VERSION ""

NS_ :

BS_:

BU_: Consumer Producer
VAL_TABLE_ InvertedByte 129 "orig: 126 / 0x7E" 255 "orig: 0 / 0x0" 254 "orig: 1 / 0x1" 253 "orig: 2 / 0x2" 252 "orig: 3 / 0x3" 251 "orig: 4 / 0x4" 250 "orig: 5 / 0x5" 249 "orig: 6 / 0x6" 248 "orig: 7 / 0x7" 247 "orig: 8 / 0x8" 246 "orig: 9 / 0x9" 245 "orig: 10 / 0xA" 244 "orig: 11 / 0xB" 243 "orig: 12 / 0xC" 242 "orig: 13 / 0xD" 241 "orig: 14 / 0xE" 240 "orig: 15 / 0xF" 239 "orig: 16 / 0x10" 238 "orig: 17 / 0x11" 237 "orig: 17 / 0x12" 236 "orig: 19 / 0x13" 235 "orig: 20 / 0x14" 234 "orig: 21 / 0x15" 233 "orig: 22 / 0x16" 232 "orig: 23 / 0x17" 231 "orig: 24 / 0x18" 230 "orig: 25 / 0x19" 229 "orig: 26 / 0x1A" 228 "orig: 27 / 0x1B" 227 "orig: 28 / 0x1C" 226 "orig: 29 / 0x1D" 225 "orig: 30 / 0x1E" 224 "orig: 31 / 0x1F" 223 "orig: 32 / 0x20" 222 "orig: 33 / 0x21" 221 "orig: 34 / 0x22" 220 "orig: 35 / 0x23" 219 "orig: 36 / 0x24" 218 "orig: 37 / 0x25" 217 "orig: 38 / 0x26" 216 "orig: 39 / 0x27" 215 "orig: 40 / 0x28" 214 "orig: 41 / 0x29" 213 "orig: 42 / 0x2A" 212 "orig: 43 / 0x2B" 211 "orig: 44 / 0x2C" 210 "orig: 45 / 0x2D" 209 "orig: 46 / 0x2E" 208 "orig: 47 / 0x2F" 207 "orig: 48 / 0x30" 206 "orig: 49 / 0x31" 205 "orig: 50 / 0x32" 204 "orig: 51 / 0x33" 203 "orig: 52 / 0x34" 202 "orig: 53 / 0x35" 201 "orig: 54 / 0x36" 200 "orig: 55 / 0x37" 199 "orig: 56 / 0x38" 198 "orig: 57 / 0x39" 197 "orig: 58 / 0x3A" 196 "orig: 59 / 0x3B" 195 "orig: 60 / 0x3C" 194 "orig: 61 / 0x3D" 193 "orig: 62 / 0x3E" 192 "orig: 63 / 0x3F" 191 "orig: 64 / 0x40" 190 "orig: 65 / 0x41" 189 "orig: 66 / 0x42" 188 "orig: 67 / 0x43" 187 "orig: 68 / 0x44" 186 "orig: 69 / 0x45" 185 "orig: 70 / 0x46" 184 "orig: 71 / 0x47" 183 "orig: 72 / 0x48" 182 "orig: 73 / 0x49" 181 "orig: 74 / 0x4A" 180 "orig: 75 / 0x4B" 179 "orig: 76 / 0x4C" 178 "orig: 77 / 0x4D" 177 "orig: 78 / 0x4E" 176 "orig: 79 / 0x4F" 175 "orig: 80 / 0x50" 174 "orig: 81 / 0x51" 173 "orig: 82 / 0x52" 172 "orig: 83 / 0x53" 171 "orig: 84 / 0x54" 170 "orig: 85 / 0x55" 169 "orig: 86 / 0x56" 168 "orig: 87 / 0x57" 167 "orig: 88 / 0x58" 166 "orig: 89 / 0x59" 165 "orig: 90 / 0x5A" 164 "orig: 91 / 0x5B" 163 "orig: 92 / 0x5C" 162 "orig: 93 / 0x5D" 161 "orig: 94 / 0x5E" 160 "orig: 95 / 0x5F" 159 "orig: 96 / 0x60" 158 "orig: 97 / 0x61" 157 "orig: 98 / 0x62" 156 "orig: 99 / 0x63" 155 "orig: 100 / 0x64" 154 "orig: 101 / 0x65" 153 "orig: 102 / 0x66" 152 "orig: 103 / 0x67" 151 "orig: 104 / 0x68" 150 "orig: 105 / 0x69" 149 "orig: 106 / 0x6A" 148 "orig: 107 / 0x6B" 147 "orig: 108 / 0x6C" 146 "orig: 109 / 0x6D" 145 "orig: 110 / 0x6E" 144 "orig: 111 / 0x6F" 143 "orig: 112 / 0x70" 142 "orig: 113 / 0x71" 141 "orig: 114 / 0x72" 140 "orig: 115 / 0x73" 139 "orig: 116 / 0x74" 138 "orig: 117 / 0x75" 137 "orig: 118 / 0x76" 136 "orig: 119 / 0x77" 135 "orig: 120 / 0x78" 134 "orig: 121 / 0x79" 133 "orig: 122 / 0x7A" 132 "orig: 123 / 0x7B" 131 "orig: 124 / 0x7C" 130 "orig: 125 / 0x7D" 128 "orig: 127 / 0x7F" 127 "orig: 128 / 0x80" 126 "orig: 129 / 0x81" 125 "orig: 130 / 0x82" 124 "orig: 131 / 0x83" 123 "orig: 132 / 0x84" 122 "orig: 133 / 0x85" 121 "orig: 134 / 0x86" 120 "orig: 135 / 0x87" 119 "orig: 136 / 0x88" 118 "orig: 137 / 0x89" 117 "orig: 138 / 0x8A" 116 "orig: 139 / 0x8B" 115 "orig: 140 / 0x8C" 114 "orig: 141 / 0x8D" 113 "orig: 142 / 0x8E" 112 "orig: 143 / 0x8F" 111 "orig: 144 / 0x90" 110 "orig: 145 / 0x91" 109 "orig: 146 / 0x92" 108 "orig: 147 / 0x93" 107 "orig: 148 / 0x94" 106 "orig: 149 / 0x95" 105 "orig: 150 / 0x96" 104 "orig: 151 / 0x97" 103 "orig: 152 / 0x98" 102 "orig: 153 / 0x99" 101 "orig: 154 / 0x9A" 100 "orig: 155 / 0x9B" 99 "orig: 156 / 0x9C" 98 "orig: 157 / 0x9D" 97 "orig: 158 / 0x9E" 96 "orig: 159 / 0x9F" 95 "orig: 160 / 0xA0" 94 "orig: 161 / 0xA1" 93 "orig: 162 / 0xA2" 92 "orig: 163 / 0xA3" 91 "orig: 164 / 0xA4" 90 "orig: 165 / 0xA5" 89 "orig: 166 / 0xA6" 88 "orig: 167 / 0xA7" 87 "orig: 168 / 0xA8" 86 "orig: 169 / 0xA9" 85 "orig: 170 / 0xAA" 84 "orig: 171 / 0xAB" 83 "orig: 172 / 0xAC" 82 "orig: 173 / 0xAD" 81 "orig: 174 / 0xAE" 80 "orig: 175 / 0xAF" 79 "orig: 176 / 0xB0" 78 "orig: 177 / 0xB1" 77 "orig: 178 / 0xB2" 76 "orig: 179 / 0xB3" 75 "orig: 180 / 0xB4" 74 "orig: 181 / 0xB5" 73 "orig: 182 / 0xB6" 72 "orig: 183 / 0xB7" 71 "orig: 184 / 0xB8" 70 "orig: 185 / 0xB9" 69 "orig: 186 / 0xBA" 68 "orig: 187 / 0xBB" 67 "orig: 188 / 0xBC" 66 "orig: 189 / 0xBD" 65 "orig: 190 / 0xBE" 64 "orig: 191 / 0xBF" 63 "orig: 192 / 0xC0" 62 "orig: 193 / 0xC1" 61 "orig: 194 / 0xC2" 60 "orig: 195 / 0xC3" 59 "orig: 196 / 0xC4" 58 "orig: 197 / 0xC5" 57 "orig: 198 / 0xC6" 56 "orig: 199 / 0xC7" 55 "orig: 200 / 0xC8" 54 "orig: 201 / 0xC9" 53 "orig: 202 / 0xCA" 52 "orig: 203 / 0xCB" 51 "orig: 204 / 0xCC" 50 "orig: 205 / 0xCD" 49 "orig: 206 / 0xCE" 48 "orig: 207 / 0xCF" 47 "orig: 208 / 0xD0" 46 "orig: 209 / 0xD1" 45 "orig: 210 / 0xD2" 44 "orig: 211 / 0xD3" 43 "orig: 212 / 0xD4" 42 "orig: 213 / 0xD5" 41 "orig: 214 / 0xD6" 40 "orig: 215 / 0xD7" 39 "orig: 216 / 0xD8" 38 "orig: 217 / 0xD9" 37 "orig: 218 / 0xDA" 36 "orig: 219 / 0xDB" 35 "orig: 220 / 0xDC" 34 "orig: 221 / 0xDD" 33 "orig: 222 / 0xDE" 32 "orig: 223 / 0xDF" 31 "orig: 224 / 0xE0" 30 "orig: 225 / 0xE1" 29 "orig: 226 / 0xE2" 28 "orig: 227 / 0xE3" 27 "orig: 228 / 0xE4" 26 "orig: 229 / 0xE5" 25 "orig: 230 / 0xE6" 24 "orig: 231 / 0xE7" 23 "orig: 232 / 0xE8" 22 "orig: 233 / 0xE9" 21 "orig: 234 / 0xEA" 20 "orig: 235 / 0xEB" 19 "orig: 236 / 0xEC" 18 "orig: 237 / 0xED" 17 "orig: 238 / 0xEE" 16 "orig: 239 / 0xEF" 15 "orig: 240 / 0xF0" 14 "orig: 241 / 0xF1" 13 "orig: 242 / 0xF2" 12 "orig: 243 / 0xF3" 11 "orig: 244 / 0xF4" 10 "orig: 245 / 0xF5" 9 "orig: 246 / 0xF6" 8 "orig: 247 / 0xF7" 7 "orig: 248 / 0xF8" 6 "orig: 249 / 0xF9" 5 "orig: 250 / 0xFA" 4 "orig: 251 / 0xFB" 3 "orig: 252 / 0xFC" 2 "orig: 253 / 0xFD" 1 "orig: 254 / 0xFE" 0 "orig: 255 / 0xFF" ;
VAL_TABLE_ InvertedBit 1 "orig: 0x0" 0 "orig: 0x1" ;
VAL_TABLE_ FMI 0 "Above normal (most severe)" 1 "Below normal (most severe)" 2 "Data erratic" 3 "Voltage above normal" 4 "Voltage below normal" 5 "Current below normal" 6 "Current above normal" 7 "Mechanical system not responding" 8 "Abnormal frequency" 9 "Abnormal update rate" 10 "Abnormal rate of change" 11 "Root cause not known" 12 "Bad intelligent device" 13 "Out of calibration" 14 "Special intstructions" 15 "Above normal (least severe)" 16 "Above normal (moderately severe)" 17 "Below normal (least severe)" 18 "Below normal (moderately severe)" 19 "Received network data in error" 20 "Data drifted high" 21 "Data drifted low" 31 "Condition exists" ;
VAL_TABLE_ Ports 21 "Global (All ports)" 0 "Local" ;

BO_ 2364538881 Message2: 8 Producer
 SG_ SafetyMessage2_Signal2 : 32|32@1+ (1,0) [0|0] "" Vector__XXX
 SG_ SafetyMessage2_Signal1 : 0|32@1+ (1,0) [0|0] "" Vector__XXX

BO_ 2349859329 Message1: 8 Producer
 SG_ SafetyMessage1_Signal2 : 32|32@1+ (1,0) [0|0] ""  Consumer
 SG_ SafetyMessage1_Signal1 : 0|32@1+ (1,0) [0|0] ""  Consumer

BO_ 2565799425 AC_Producer: 8 Producer
 SG_ ReservedBit : 48|1@1+ (1,0) [0|0] "" Vector__XXX
 SG_ ArbitraryAddressCapable : 63|1@1+ (1,0) [0|1] "" Vector__XXX
 SG_ IndustryGroup M : 60|3@1+ (1,0) [0|7] "" Vector__XXX
 SG_ VehicleSystemInstance : 56|4@1+ (1,0) [0|15] "" Vector__XXX
 SG_ Function : 40|8@1+ (1,0) [0|255] "" Vector__XXX
 SG_ FunctionInstance : 35|5@1+ (1,0) [0|31] "" Vector__XXX
 SG_ ECUInstance : 32|3@1+ (1,0) [0|7] "" Vector__XXX
 SG_ ManufacturerCode : 21|11@1+ (1,0) [0|2047] "" Vector__XXX
 SG_ IdentityNumber : 0|21@1+ (1,0) [0|2097152] "" Vector__XXX
 SG_ VehicleSystem m0 : 49|7@1+ (1,0) [0|127] "" Vector__XXX
 SG_ VehicleSystem5 m5 : 49|7@1+ (1,0) [0|127] "" Vector__XXX
 SG_ VehicleSystem4 m4 : 49|7@1+ (1,0) [0|127] "" Vector__XXX
 SG_ VehicleSystem3 m3 : 49|7@1+ (1,0) [0|127] "" Vector__XXX
 SG_ VehicleSystem2 m2 : 49|7@1+ (1,0) [0|127] "" Vector__XXX
 SG_ VehicleSystem1 m1 : 49|7@1+ (1,0) [0|127] "" Vector__XXX

BO_ 2565799426 AC_Consumer: 8 Consumer
 SG_ ReservedBit : 48|1@1+ (1,0) [0|0] "" Vector__XXX
 SG_ ArbitraryAddressCapable : 63|1@1+ (1,0) [0|1] "" Vector__XXX
 SG_ IndustryGroup M : 60|3@1+ (1,0) [0|7] "" Vector__XXX
 SG_ VehicleSystemInstance : 56|4@1+ (1,0) [0|15] "" Vector__XXX
 SG_ Function : 40|8@1+ (1,0) [0|255] "" Vector__XXX
 SG_ FunctionInstance : 35|5@1+ (1,0) [0|31] "" Vector__XXX
 SG_ ECUInstance : 32|3@1+ (1,0) [0|7] "" Vector__XXX
 SG_ ManufacturerCode : 21|11@1+ (1,0) [0|2047] "" Vector__XXX
 SG_ IdentityNumber : 0|21@1+ (1,0) [0|2097152] "" Vector__XXX
 SG_ VehicleSystem m0 : 49|7@1+ (1,0) [0|127] "" Vector__XXX
 SG_ VehicleSystem5 m5 : 49|7@1+ (1,0) [0|127] "" Vector__XXX
 SG_ VehicleSystem4 m4 : 49|7@1+ (1,0) [0|127] "" Vector__XXX
 SG_ VehicleSystem3 m3 : 49|7@1+ (1,0) [0|127] "" Vector__XXX
 SG_ VehicleSystem2 m2 : 49|7@1+ (1,0) [0|127] "" Vector__XXX
 SG_ VehicleSystem1 m1 : 49|7@1+ (1,0) [0|127] "" Vector__XXX

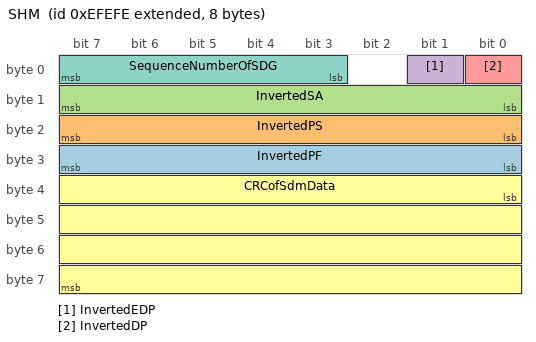
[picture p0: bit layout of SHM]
BO_ 2148466430 SHM: 8 Vector__XXX
 SG_ InvertedPF : 24|8@1+ (-1,255) [0|0] "" Vector__XXX
 SG_ InvertedPS : 16|8@1+ (-1,255) [0|0] "" Vector__XXX
 SG_ InvertedSA : 8|8@1+ (-1,255) [0|0] "" Vector__XXX
 SG_ InvertedEDP : 1|1@1+ (-1,1) [0|0] "" Vector__XXX
 SG_ InvertedDP : 0|1@1+ (-1,1) [0|0] "" Vector__XXX
 SG_ CRCofSdmData : 32|32@1+ (1,0) [0|0] "" Vector__XXX
 SG_ SequenceNumberOfSDG : 3|5@1+ (1,0) [0|0] "" Vector__XXX

BO_ 2565799678 AC: 8 Vector__XXX
 SG_ ReservedBit : 48|1@1+ (1,0) [0|0] "" Vector__XXX
 SG_ ArbitraryAddressCapable : 63|1@1+ (1,0) [0|1] "" Vector__XXX
 SG_ IndustryGroup M : 60|3@1+ (1,0) [0|7] "" Vector__XXX
 SG_ VehicleSystemInstance : 56|4@1+ (1,0) [0|15] "" Vector__XXX
 SG_ Function : 40|8@1+ (1,0) [0|255] "" Vector__XXX
 SG_ FunctionInstance : 35|5@1+ (1,0) [0|31] "" Vector__XXX
 SG_ ECUInstance : 32|3@1+ (1,0) [0|7] "" Vector__XXX
 SG_ ManufacturerCode : 21|11@1+ (1,0) [0|2047] "" Vector__XXX
 SG_ IdentityNumber : 0|21@1+ (1,0) [0|2097152] "" Vector__XXX
 SG_ VehicleSystem m0 : 49|7@1+ (1,0) [0|127] "" Vector__XXX
 SG_ VehicleSystem5 m5 : 49|7@1+ (1,0) [0|127] "" Vector__XXX
 SG_ VehicleSystem4 m4 : 49|7@1+ (1,0) [0|127] "" Vector__XXX
 SG_ VehicleSystem3 m3 : 49|7@1+ (1,0) [0|127] "" Vector__XXX
 SG_ VehicleSystem2 m2 : 49|7@1+ (1,0) [0|127] "" Vector__XXX
 SG_ VehicleSystem1 m1 : 49|7@1+ (1,0) [0|127] "" Vector__XXX

CM_ BO_ 2565799425 "Address Claimed
Message used to claim an address for a Controller Application.";
CM_ SG_ 2565799425 IndustryGroup "0 = Global; 
   1  = On-Highway; 
   2  = Agricultural and Forestry; 
   3  = Construction; 
   4  = Marine;
   5  = Industrial - Process
          Control - Stationary (Gen-Sets)
   6  = Reserve for SAE
   7  = Reserve for SAE";
CM_ SG_ 2565799425 ManufacturerCode "Assigned by NMEA 2000 Committee";
CM_ BO_ 2565799426 "Address Claimed
Message used to claim an address for a Controller Application.";
CM_ SG_ 2565799426 IndustryGroup "0 = Global; 
   1  = On-Highway; 
   2  = Agricultural and Forestry; 
   3  = Construction; 
   4  = Marine;
   5  = Industrial - Process
          Control - Stationary (Gen-Sets)
   6  = Reserve for SAE
   7  = Reserve for SAE";
CM_ SG_ 2565799426 ManufacturerCode "Assigned by NMEA 2000 Committee";
CM_ SG_ 2148466430 InvertedPF "Inverted PDU Format of SDM";
CM_ SG_ 2148466430 InvertedPS "Inverted PDU Specific of SDM";
CM_ SG_ 2148466430 InvertedSA "Inverted Source Address of SDM";
CM_ SG_ 2148466430 InvertedEDP "Inverted Extended Data Page of SDM";
CM_ SG_ 2148466430 InvertedDP "Inverted Data Page of SDM";
CM_ SG_ 2148466430 CRCofSdmData "32-bit CRC of the data field of SDM";
CM_ SG_ 2148466430 SequenceNumberOfSDG "Sequence Number of Safety Data Group";
CM_ BO_ 2565799678 "Address Claimed
Message used to claim an address for a Controller Application.";
CM_ SG_ 2565799678 IndustryGroup "0 = Global; 
   1  = On-Highway; 
   2  = Agricultural and Forestry; 
   3  = Construction; 
   4  = Marine;
   5  = Industrial - Process
          Control - Stationary (Gen-Sets)
   6  = Reserve for SAE
   7  = Reserve for SAE";
CM_ SG_ 2565799678 ManufacturerCode "Assigned by NMEA 2000 Committee";
BA_DEF_ BO_  "FsJ1939Delay" INT 0 1000;
BA_DEF_ BO_  "FsJ1939NeedsSHM" ENUM  "No","Yes";
BA_DEF_ SG_  "SigType" ENUM  "Default","Range","RangeSigned","ASCII","Discrete","Control","ReferencePGN","DTC","StringDelimiter","StringLength","StringLengthControl","MessageCounter","MessageChecksum";
BA_DEF_ SG_  "GenSigStartValue" INT 0 2147483647;
BA_DEF_ SG_  "GenSigSendType" ENUM  "Cyclic","OnWrite","OnWriteWithRepetition","OnChange","OnChangeWithRepetition","IfActive","IfActiveWithRepetition","NoSigSendType";
BA_DEF_ SG_  "GenSigILSupport" ENUM  "No","Yes";
BA_DEF_ SG_  "GenSigEVName" STRING ;
BA_DEF_ SG_  "SPN" INT 0 524287;
BA_DEF_ BO_  "GenMsgILSupport" ENUM  "No","Yes";
BA_DEF_ BO_  "GenMsgDelayTime" INT 0 1000;
BA_DEF_ BO_  "GenMsgRequestable" INT 0 1;
BA_DEF_ BO_  "GenMsgSendType" ENUM  "cyclic","NotUsed","NotUsed","NotUsed","NotUsed","NotUsed","NotUsed","IfActive","noMsgSendType";
BA_DEF_ BO_  "VFrameFormat" ENUM  "StandardCAN","ExtendedCAN","reserved","J1939PG";
BA_DEF_ BO_  "GenMsgCycleTime" INT 0 3600000;
BA_DEF_ BU_  "NodeLayerModules" STRING ;
BA_DEF_ BU_  "NmStationAddress" INT 0 255;
BA_DEF_ BU_  "NmJ1939Function" INT 0 255;
BA_DEF_ BU_  "NmJ1939ManufacturerCode" INT 0 2047;
BA_DEF_ BU_  "NmJ1939IdentityNumber" INT 0 2097151;
BA_DEF_  "SAE_J1939_DA_SpecVersion" STRING ;
BA_DEF_  "SAE_J1939_81_SpecVersion" STRING ;
BA_DEF_  "DatabaseVersion" STRING ;
BA_DEF_  "BusType" STRING ;
BA_DEF_  "ProtocolType" STRING ;
BA_DEF_  "SAE_J1939_75_SpecVersion" STRING ;
BA_DEF_  "SAE_J1939_21_SpecVersion" STRING ;
BA_DEF_  "SAE_J1939_73_SpecVersion" STRING ;
BA_DEF_  "SAE_J1939_71_SpecVersion" STRING ;
BA_DEF_DEF_  "FsJ1939Delay" 0;
BA_DEF_DEF_  "FsJ1939NeedsSHM" "No";
BA_DEF_DEF_  "SigType" "Default";
BA_DEF_DEF_  "GenSigStartValue" 0;
BA_DEF_DEF_  "GenSigSendType" "NoSigSendType";
BA_DEF_DEF_  "GenSigILSupport" "Yes";
BA_DEF_DEF_  "GenSigEVName" "Env@Nodename_@Signame";
BA_DEF_DEF_  "SPN" 0;
BA_DEF_DEF_  "GenMsgILSupport" "Yes";
BA_DEF_DEF_  "GenMsgDelayTime" 0;
BA_DEF_DEF_  "GenMsgRequestable" 1;
BA_DEF_DEF_  "GenMsgSendType" "noMsgSendType";
BA_DEF_DEF_  "VFrameFormat" "J1939PG";
BA_DEF_DEF_  "GenMsgCycleTime" 0;
BA_DEF_DEF_  "NodeLayerModules" "";
BA_DEF_DEF_  "NmStationAddress" 254;
BA_DEF_DEF_  "NmJ1939Function" 0;
BA_DEF_DEF_  "NmJ1939ManufacturerCode" 0;
BA_DEF_DEF_  "NmJ1939IdentityNumber" 0;
BA_DEF_DEF_  "SAE_J1939_DA_SpecVersion" "";
BA_DEF_DEF_  "SAE_J1939_81_SpecVersion" "";
BA_DEF_DEF_  "DatabaseVersion" "";
BA_DEF_DEF_  "BusType" "";
BA_DEF_DEF_  "ProtocolType" "";
BA_DEF_DEF_  "SAE_J1939_75_SpecVersion" "";
BA_DEF_DEF_  "SAE_J1939_21_SpecVersion" "";
BA_DEF_DEF_  "SAE_J1939_73_SpecVersion" "";
BA_DEF_DEF_  "SAE_J1939_71_SpecVersion" "";
BA_ "SAE_J1939_71_SpecVersion" "2020-02";
BA_ "SAE_J1939_73_SpecVersion" "2019-01";
BA_ "SAE_J1939_21_SpecVersion" "2018-10";
BA_ "SAE_J1939_75_SpecVersion" "2015-11";
BA_ "ProtocolType" "J1939";
BA_ "BusType" "CAN";
BA_ "DatabaseVersion" "13.0";
BA_ "SAE_J1939_81_SpecVersion" "2017-03";
BA_ "SAE_J1939_DA_SpecVersion" "2020-01";
BA_ "NmJ1939Function" BU_ Consumer 128;
BA_ "NmJ1939ManufacturerCode" BU_ Consumer 1861;
BA_ "NmJ1939IdentityNumber" BU_ Consumer 2;
BA_ "NmStationAddress" BU_ Consumer 2;
BA_ "NodeLayerModules" BU_ Consumer "J1939_IL.vmodule";
BA_ "NmJ1939Function" BU_ Producer 128;
BA_ "NmJ1939ManufacturerCode" BU_ Producer 1861;
BA_ "NmJ1939IdentityNumber" BU_ Producer 1;
BA_ "NmStationAddress" BU_ Producer 1;
BA_ "NodeLayerModules" BU_ Producer "J1939_IL.vmodule";
BA_ "FsJ1939Delay" BO_ 2364538881 30;
BA_ "FsJ1939NeedsSHM" BO_ 2364538881 1;
BA_ "GenMsgDelayTime" BO_ 2364538881 40;
BA_ "GenMsgSendType" BO_ 2364538881 0;
BA_ "GenMsgCycleTime" BO_ 2364538881 1000;
BA_ "GenMsgCycleTime" BO_ 2349859329 1000;
BA_ "GenMsgSendType" BO_ 2349859329 0;
BA_ "GenMsgDelayTime" BO_ 2349859329 100;
BA_ "FsJ1939NeedsSHM" BO_ 2349859329 1;
BA_ "FsJ1939Delay" BO_ 2349859329 10;
BA_ "SPN" SG_ 2565799425 ArbitraryAddressCapable 2844;
BA_ "SPN" SG_ 2565799425 IndustryGroup 2846;
BA_ "SPN" SG_ 2565799425 VehicleSystemInstance 2843;
BA_ "SPN" SG_ 2565799425 Function 2841;
BA_ "SPN" SG_ 2565799425 FunctionInstance 2839;
BA_ "SPN" SG_ 2565799425 ECUInstance 2840;
BA_ "SPN" SG_ 2565799425 ManufacturerCode 2838;
BA_ "SigType" SG_ 2565799425 ManufacturerCode 1;
BA_ "SPN" SG_ 2565799425 IdentityNumber 2837;
BA_ "SPN" SG_ 2565799426 ArbitraryAddressCapable 2844;
BA_ "SPN" SG_ 2565799426 IndustryGroup 2846;
BA_ "SPN" SG_ 2565799426 VehicleSystemInstance 2843;
BA_ "SPN" SG_ 2565799426 Function 2841;
BA_ "SPN" SG_ 2565799426 FunctionInstance 2839;
BA_ "SPN" SG_ 2565799426 ECUInstance 2840;
BA_ "SPN" SG_ 2565799426 ManufacturerCode 2838;
BA_ "SigType" SG_ 2565799426 ManufacturerCode 1;
BA_ "SPN" SG_ 2565799426 IdentityNumber 2837;
BA_ "GenSigStartValue" SG_ 2148466430 InvertedPF 255;
BA_ "GenSigStartValue" SG_ 2148466430 InvertedPS 255;
BA_ "GenSigStartValue" SG_ 2148466430 InvertedSA 255;
BA_ "GenSigStartValue" SG_ 2148466430 InvertedEDP 1;
BA_ "GenSigStartValue" SG_ 2148466430 InvertedDP 1;
BA_ "SPN" SG_ 2565799678 ArbitraryAddressCapable 2844;
BA_ "SPN" SG_ 2565799678 IndustryGroup 2846;
BA_ "SPN" SG_ 2565799678 VehicleSystemInstance 2843;
BA_ "SPN" SG_ 2565799678 Function 2841;
BA_ "SPN" SG_ 2565799678 FunctionInstance 2839;
BA_ "SPN" SG_ 2565799678 ECUInstance 2840;
BA_ "SPN" SG_ 2565799678 ManufacturerCode 2838;
BA_ "SigType" SG_ 2565799678 ManufacturerCode 1;
BA_ "SPN" SG_ 2565799678 IdentityNumber 2837;
VAL_ 2565799425 IndustryGroup 6 "Reserved for SAE" 7 "Reserved for SAE" 5 "IndustrialProcessCtrlStationary" 4 "Marine" 3 "Construction" 2 "Agricultural and Forestry" 1 "On-Highway" 0 "Global" ;
VAL_ 2565799425 Function 127 "Reserved" 126 "Reserved" 125 "Reserved" 124 "Reserved" 123 "Reserved" 122 "Reserved" 121 "Reserved" 120 "Reserved" 119 "Reserved" 118 "Reserved" 117 "Reserved" 116 "Reserved" 115 "Reserved" 114 "Reserved" 113 "Reserved" 112 "Reserved" 111 "Reserved" 110 "Reserved" 109 "Reserved" 108 "Reserved" 107 "Reserved" 106 "Reserved" 105 "Reserved" 104 "Reserved" 103 "Reserved" 102 "Reserved" 101 "Reserved" 42 "Water Pump Control" 41 "Lighting - Operator Controls" 40 "Seat Control" 39 "Ignition Control Module" 38 "Tire Pressure Control" 37 "Cab Controller" 36 "Pneumatic - System Controller" 35 "Suspension - System Controller" 34 "Hydraulic Pump Controller" 33 "System Monitor" 32 "Headway Controller" 31 "Propulsion Battery Charger" 30 "Management Computer" 29 "Virtual Terminal (in cab)" 28 "Off Vehicle Gateway" 27 "Power TakeOff (Secondary or Front)" 26 "Body Controller" 25 "Network Interconnect ECU" 24 "Vehicle Security" 23 "Vehicle Navigation" 22 "Aerodynamic Control" 21 "Cab Climate Control" 20 "Trip Recorder" 19 "Instrument Cluster" 18 "Suspension - Drive Axle" 17 "Suspension - Steer Axle" 16 "Steering Controller" 15 "Fuel System" 14 "Cruise Control" 13 "Retarder - Driveline" 12 "Retarder - Engine" 11 "Brakes - Drive Axle" 10 "Brakes - Steer Axle" 9 "Brakes - System Controller" 8 "Axle - Drive" 7 "Axle - Steering" 6 "Power TakeOff - (Main or Rear)" 5 "Shift Control/Console" 4 "Battery Pack Monitor" 3 "Transmission" 2 "Electric Propulsion Control" 1 "Auxiliary Power Unit (APU)" 0 "Engine" 100 "Reserved" 99 "Reserved" 98 "Reserved" 97 "Reserved" 96 "Reserved" 95 "Reserved" 94 "Reserved" 93 "Reserved" 92 "Reserved" 91 "Reserved" 90 "Reserved" 89 "Reserved" 88 "Reserved" 87 "Reserved" 86 "Reserved" 85 "Reserved" 84 "Reserved" 83 "Reserved" 82 "Reserved" 81 "Reserved" 80 "Reserved" 79 "Reserved" 78 "Fire Suppression System" 77 "Fuel Properties Sensor" 76 "Temperature Sensor" 75 "Supplemental Fan" 74 "Lubrication System" 73 "Rollover Detection Control" 72 "Coolant Valve Controller" 71 "Transfer Case Control" 70 "Auxiliary Regeneration Device" 69 "Engine Emission Aftertreatement System" 68 "Aftertreatment system gas measurement" 67 "Electrical System Controller" 66 "I/O Controller" 65 "Gas Flow Measurement" 64 "Endurance Braking" 63 "Engine Valve Controller" 62 "On-Board Diagnostic Unit" 61 "File Server/Printer" 60 "Cab Display" 59 "Starter" 58 "Fan Drive Control" 57 "Steering Column Unit" 56 "Communications Unit, Radio" 55 "Communications Unit, Satellite" 54 "Communications Unit, Cellular" 53 "Alternator/Charging System" 52 "Chassis Controller" 51 "Forward-Looking Collision Warning System" 50 "Auxiliary Heater" 49 "Clutch/Converter Control" 48 "Ramp Control" 47 "Information System Controller" 46 "Oil Sensor Unit" 45 "Vehicle Dynamic Stability Control" 44 "Exhaust Emission Control" 43 "Transmission Display" ;
VAL_ 2565799425 ManufacturerCode 900 "OSB AG" 899 "Lippert Components, Inc" 898 "Josef Kotte Landtechnik GmbH & Co. KG" 897 "Dot Technology Corp." 896 "NextFour Solutions Ltd" 895 "Peloton Technology" 894 "Rhodan Marine Systems of Florida LLC" 893 "KlinkTechnics Ltd." 892 "Mectronx Corp" 891 "CarrierWeb" 890 "L3 Technologies, Inc." 889 "SANY America Inc" 888 "Carma Systems Inc" 887 "Hyperdrive Innovation Limited" 886 "Hitachi Zosen Corporation" 885 "SICK Stegmann GmbH" 884 "Sure Grip Controls Inc." 883 "Swift Navigation, Inc." 882 "BHTronik GmbH & Co. KG" 881 "Sovema" 880 "Revision Military" 879 "PG Trionic, Inc." 878 "FOTON" 877 "SICK ATech GmbH" 876 "SUCO Robert Scheuffele GmbH & Co. KG" 875 "Salvarani S.r.l." 874 "MTA S.p.A." 873 "Garnet Instruments Ltd." 872 "Kählig Antriebstechnik GmbH" 871 "Superior Tech Inc" 870 "Textron Fleet Management" 869 "Intercomp" 868 "Data Panel Corp" 867 "Skeleton Technologies" 866 "Netradyne, Inc." 865 "MyEasyFarm" 864 "Streamline Transportation Technologies Inc." 863 "SMAG" 862 "Prospec Electronics" 861 "Adel System S.r.l." 860 "Michelin" 859 "Valor" 858 "Littelfuse" 857 "Zoomlion Heavy Industry NA, Inc" 856 "FarmFacts GmbH" 855 "Toshiba Infrastructure Systems & Solutions Corporation" 854 "GEMAC Chemnitz GmbH" 853 "Teledyne RESON B.V." 852 "Velvac Inc" 851 "Novotechnik Messwertaufnehmer OHG" 850 "Geoprospectors GmbH" 849 "MTS Maschinentechnik Schrode AG" 848 "ningupex" 1863 "Thomas G. Faria Co." 1862 "Sanshin" 1861 "Vector North America (formerly Vector Cantech)" 1860 "MMP" 1859 "Kvasar AB" 1858 "Litton" 1857 "Simrad" 1856 "Trimble" 1855 "Furuno USA" 1854 "Northstar Technologies" 1853 "Japan Radio Co" 1852 "Navionics" 1851 "RayMarine" 1850 "Seastar Solutions (formerly Teleflex)" 1569 "621 Technologies Inc." 1077 "Ymer Technology" 1076 "DOGA S.A." 1075 "Uniden America Corporation" 1074 "Kindhelm / Navigs Oy" 1073 "Manitou Equipment America LLC" 1072 "La Marche Manufacturing Company" 1071 "MACH SYSTEMS s.r.o." 1070 "Quick-teck Electronics Ltd" 1069 "Lithionics Battery LLC" 1068 "Zapi S.p.A." 1067 "Tecomec S.r.l." 1066 "Spot Zero Water" 1065 "CALYPSO Instruments" 1064 "Omnitech Robotics Inc." 1063 "SolSteer" 1062 "Marol Co Ltd" 1061 "Volvo Construction Equipment" 1060 "Scale-Tec" 1059 "Boatrax" 1058 "Bondioli & Pavesi SpA" 1057 "EquipmentShare" 1056 "Lithium Pros" 1055 "EXA Computing GmbH" 1054 "Schmotzer Hacktechnik GmbH & Co. KG" 1053 "Vetus Maxwell, Inc." 1052 "Pfreundt" 1051 "ProNav AS" 1050 "Spacenus GmbH" 1049 "S&S Cycle" 1048 "Agrivation UG" 1047 "Sonic Corporation" 1046 "Praxidyn" 1045 "CMR Group" 1044 "Xee" 1043 "Hyva" 1042 "engcon group" 1041 "EZ Lynk" 1040 "BPE Electronics Srl" 1039 "Liugong Dressta Machinery" 1038 "EMIT Technologies, Inc." 1037 "Dragonfly Energy Corp." 1036 "Bender GmbH & Co. KG" 1035 "Agres" 1034 "Siren Marine" 1033 "ECCO Safety Group" 1032 "SIMOL S.p.A." 1031 "Flintec UK Ltd." 1030 "Tume-Agri Oy" 1029 "The Marine Guardian LLC" 1028 "Autel Intelligent Technology Corp., Ltd" 1027 "Goldacres PTY LTD" 1026 "ZTR Control Systems, LLC" 1025 "eze System, Inc." 1024 "Inventus Power" 1023 "PEAK-System Technik GmbH" 1022 "ITC Inc" 1021 "Entratech Systems LLC" 1020 "Onyx Marine Automation s.r.l." 1019 "Codek Foundries" 1018 "Flex TTS" 1017 "Caldaro AB" 1016 "Röhren- und Pumpenwerk BAUER GmbH" 1015 "SECURITAG SAS" 1014 "Briri Maschinenbau GmbH" 1013 "Allochis E-Tec" 1012 "Rhodan Marine Systems of Florida LLC" 1011 "Soundmax Electronics Ltd" 1010 "Agricultural Industry Electronics Foundation e.V." 1009 "TouchTronics, Inc." 1008 "Lintest Systems LLC" 1007 "Maschinenfabrik Meyer-Lohne GmbH" 1006 "Proterra" 1005 "TSE Brakes, Inc." 1004 "Ultraflex SpA" 1003 "technotrans SE" 1002 "Kussmaul Electronics Co." 1001 "Cleral Inc." 1000 "Landmaschinen Wienhoff GmbH" 999 "TerraTroniq B.V." 998 "Transcell Technology Inc" 997 "Xenta Systems Srl" 996 "Eniquest Pty Ltd" 995 "Circuitlink Pty Ltd." 994 "Morris Industries Ltd." 993 "Alelion Energy Systems AB" 992 "MarineIOT LLC" 991 "Deutronic Elektronik GmbH" 990 "SAMSUNG SDI Co., Ltd." 989 "Flux-Geräte GmbH" 988 "Voith Turbo" 987 "Baltic Car Equipment" 986 "AAMP Global" 985 "NLR, LLC" 984 "E-T-A Elektrotechnische Apparate GmbH" 983 "Dezwaef NV" 982 "Briggs & Stratton Corporation" 981 "Kobelt Manufacturing Co. Ltd" 980 "Gussi Italia S.R.L." 979 "McHale" 978 "Canfield Connector" 977 "Emerson Electric Co." 976 "Derive Systems, Inc." 975 "Siemens AG" 974 "Pico Technology Limited" 973 "Zasso GmbH" 972 "Axion AG" 971 "B+B Smartworx" 970 "Jaboni Power Products, LLC" 969 "Blue Sea Systems" 968 "Cox Powertrain Limited" 967 "Moteck Electric Corp." 966 "VisibleFarm" 965 "Ro-Sys Software" 964 "AgroVIR Kft" 963 "Thomason Jones Company, LLC" 962 "Timbolier Industries, Inc." 961 "POK SAS" 960 "Vemcon GmbH" 959 "Cascade Corporation" 958 "NHK MEC Corporation" 957 "Sierra Wireless Inc" 956 "Piher Sensors & Controls S.A." 955 "Hottinger Baldwin (Suzhou) Electronic Measurement Technology Co., Ltd." 954 "Setec Pty Ltd" 953 "Curtiss-Wright" 952 "Tan Delta Systems Ltd" 951 "Exor International S.p.A." 950 "RE:Lab s.r.l." 949 "Škoda Electric a.s." 948 "Donix" 947 "Gerd Bär GmbH" 946 "Hydac Tecnologia Ltda" 945 "Equalizer AG" 944 "ZONTISA Marine SL" 943 "FISCHER AG Präzisionspindeln" 942 "Vogelsang GmbH & Co. KG" 941 "Navya" 940 "Dometal Oy" 939 "Warn Industries, Inc." 938 "LEVEL Systems" 937 "Precision Circuits Inc" 936 "Hi-tech Millennium" 935 "Meels GmbH & Co. KG" 934 "Farmobile, Inc." 933 "Delta Mobile Systems, Inc." 932 "Discover Battery" 931 "Enertec Marine Ltd" 930 "Ecotronix Corp." 929 "Jl Marine Systems, Inc." 928 "EAO Automotive GmbH & Co. KG" 927 "Saicon" 926 "Buhler Industries Inc." 925 "GW Lisk Company" 924 "PAS Peschak Autonome Systeme GmbH" 923 "ELTEK S.p.A." 922 "Terberg Benschop B.V." 921 "ROPA Fahrzeug- und Maschinenbau GmbH" 920 "MTD Consumer Group Inc." 919 "Furrion LLC" 918 "AMW Machine Control, Inc" 917 "Sentinel d.o.o." 916 "Turck Inc." 915 "Dosificacion y sistemas electronicos S.L. (DSE)" 914 "ZETOR TRACTORS a.s." 913 "Toyota Motor Corporation" 912 "Steyr Motors GmbH" 911 "Nautic-On" 910 "Hermann Paus Maschinenfabrik GmbH" 909 "Marines Co., Ltd." 908 "Chonbuk National University Department of Electronics" 907 "strautmann" 906 "MOBA AG" 905 "ASA Electronics" 904 "Equipment Safety Systems Pty. Ltd. (EQSS)" 903 "InMotion" 902 "Bucher Hydraulics" 901 "Zivan Srl" 847 "Oceanvolt" 846 "L3 Magnet-Motor" 845 "GMB Güstrower Maschinenbau GmbH" 844 "FELL AS" 843 "Hendrickson Truck Commercial Vehicle Systems" 842 "DigiDevice Srl" 841 "Agra-GPS" 840 "E.S.T.E. Srl" 839 "Indexator Rotator Systems AB" 838 "Teamsurv Ltd" 837 "Famic Technologies Inc." 836 "Signature4" 835 "PetTrack Ltd." 834 "Pioneer Microsystems, Inc." 833 "Electrum Automation AB" 832 "Heizomat Gerätebau-Energiesysteme GmbH" 831 "DOK-ING Ltd." 830 "Ultra Motion LLC" 829 "Drov Technologies, Inc." 828 "AgriBrink Inc." 827 "INmatix Technology Group Ltd" 826 "Lewmar Marine Inc" 825 "BPW Hungária" 824 "Undheim Systems AS" 823 "ACEINNA, Inc (formerly MEMSIC, Inc)" 822 "Bren-Tronics, Inc." 821 "Thorsen Teknik A/S" 820 "DIaLOGIKa Gesellschaft fuer angewandte Informatik mbH" 819 "Preco Electronics" 818 "HGNSS" 817 "TE Connectivity Sensor Solutions" 816 "UniStrong" 815 "FLIR Systems, Inc." 814 "Kronotech Srl (formerly Soltec Soluzioni Tecnologiche Srl)" 813 "Thales Suisse SA" 812 "Torch Technologies" 811 "Blue Water Desalination" 810 "Dutch Power Company" 809 "HMS Industrial Networks AB" 808 "RIMEX Supply Ltd." 807 "Schneider-Electric" 806 "Charge Automotive Ltd" 805 "Gundersen & Løken AS" 804 "ASA Electronics" 803 "Gill Sensors & Controls Limited" 802 "SPBI (Bj Technologie)" 801 "LOR Manufacturing Company Inc." 800 "Delta-Q Technologies" 799 "Stillwater Designs and Audio, Inc. - KICKER" 798 "Lumishore Ltd" 797 "Tides Marine" 796 "Canadian Automotive Industries Ltd" 795 "Broyda Enterprises Pty Ltd" 794 "Shihlin Electric & Engineering Corporation" 793 "James Fisher Prolec" 792 "Kostal Mexicana" 791 "AUTEC" 790 "VACALL" 789 "GRADALL" 788 "MoTeC Pty Ltd" 787 "Abertax Technologies Limited" 786 "Johnson Matthey Battery Systems" 785 "Fischer Panda GmbH" 784 "CM Automotive Systems, Inc." 783 "Loup Electronics Inc." 782 "AVR bv (formerly AVR bvba)" 781 "Poly-Planar LLC" 780 "AVID Technology Ltd" 779 "RLC Electronic Systems" 778 "Seakeeper Inc." 777 "Ocean Signal Ltd" 776 "HMI Systems LLC" 775 "ZIEHL-ABEGG Automotive GmbH" 774 "Taisho Corporation" 773 "Clarion Corporation of America" 772 "Blink Marine" 771 "Shaw Development, LLC" 770 "MONOSEM" 769 "Trombetta" 768 "Flores Automation, LLC" 767 "Alliance Wireless Technologies Inc." 766 "Epec Oy" 765 "GIGAVAC" 764 "Bednar FMT s.r.o." 763 "AT-Systems BVBA" 762 "ROJ s.r.l." 761 "MITA OLEODINAMICA S.p.A." 760 "Bernecker + Rainer Industrie Elektronik GmbH" 759 "Hydro-Gear" 758 "Banner Engineering Corp." 757 "IMPCO Technologies" 756 "Maschio Gaspardo S.P.A." 755 "Firefly Integrations" 754 "Parker Hannifin Corp., Automation Group" 753 "AIROD Technologies" 752 "Deep Sea Electronics Plc" 751 "Pacific Track" 750 "Joskin SA" 749 "Chart Inc." 748 "ISOTTA" 747 "Agratronix" 746 "SureFire Ag Systems, Inc." 745 "Cidra Corporate Services Inc." 644 "KUS USA" 643 "Bogballe A/S" 642 "Moog / Aspen Motion Technologies" 641 "Diverse Yacht Services" 640 "Power Solutions International" 639 "Startec s.r.l." 638 "KVH Industries, Inc." 637 "Bavaria Yachtbau GmbH" 636 "Divelbiss Corporation" 635 "Argo Tractors S.p.A." 634 "Rocky Research" 633 "TORC Robotics" 632 "Pepperl+Fuchs GmbH" 631 "Reltima" 630 "SmartDrive Systems Inc." 629 "Agri Info Design, Ltd." 628 "Falck Schmidt Defence Systems" 627 "Radio Ocean" 626 "AVL DiTEST GmbH" 625 "Global MRV Inc." 624 "Blackbox Machine Control Pty Ltd" 623 "Xirgo Technologies" 622 "Floyd Bell Inc" 621 "Hagie Manufacturing Company" 620 "Sevcon Ltd." 619 "Right Weigh Load Scales" 618 "Evrard SA" 617 "Zero Emission Vehicles" 616 "SMART-TEC s.r.o." 615 "Networkfleet, Verizon Telematics" 614 "ARLT Technologies GmbH" 613 "HKS Co., Ltd." 612 "Samwon IT" 611 "Esterline" 610 "Trail Tech" 609 "Walvoil S.p.A." 608 "Gale Banks Engineering" 607 "Knappco/Civacon" 606 "Intellian Technologies" 605 "Aventics GmbH" 604 "Indexator Rototilt Systems AB" 603 "Kereval" 602 "Nomad Digital Ltd." 601 "Navitas Systems" 600 "Aquatic AV" 599 "Spudnik Equipment Co, LLC" 598 "ABB Turbo Systems Ltd" 597 "Hydac Filter Systems GmbH" 596 "Brunelco Electronic Innovators B.V." 595 "CustomWare" 594 "Kongsberg Automotive" 593 "Sensata Technologies" 592 "tecsis GmbH" 591 "United States Coast Guard" 382 "National Agriculture and Food Research Organization" 381 "B & G" 380 "Suntech International Ltd." 379 "Yamabiko Corporation" 378 "Glendinning Marine Products" 377 "ifm electronic gmbh" 376 "Quake Global" 375 "Williams Controls Inc." 374 "Northern Lights, Inc." 373 "Electronic Design Inc." 372 "Delphi" 371 "Heinzmann GmbH & Co. KG" 370 "Rolls-Royce Marine AS" 369 "Power Torque Engineering Ltd" 368 "HANSENHOF_electronic" 367 "Fliegl Agrartechnik" 366 "Viewnyx Corp." 365 "Digi-Star, LLC" 364 "OEM Controls Inc." 363 "BEI Duncan" 362 "Poettinger Landtechnik GmbH (formerly Alois Poettinger Maschinenfabrik GmbH)" 361 "InMach" 360 "HJS Emission Technology GmbH & Co KG   (formerly HJS Fahrzeugtechnik GmbH & Co KG)" 359 "Ludwig Bergmann GmbH" 358 "Victron Energy B.V." 357 "Hardi International A/S" 356 "Fischer Panda Generators, Inc" 355 "Mastervolt International B.V." 354 "Junkkari OY" 353 "Hegemon Electronics, Inc." 352 "SAME DEUTZ-FAHR GROUP S.p.A." 351 "Thrane & Thrane" 350 "Noris Marine Systems GmbH & Co KG" 349 "Suonentieto" 348 "Amazonen Werke H. Dreyer" 347 "Honeywell" 346 "Control Solutions" 345 "Korean Maritime University" 344 "Parvus Corporation" 343 "Baumer Group" 342 "THOMAS MAGNETE GmbH" 341 "Boning GmbH & Co" 340 "Continental AG" 339 "Competence Center ISOBUS e.V." 338 "GRAF-SYTECO" 337 "Carraro S.p.A." 336 "APE s.r.o." 335 "Evo Electric Ltd" 334 "Takata-Petri AG" 333 "Hadley Products Corporation" 744 "Woosung Engineering Co., Ltd." 743 "Daemyung Elevator Co., Ltd." 742 "EROAD" 741 "Carling Technologies" 740 "e-Traction" 739 "LXNAV d.o.o." 738 "Blue Ink Technologies" 737 "Balluff GmbH" 736 "Terex Aerial Work Platforms - Genie" 735 "AEM Performance Electronics" 734 "REAPsystems" 733 "Intendia S.L." 732 "Gefran S.p.A." 731 "Modine Manufacturing Company" 730 "BERTHOUD AGRICOLE" 729 "Liebherr" 728 "Streumaster (formerly Streumaster / Panien)" 727 "Dhoot Transmission Pvt Ltd." 726 "MIDORI PRECISIONS" 725 "Hitachi Construction Machinery Co., Ltd." 724 "Electronic Applications, Inc." 723 "Jabil Inc." 722 "Contelec AG" 721 "Hypro" 720 "WITZ Corporation" 719 "Cojali S. L." 718 "Micronet Inc" 717 "Yacht Devices Ltd" 716 "Eaton Control & Power Conversion Division (CPCD)" 715 "Autonnic Research Ltd" 714 "Kobashi Kogyo Co., Ltd." 713 "US Hybrid Corporation" 712 "LOR Manufacturing Company Inc." 711 "DAS Co., LTD" 710 "Greentronics Ltd." 709 "Marquardt GmbH" 708 "Lars Thrane A/S" 707 "Rochester Gauges Inc" 706 "Shanghai Diesel Engine Corporation Limited" 705 "SVAB Hydraulik AB" 704 "JL Audio, Inc." 703 "Hydro Tab Marine Engineering" 702 "Weichai Power Co., Ltd." 701 "BigRoad Inc." 700 "K-Tec Earthmovers Inc." 699 "Harman International Industries" 698 "Scorpion Technologies Ltd." 697 "Ålö AB" 696 "DRS Network & Imaging Systems, LLC (DRS Technologies)" 695 "Weldon Technologies" 694 "GasTOPS Ltd." 693 "Agility Fuel Solutions (formerly Agility Fuel Systems)" 692 "Tanhay Corporation" 691 "Digitroll Agricultural Electronics" 690 "LINAK A/S" 689 "Aarcomm Systems Inc" 688 "Rockford Corp" 687 "Flight Systems, Inc." 686 "Taigene Electric Machinery Corp." 685 "ANEDO (formerly ANEDO Ltd.)" 684 "KEB" 683 "Fosen Elektro" 682 "Eckelmann AG" 681 "BEDIA Motorentechnik GmbH & Co. KG" 680 "AMVAC Chemical Corporation" 679 "Cimco Marine AB" 678 "KeepTruckin, Inc." 677 "DSA Daten- und Systemtechnik GmbH" 676 "Danfoss IXA A/S" 675 "Kawasaki Motors Corp., USA" 674 "Yara International ASA" 673 "Caruelle Nicolas" 672 "OPTIMA Concept" 671 "Innovative Controls Inc." 670 "STEMCO LP" 669 "Quantum Fuel Systems Technologies Worldwide, Inc" 668 "MacDon Industries Ltd." 667 "Bartec" 666 "Schaeffler Technologies AG & Co., KG" 665 "Gebr. Bode GmbH & Co. KG" 664 "Level Developments Ltd" 663 "Delta Systems, Inc" 662 "Kissling Elektrotechnik GmbH" 661 "SPAL Automotive S.r.l." 660 "Auto-Gaz Centrum" 659 "Data Panel Corp." 658 "Shenzhen Jiuzhou Himunication Technology Co., Ltd" 657 "Terzo Power Systems" 656 "PRO SOLUS do Brasil" 655 "Genge & Thoma AG" 654 "Kohler Power Systems, Detroit Engine Development Center (DEDC)" 653 "AEV, spol. s r. o." 652 "MicroControl GmbH & Co. KG" 651 "Takakita Co, Ltd." 650 "Seiko Epson Corp." 649 "Control-Q B.V." 648 "OJSC Ekran" 647 "Siloking" 646 "Veenhuis Machines B.V." 645 "esd electronic system design gmbh" 590 "ARGO-HYTOS GMBH" 589 "MICO, Inc." 588 "Vignal Systems" 587 "JCA Electronics" 586 "Suzuki Motor Corp" 585 "Industrial Electronic Controls" 584 "CarMedialab GmbH" 583 "Yachtcontrol" 582 "Innovative Software Engineering" 581 "Väderstad - Verken AB" 580 "San Jose Technology, Inc." 579 "KVH Industries, Inc." 578 "advanSea" 577 "Denchi Power Ltd  (formerly ABSL Power Solutions Limited)" 576 "Vectia" 575 "Lytx" 574 "Vishay Precision Group" 573 "Orolia Ltd" 572 "Fasse Valves" 571 "Marinecraft Co., Ltd." 570 "frenzel + berg electronic GmbH & Co. KG" 569 "LORD MicroStrain Sensing Systems" 568 "Makersan Ltd. Co." 567 "Lithiumstart LLC" 566 "Geode Technology, Inc." 565 "Micro-Trak Systems, Inc." 564 "Auto Power Electronic" 563 "LOHR Sistemas Eletronicos LTDA" 562 "Bombardier Transportation GmbH" 561 "b-plus GmbH" 560 "Iowa State University, Agricultural and Biosystems Engineering" 559 "Four Peaks Navigation" 558 "Davis Instruments Corp." 557 "Rockson Automation GmbH" 556 "Doosan Infracore Norway" 555 "Sasaki Corporation" 554 "iris-GmbH infrared & intelligent sensors" 553 "KIB Electronics" 552 "Matsuyama Plow Mfg Co, Ltd" 551 "Wexler CSD Ltd." 550 "SUN-A Corporation" 549 "ROAD Deutschland GmbH" 548 "TM4 Inc." 547 "Thomson Linear LLC" 546 "Maruyama Mfg Co, Inc." 545 "GS Hydraulics" 544 "Au Group Electronics" 543 "BAUER Maschinen GmbH" 542 "Dinamica Generale s.p.a." 541 "Total Fire Systems, Inc." 540 "Dinex A/S" 539 "Mobileview" 538 "Crop Ventures, Inc." 537 "Schrader Electronics Ltd." 536 "SSI Technologies" 535 "MOTORPAL, a.s." 534 "Webasto Thermo & Comfort SE" 533 "Doran Manufacturing, LLC" 532 "Onwa Marine Electronics Co Ltd." 531 "Genge & Thoma AG" 530 "NMEA" 529 "National Instruments Korea" 528 "Hoganas AB, Electric Drive Systems" 527 "GKN Walterscheid GmbH" 526 "LOFA Industries, Inc" 525 "Rust Sales INC" 524 "Vomax Instrumentation Pty. Ltd." 523 "Reggio Emilia Innovazione" 522 "Nebraska Tractor Test Laboratory" 521 "Clever Devices Ltd." 520 "Trapeze" 519 "Peeters Landbouwmachines b.v." 518 "Transas USA Inc." 517 "Noland Engineering" 516 "AVAT Automation GmbH" 515 "GINAF Trucks Nederland B.V." 514 "DISTek Integration, Inc." 513 "Precision Technology (Formerly FarmscanAg)" 512 "Inpower LLC" 511 "Sulky" 510 "Marinesoft Co. Ltd" 509 "MOTORTECH GmbH" 508 "Transtech Innovations" 507 "ISOBUS Test Center" 506 "IHI STAR Machinery Corporation" 505 "Yetter Farm Equipment" 504 "Vesper Marine" 503 "Naviop S.R.L." 502 "Attwood Corporation" 501 "Agrotronix S.A." 500 "Oxbo International Corporation" 499 "LCJ Capteurs" 498 "Innovative Design Solutions, Inc." 497 "SENTRON Sistemas Embarcados" 496 "W. Gessmann GmbH" 495 "HOLMER Maschinenbau GmbH" 494 "Synerject" 493 "Watcheye" 492 "Inergy Automotive Systems" 491 "Penny and Giles Ltd" 490 "QuikQ" 489 "Appareo Systems, LLC" 488 "The Charles Machine Works, Inc." 487 "DSE Test Solutions A/S" 486 "Westport Innovations Inc." 485 "MATT automotive" 484 "Headsight Inc." 483 "Valeo" 482 "Tricon Electronics" 481 "Chetco Digital Instruments" 480 "EnerDel, Inc." 479 "Vapor Bus International" 478 "OceanSat B.V." 477 "OilQuick AB" 476 "Hummingbird Marine Electronics" 475 "GME" 474 "Persen Technologies Inc." 473 "Boss Industries, Inc." 472 "Tenneco Inc." 471 "Sea Cross Marine AB" 470 "SI-TEX Marine Electronics" 469 "RA Consulting GmbH" 468 "Tyco Fire Protection Products" 467 "Lely Industries N.V." 466 "Veethree Electronics and Marine LLC" 465 "Ashcroft Inc" 464 "Leach International Corporation" 463 "PROBOTIQ" 462 "IHI Shibaura Machinery Corporation" 461 "HAWE Hydraulik SE" 460 "San Giorgio S.E.I.N." 459 "Alltek Marine Electronics Corp" 458 "Control Solutions, Inc." 457 "RUSELPROM-ElectricDrive Ltd" 456 "General Kinetics" 455 "ADZ NAGANO GmbH" 454 "NGK Spark Plug Co. Ltd" 453 "Cooper Bussmann" 452 "WIKA Alexander Wiegand SE & Co. KG" 451 "Parker Hannifin Corp" 450 "Dycor Technologies Ltd." 449 "Polaris Industries Inc" 448 "Stanadyne Corporation, Electronics Systems" 447 "Great Plains Mfg." 446 "CertTech, L.L.C." 445 "KAT MECHATRONIC, Electronic Product Division" 444 "ITT Power Solutions" 443 "SignalQuest, Inc." 442 "Horsch Maschinen GmbH" 441 "PTG Reifendruckregelsysteme GmbH" 440 "Cummins Power Generation" 439 "Hyundai Heavy Industries" 438 "Comar Systems Ltd" 437 "Digital Yacht Limited" 436 "Kinze Manufacturing" 435 "Zunhammer GmbH" 434 "Stored Energy Systems" 433 "Rowe Electronics" 432 "S&A Systems, Inc." 431 "Tohatsu Corporation" 430 "Auteq Telematica S.A." 429 "Rota Engineering Ltd." 425 "Methode Electronics Inc, MDI" 424 "Odyne LLC" 423 "BSM Wireless, Inc." 422 "True Heading AB" 421 "Vertex Standard Co, Ltd" 420 "Vermeer Corporation, ACS Group" 419 "Fusion Electronics Ltd" 418 "Intellistick Inc" 417 "KZValve" 416 "Kubota Corporation" 415 "Valid Manufacturing Ltd." 414 "Cattron Group International" 413 "Datapross Nijbroek bv" 412 "WebTech Wireless Inc." 411 "Hy-Drive Technologies Ltd." 410 "COBO S.p.A. Divisione 3B6" 409 "Transfluid S.r.L." 408 "Corvus Energy Ltd." 407 "Comtech Mobile Datacom" 406 "Vecima Networks Inc." 405 "Wema System AS" 404 "Com Nav Marine Ltd" 403 "Trackwell ADS, Inc." 402 "Simma Software, Inc." 401 "Torqeedo GmbH" 400 "Livorsi Marine" 399 "ISEKI & Co., Ltd." 398 "Hilite International" 397 "Sanyo-kiki Co Ltd." 396 "Beyond Measure" 395 "GENTEC S.R.L." 394 "Capi 2 Nederland B.V." 393 "Harvest Tec, Inc" 392 "Tianyuan Technology Co Ltd." 391 "Electronic Design for Industry, Inc" 390 "Partech Inc." 389 "Benchmark Electronics, Minnesota Division" 388 "Innomatix, LLC" 387 "Orscheln Products, LLC" 386 "JLG Automation BVBA" 385 "Johnson Outdoor Marine Electronics" 384 "Camano Light" 383 "MCL Industries" 332 "HWH Corporation" 331 "Horton, Inc." 330 "Kidde Aerospace and Defense" 329 "Deif A/S" 328 "Qwerty Electronik AB" 327 "Sonceboz SA" 326 "Akron Brass Company" 325 "ASM Automation Sensorik Messtechnik GmbH" 324 "Snap-on Diagnostics" 323 "Mobileye Vision Technologies Ltd." 322 "MICHENKA s.r.o." 321 "Ultra Electronics, Electrics" 320 "Miedema Landbouwwerktuigenfabriek B.V." 319 "Cadec Global" 318 "SAT Plan" 317 "Navtronics Bvba" 316 "ITT Flow Control" 315 "Icom Incorporated" 314 "CSM GmbH" 313 "Ilmor Engineering, Inc." 312 "Lectronix, Inc." 311 "Patrick Power Products" 310 "TECNORD srl" 309 "Krauss-Maffei Wegmann GmbH & Co. KG" 308 "Cyntrx" 307 "MAS Technologies" 306 "Sleipner Motor AB" 305 "NovAtel Inc" 304 "EmpirBus AB" 303 "CTS Corporation" 302 "Nissin Kogyo Co., LTD" 301 "Parker Hannifin (UK) Ltd FDE group" 300 "Systron Donner Automotive" 299 "Rauch" 298 "Holley Performance" 297 "Zonar Systems Inc" 296 "micro dynamics GmbH" 295 "BEP Marine" 294 "Grayhill Inc." 293 "Spyder Controls Corp." 292 "IKUSI - Angel Iglesias S.A." 291 "Groeneveld Transport Efficiency BV" 290 "Kuebler GmbH" 289 "Watlow" 288 "Mitsubishi FUSO Truck & Bus Corp." 287 "NTech Industries, Inc" 286 "Coelmo srl" 285 "Sea Recovery Corp" 284 "Mobile Tech Chile" 283 "CWF Hamilton & Co Ltd" 282 "Medallion Instrumentation Systems" 281 "Precision Governors LLC" 280 "Leica Geosystems Pty Ltd" 279 "Geometris LP" 278 "Takata Electronics" 277 "LHP Telematics" 276 "Aqua-Hot Heating Systems" 275 "Navico Egersund AS" 274 "LTW Technology Co., LTD" 273 "Active Research Limited" 272 "Gross Mechanical Laboratories, Inc" 271 "Cole Hersee" 270 "Tennant" 269 "Saft America Inc.,  Space & Defense Division" 268 "Accurate Technologies" 267 "Red Lion Controls, Inc" 266 "International Thermal Research Ltd" 265 "MTS Sensor Technologie GmbH" 264 "Autolync" 263 "IMMI" 262 "HydraForce, Inc" 261 "Red Dot Corporation" 260 "Reichhardt GmbH Steuerungstechnik" 259 "Jetter AG" 258 "ARAG" 257 "Honda Motor Co., Ltd" 256 "Tyco Electronics AMP" 255 "MEAS France" 254 "GE Sensing" 253 "Mobile Control Systems" 252 "Sensor-Technik Wiedemann GmbH" 251 "German Agricultural Society, Test Center (DLG)" 250 "Kuhn Group" 249 "Schaltbau GmbH" 248 "Cooper Standard Automotive Active Systems Group" 247 "ePULSE" 246 "Class 1, Inc" 245 "Capstan Ag Systems, Inc." 244 "Techno-Matic" 243 "eRide, Inc." 242 "Kokusandenki Co. Ltd" 241 "Schneider Automation SAS" 240 "Vanair Mfg" 239 "May & Scofield Ltd" 238 "ZF Friedrichshafen AG" 237 "Agtron Enterprises Inc" 236 "NORAC Systems International Inc" 235 "SailorMade Marine Telemetry - Tetra Technology Ltd." 234 "Mondial electronic GmbH" 233 "Yacht Monitoring Solutions Inc." 232 "TSD Integrated Controls" 231 "Topcon Positioning Systems, Inc." 230 "Saucon Technologies" 229 "Garmin International Inc." 228 "Unused (formerly ZF Marine Electronics)" 227 "Lykketronic A/S" 226 "Monaco Coach Corporation" 225 "SKF" 224 "EMMI Network, S.L." 223 "Vaueo Retarder Co., Ltd." 222 "Generac Power Systems, Inc." 221 "SiE" 220 "Beede Electrical Instrument Company, Inc" 219 "Cat OEM Solutions" 218 "Gits Manufacturing Company" 217 "RM Michaelides Software & Elektronik GmbH" 216 "Paneltronics Inc." 215 "Aetna Engineering/Fireboy-Xintex" 214 "MC elettronica Srl" 213 "CNH Belgium N.V." 212 "Sure Power Industries, Inc" 211 "DNA Group" 210 "Iteris, Inc." 209 "Bell Equip. Co. SA (PTY) LTD" 208 "Drew Technologies, Inc" 207 "Otto Engineering" 206 "port GmbH" 205 "SmarTire Systems Inc" 204 "The Morey Corporation" 203 "MILtronik GmbH" 202 "Curtis Instruments, Inc" 201 "Disenos y Tecnologia S.A." 200 "MGM Brakes" 199 "ACTIA Group (formerly Actia Corp)" 198 "Mystic Valley Communications" 197 "Mechron Power Systems" 196 "LEMKEN GmbH & Co KG" 195 "General Engine Products" 194 "TriMark Corporation" 193 "Jeppesen Marine" 192 "Floscan" 191 "XRS Corporation (formerly XATA Corporation)" 190 "Hella KGaA Hueck & Co" 189 "QUALCOMM" 188 "EMP Corp" 187 "Air-Weigh" 186 "Altronic, Inc" 185 "Beede Electrical Instrument Company" 184 "EIA Electronics" 183 "KDS Controls, Inc" 182 "Vehicle Systems Engineering B.V." 181 "Coretronics, Inc." 180 "Smart Power Systems" 179 "TeeJet Technologies Springfield (formerly Midwest Technologies Illinois, LLC)" 178 "Continental Automotive GmbH (formerly Siemens VDO Automotive AG)" 177 "Diagnostic Systems Associates" 176 "Moritz Aerospace" 175 "Veris Technologies, Inc." 174 "AB Volvo Penta" 173 "Ryeso, Inc." 172 "Yanmar Co., Ltd. (formerly Yanmar Marine USA)" 171 "Topcon Electronics GmbH & Co. KG (formerly Wachendorff Elektronik GmbH & Co. KG)" 170 "Computronics Corporation Ltd." 169 "Marlin Technologies Inc." 168 "Xantrex" 167 "JLG Industries Inc" 166 "John Deere Electronic Solutions (formerly Phoenix International)" 165 "CPAC Systems AB" 164 "MTU Friedrichshafen GmbH (formerly DaimlerChrysler Off-Highway)" 163 "BRP Inc." 162 "Axiomatic Technologies" 161 "Offshore Systems (UK) Ltd" 160 "Nido" 159 "NTech Industries Inc" 158 "Firestone Industrial Products Company" 157 "ISSPRO Inc." 156 "ITT Industries - Cannon" 155 "Vetronix Corporation" 154 "Westerbeke Corporation" 153 "Woodward, Industrial Controls Division" 152 "elobau GmbH & Co. KG" 151 "Raven Industries, Inc." 150 "Fleetguard" 149 "Holset" 148 "Blue Water Data, Inc." 147 "Nautibus electronic GmbH" 146 "Maxima Technologies" 145 "MurCal Controls" 144 "Mercury Marine" 143 "W. Gmeiner GmbH & Co." 142 "TRW Automotive (Commercial Steering Systems)" 141 "Thales Navigation Ltd." 140 "Lowrance Electronics, Inc." 139 "Caterpillar Trimble Control Technologies (CTCT), LLC" 138 "Georg Fritzmeier GmbH & Co. KG" 137 "Maretron" 136 "Komatsu Ltd" 135 "Airmar Technology Corporation" 134 "Iris Technology Ltd" 133 "Bucher Schoerling GmbH" 132 "Mulag-Fahrzeugwerk" 131 "ITT Industries" 130 "Nido - Universal Machines B.V." 129 "OMNEX Control Systems Inc." 128 "Gerhard Duecker GmbH & Co. KG" 127 "Holland USA" 126 "Driver Tech" 125 "Nevada Automotive Test Center" 124 "Hydac Electronic" 123 "Basler Electric" 122 "FG Wilson (Engineering) Limited" 121 "HED (Hydro Electronic Devices, Inc.)" 120 "RDS Technology Ltd" 119 "IntegriNautics  " 118 "Intron GmbH" 117 "HUSCO International" 116 "BEELINE Technologies" 115 "NACCO Materials Handling Group, Inc." 114 "EControls, Inc." 113 "Stress-Tek, Inc." 112 "MECALAC" 111 "Bernard Krone Holding SE & Co. KG (formerly Maschinenfabrik Bernard Krone GmbH)" 110 "EPIQ Sensor-Nite" 109 "TeeJet Technologies Denmark (formerly LH Technologies ApS)" 108 "WTK-Elecktronik GmbH" 107 "Grimme Landmaschinen GmbH & Co. KG" 106 "BAE Systems Controls, Inc." 105 "Kiepe Elektrik GmbH & Co. KG" 104 "CLAAS KGaA mbH (formerly CLAAS Selbstfahrende Erntemaschinen GmbH)" 103 "CLAAS E-Systems GmbH (formerly CLAAS E-Systems KGaA mbH & Co. KG)" 102 "AGCO (formerly AGCO GmbH & Co.)" 101 "Sensoria" 100 "VDO Technik AG" 99 "International Transmissions Ltd (ITL)" 98 "Mueller-Elektronik GmbH & Co" 97 "Ag Leader Technology, Inc." 96 "Mech@tronic IT GmbH" 95 "Pacific Insight Electronics Corp." 94 "CNH Industrial N.V. (formerly CNH Global N.V.)" 93 "Perkins Engines Company Ltd." 92 "Ag-Chem Equipment Co., Inc." 91 "BSG Bodensee Steuergeraete GmbH" 90 "Knorr-Bremse SfN GmbH" 89 "Kverneland Group, Electronics Division" 88 "Hemisphere GPS Inc (formerly Satloc Precision GPS)" 87 "J.C. Bamford Excavators Ltd (JCB)" 86 "C. E. Niehoff & Company" 85 "Kohler Co" 84 "New Holland UK Limited" 83 "Bendix VORAD Technologies (formerly Eaton VORAD Technologies)" 82 "Bobcat/Ingersoll-Rand (formerly Melroe/Ingersoll-Rand)" 81 "Fire Research Corp." 80 "Twin Disc, Inc." 79 "Daimler Benz AG - Engine Division (PBM)" 78 "Frank W. Murphy Manufacturing, Inc" 77 "Deere Power Systems Group" 76 "unused (formerly Deere & Co, Construction Division)" 75 "Deere & Co, Agricultural Division" 74 "Eaton Axle-Brake Division" 73 "LeTourneau, Inc." 72 "Sisu Corporation" 71 "Vansco Electronics Ltd." 70 "Flex-coil Limited" 69 "Trimble Navigation" 68 "Scania" 67 "John Deere Coffeyville Works (formerly Funk Manufacturing Company)" 66 "John Deere Construction Equipment Division" 65 "MAN Nutzfahrzeuge AG" 64 "Unused (formerly SpectraPrecision Laserplane, then SpectraPhysics)" 63 "ZF Industries Inc." 62 "Wabco" 61 "Volvo Truck Corp." 60 "Volvo Trucks North America Inc." 59 "VES Inc." 58 "SPX Corporation, OTC Div" 57 "Danfoss  (formerly Sauer Sundstrand Co, then Sauer-Danfoss Co)" 56 "SAIC" 55 "Ryder System Inc." 54 "Meritor Wabco" 53 "Continental Automotive Systems US, Inc. (formerly Rockwell Land Transportation)" 52 "Meritor Automotive, Inc. (formerly Rockwell Automotive)" 51 "Robert Bosch GmbH" 50 "Robert Bosch Corp" 49 "RE America Inc." 48 "Pollak Alphabet" 47 "Phillips Semiconductor" 46 "Noregon Systems, Inc  (formerly Parasoft Computing Solutions)" 45 "PACCAR" 44 "Nippondenso Co. Ltd." 43 "International Truck and Engine Corporation - Vehicle Electronics (formerly Navistar Intl Trans Corp.)" 42 "International Truck and Engine Corporation - Engine Electronics  (formerly Navistar Intl Trans Co., Engine Electronics)" 41 "Motorola Inc." 40 "Motorola AIEG Inc." 39 "Microfirm Inc." 38 "Micro Processor Systems Inc." 37 "Mack Trucks Inc." 36 "Lucas Ind." 35 "Kenworth Truck Co." 34 "Kelsey Hayes Co." 33 "John Deere" 32 "Jacobs Vehicle Systems" 31 "J Pollak Corp" 30 "Isuzu Motors Ltd" 29 "Hino Motors Ltd." 28 "Grote Ind. Inc." 27 "GMC" 26 "General Motors Corp, Service Technology Grp" 25 "Daimler Trucks North America LLC (formerly Freightliner LLC)" 24 "Ford Motor Co., Vehicle Controls" 23 "Ford Motor Co., Heavy Truck" 22 "Ford Motor Co., Electronic Concepts & Systems" 21 "Echlin Inc., Midland Brake Inc." 20 "Eaton Ltd" 19 "Eaton Corp. Trucking Info Services" 18 "Eaton Corp, Transmission Div." 17 "Eaton Corp, Corp Res & Dev" 16 "Eaton Corp" 15 "DICKEY-john Corporation" 14 "Detroit Diesel Corporation" 13 "Delco Electronics" 12 "Deere & Company, Precision Farming" 11 "Dearborn Group Inc." 10 "Cummins Inc (formerly Cummins Engine Co)" 9 "Chrysler Corp." 8 "Caterpillar Inc." 7 "Case Corp." 6 "Berifors Electronics AB" 5 "AMP Inc." 4 "Ametek-Dixson" 3 "Ametek, US Gauge Division" 2 "Allison Transmission, Inc." 1 "Bendix Commercial Vehicle Systems LLC (formerly Allied Signal Inc.)" 0 "Reserved" ;
VAL_ 2565799425 VehicleSystem 0 "Non-specific System" 127 "Not Available" ;
VAL_ 2565799425 VehicleSystem5 127 "Not Available" 0 "Ind. Process Control Stationary" ;
VAL_ 2565799425 VehicleSystem4 125 "Entertainment" 120 "Display" 85 "External Environment" 75 "Sensor Communication Interface" 35 "Electrical Generation" 100 "Deck, Cargo and Fishing Equipment" 90 "Internal Environment" 80 "Instrumentation/General Systems (deprecate)" 70 "Communications" 60 "Navigation" 50 "Propulsion" 40 "Steering and Control Surfaces" 30 "Electrical Distribution" 25 "Inter/Intranetwork Device" 20 "Safety Systems" 10 "System Tools" 127 "Not Available" 0 "Non-specific System" ;
VAL_ 2565799425 VehicleSystem3 8 "Grader" 7 "Four Wheel Drive Loader" 6 "Forklift" 5 "Excavator" 4 "Crawler" 3 "Backhoe" 2 "Articulated Dump Truck" 1 "Skid Steer Loader" 127 "Not Available" 0 "Non-specific System" ;
VAL_ 2565799425 VehicleSystem2 25 "Slurry Applicators" 24 "Utility Vehicles" 23 "Mulchers" 22 "Timber Processing Machines" 21 "Timber loaders" 20 "Forwarders" 19 "Timber Harvesters" 17 "Sensor Systems" 16 "Skidder" 15 "Earth Work" 14 "Special Crops" 13 "Powered Auxiliary Device" 12 "Farm Yard Operations" 11 "Transport/Trailer" 10 "Irrigation" 9 "Forage" 8 "Root Harvesters" 7 "Harvesters" 6 "Sprayers" 5 "Fertilizers" 4 "Planters/Seeders" 3 "Secondary Tillage" 2 "Tillage" 1 "Tractor" 127 "Not Available" 0 "Non-specific System" ;
VAL_ 2565799425 VehicleSystem1 2 "Trailer" 1 "Tractor" 127 "Not Available" 0 "Non-specific System" ;
VAL_ 2565799426 IndustryGroup 6 "Reserved for SAE" 7 "Reserved for SAE" 5 "IndustrialProcessCtrlStationary" 4 "Marine" 3 "Construction" 2 "Agricultural and Forestry" 1 "On-Highway" 0 "Global" ;
VAL_ 2565799426 Function 127 "Reserved" 126 "Reserved" 125 "Reserved" 124 "Reserved" 123 "Reserved" 122 "Reserved" 121 "Reserved" 120 "Reserved" 119 "Reserved" 118 "Reserved" 117 "Reserved" 116 "Reserved" 115 "Reserved" 114 "Reserved" 113 "Reserved" 112 "Reserved" 111 "Reserved" 110 "Reserved" 109 "Reserved" 108 "Reserved" 107 "Reserved" 106 "Reserved" 105 "Reserved" 104 "Reserved" 103 "Reserved" 102 "Reserved" 101 "Reserved" 42 "Water Pump Control" 41 "Lighting - Operator Controls" 40 "Seat Control" 39 "Ignition Control Module" 38 "Tire Pressure Control" 37 "Cab Controller" 36 "Pneumatic - System Controller" 35 "Suspension - System Controller" 34 "Hydraulic Pump Controller" 33 "System Monitor" 32 "Headway Controller" 31 "Propulsion Battery Charger" 30 "Management Computer" 29 "Virtual Terminal (in cab)" 28 "Off Vehicle Gateway" 27 "Power TakeOff (Secondary or Front)" 26 "Body Controller" 25 "Network Interconnect ECU" 24 "Vehicle Security" 23 "Vehicle Navigation" 22 "Aerodynamic Control" 21 "Cab Climate Control" 20 "Trip Recorder" 19 "Instrument Cluster" 18 "Suspension - Drive Axle" 17 "Suspension - Steer Axle" 16 "Steering Controller" 15 "Fuel System" 14 "Cruise Control" 13 "Retarder - Driveline" 12 "Retarder - Engine" 11 "Brakes - Drive Axle" 10 "Brakes - Steer Axle" 9 "Brakes - System Controller" 8 "Axle - Drive" 7 "Axle - Steering" 6 "Power TakeOff - (Main or Rear)" 5 "Shift Control/Console" 4 "Battery Pack Monitor" 3 "Transmission" 2 "Electric Propulsion Control" 1 "Auxiliary Power Unit (APU)" 0 "Engine" 100 "Reserved" 99 "Reserved" 98 "Reserved" 97 "Reserved" 96 "Reserved" 95 "Reserved" 94 "Reserved" 93 "Reserved" 92 "Reserved" 91 "Reserved" 90 "Reserved" 89 "Reserved" 88 "Reserved" 87 "Reserved" 86 "Reserved" 85 "Reserved" 84 "Reserved" 83 "Reserved" 82 "Reserved" 81 "Reserved" 80 "Reserved" 79 "Reserved" 78 "Fire Suppression System" 77 "Fuel Properties Sensor" 76 "Temperature Sensor" 75 "Supplemental Fan" 74 "Lubrication System" 73 "Rollover Detection Control" 72 "Coolant Valve Controller" 71 "Transfer Case Control" 70 "Auxiliary Regeneration Device" 69 "Engine Emission Aftertreatement System" 68 "Aftertreatment system gas measurement" 67 "Electrical System Controller" 66 "I/O Controller" 65 "Gas Flow Measurement" 64 "Endurance Braking" 63 "Engine Valve Controller" 62 "On-Board Diagnostic Unit" 61 "File Server/Printer" 60 "Cab Display" 59 "Starter" 58 "Fan Drive Control" 57 "Steering Column Unit" 56 "Communications Unit, Radio" 55 "Communications Unit, Satellite" 54 "Communications Unit, Cellular" 53 "Alternator/Charging System" 52 "Chassis Controller" 51 "Forward-Looking Collision Warning System" 50 "Auxiliary Heater" 49 "Clutch/Converter Control" 48 "Ramp Control" 47 "Information System Controller" 46 "Oil Sensor Unit" 45 "Vehicle Dynamic Stability Control" 44 "Exhaust Emission Control" 43 "Transmission Display" ;
VAL_ 2565799426 ManufacturerCode 900 "OSB AG" 899 "Lippert Components, Inc" 898 "Josef Kotte Landtechnik GmbH & Co. KG" 897 "Dot Technology Corp." 896 "NextFour Solutions Ltd" 895 "Peloton Technology" 894 "Rhodan Marine Systems of Florida LLC" 893 "KlinkTechnics Ltd." 892 "Mectronx Corp" 891 "CarrierWeb" 890 "L3 Technologies, Inc." 889 "SANY America Inc" 888 "Carma Systems Inc" 887 "Hyperdrive Innovation Limited" 886 "Hitachi Zosen Corporation" 885 "SICK Stegmann GmbH" 884 "Sure Grip Controls Inc." 883 "Swift Navigation, Inc." 882 "BHTronik GmbH & Co. KG" 881 "Sovema" 880 "Revision Military" 879 "PG Trionic, Inc." 878 "FOTON" 877 "SICK ATech GmbH" 876 "SUCO Robert Scheuffele GmbH & Co. KG" 875 "Salvarani S.r.l." 874 "MTA S.p.A." 873 "Garnet Instruments Ltd." 872 "Kählig Antriebstechnik GmbH" 871 "Superior Tech Inc" 870 "Textron Fleet Management" 869 "Intercomp" 868 "Data Panel Corp" 867 "Skeleton Technologies" 866 "Netradyne, Inc." 865 "MyEasyFarm" 864 "Streamline Transportation Technologies Inc." 863 "SMAG" 862 "Prospec Electronics" 861 "Adel System S.r.l." 860 "Michelin" 859 "Valor" 858 "Littelfuse" 857 "Zoomlion Heavy Industry NA, Inc" 856 "FarmFacts GmbH" 855 "Toshiba Infrastructure Systems & Solutions Corporation" 854 "GEMAC Chemnitz GmbH" 853 "Teledyne RESON B.V." 852 "Velvac Inc" 851 "Novotechnik Messwertaufnehmer OHG" 850 "Geoprospectors GmbH" 849 "MTS Maschinentechnik Schrode AG" 848 "ningupex" 1863 "Thomas G. Faria Co." 1862 "Sanshin" 1861 "Vector North America (formerly Vector Cantech)" 1860 "MMP" 1859 "Kvasar AB" 1858 "Litton" 1857 "Simrad" 1856 "Trimble" 1855 "Furuno USA" 1854 "Northstar Technologies" 1853 "Japan Radio Co" 1852 "Navionics" 1851 "RayMarine" 1850 "Seastar Solutions (formerly Teleflex)" 1569 "621 Technologies Inc." 1077 "Ymer Technology" 1076 "DOGA S.A." 1075 "Uniden America Corporation" 1074 "Kindhelm / Navigs Oy" 1073 "Manitou Equipment America LLC" 1072 "La Marche Manufacturing Company" 1071 "MACH SYSTEMS s.r.o." 1070 "Quick-teck Electronics Ltd" 1069 "Lithionics Battery LLC" 1068 "Zapi S.p.A." 1067 "Tecomec S.r.l." 1066 "Spot Zero Water" 1065 "CALYPSO Instruments" 1064 "Omnitech Robotics Inc." 1063 "SolSteer" 1062 "Marol Co Ltd" 1061 "Volvo Construction Equipment" 1060 "Scale-Tec" 1059 "Boatrax" 1058 "Bondioli & Pavesi SpA" 1057 "EquipmentShare" 1056 "Lithium Pros" 1055 "EXA Computing GmbH" 1054 "Schmotzer Hacktechnik GmbH & Co. KG" 1053 "Vetus Maxwell, Inc." 1052 "Pfreundt" 1051 "ProNav AS" 1050 "Spacenus GmbH" 1049 "S&S Cycle" 1048 "Agrivation UG" 1047 "Sonic Corporation" 1046 "Praxidyn" 1045 "CMR Group" 1044 "Xee" 1043 "Hyva" 1042 "engcon group" 1041 "EZ Lynk" 1040 "BPE Electronics Srl" 1039 "Liugong Dressta Machinery" 1038 "EMIT Technologies, Inc." 1037 "Dragonfly Energy Corp." 1036 "Bender GmbH & Co. KG" 1035 "Agres" 1034 "Siren Marine" 1033 "ECCO Safety Group" 1032 "SIMOL S.p.A." 1031 "Flintec UK Ltd." 1030 "Tume-Agri Oy" 1029 "The Marine Guardian LLC" 1028 "Autel Intelligent Technology Corp., Ltd" 1027 "Goldacres PTY LTD" 1026 "ZTR Control Systems, LLC" 1025 "eze System, Inc." 1024 "Inventus Power" 1023 "PEAK-System Technik GmbH" 1022 "ITC Inc" 1021 "Entratech Systems LLC" 1020 "Onyx Marine Automation s.r.l." 1019 "Codek Foundries" 1018 "Flex TTS" 1017 "Caldaro AB" 1016 "Röhren- und Pumpenwerk BAUER GmbH" 1015 "SECURITAG SAS" 1014 "Briri Maschinenbau GmbH" 1013 "Allochis E-Tec" 1012 "Rhodan Marine Systems of Florida LLC" 1011 "Soundmax Electronics Ltd" 1010 "Agricultural Industry Electronics Foundation e.V." 1009 "TouchTronics, Inc." 1008 "Lintest Systems LLC" 1007 "Maschinenfabrik Meyer-Lohne GmbH" 1006 "Proterra" 1005 "TSE Brakes, Inc." 1004 "Ultraflex SpA" 1003 "technotrans SE" 1002 "Kussmaul Electronics Co." 1001 "Cleral Inc." 1000 "Landmaschinen Wienhoff GmbH" 999 "TerraTroniq B.V." 998 "Transcell Technology Inc" 997 "Xenta Systems Srl" 996 "Eniquest Pty Ltd" 995 "Circuitlink Pty Ltd." 994 "Morris Industries Ltd." 993 "Alelion Energy Systems AB" 992 "MarineIOT LLC" 991 "Deutronic Elektronik GmbH" 990 "SAMSUNG SDI Co., Ltd." 989 "Flux-Geräte GmbH" 988 "Voith Turbo" 987 "Baltic Car Equipment" 986 "AAMP Global" 985 "NLR, LLC" 984 "E-T-A Elektrotechnische Apparate GmbH" 983 "Dezwaef NV" 982 "Briggs & Stratton Corporation" 981 "Kobelt Manufacturing Co. Ltd" 980 "Gussi Italia S.R.L." 979 "McHale" 978 "Canfield Connector" 977 "Emerson Electric Co." 976 "Derive Systems, Inc." 975 "Siemens AG" 974 "Pico Technology Limited" 973 "Zasso GmbH" 972 "Axion AG" 971 "B+B Smartworx" 970 "Jaboni Power Products, LLC" 969 "Blue Sea Systems" 968 "Cox Powertrain Limited" 967 "Moteck Electric Corp." 966 "VisibleFarm" 965 "Ro-Sys Software" 964 "AgroVIR Kft" 963 "Thomason Jones Company, LLC" 962 "Timbolier Industries, Inc." 961 "POK SAS" 960 "Vemcon GmbH" 959 "Cascade Corporation" 958 "NHK MEC Corporation" 957 "Sierra Wireless Inc" 956 "Piher Sensors & Controls S.A." 955 "Hottinger Baldwin (Suzhou) Electronic Measurement Technology Co., Ltd." 954 "Setec Pty Ltd" 953 "Curtiss-Wright" 952 "Tan Delta Systems Ltd" 951 "Exor International S.p.A." 950 "RE:Lab s.r.l." 949 "Škoda Electric a.s." 948 "Donix" 947 "Gerd Bär GmbH" 946 "Hydac Tecnologia Ltda" 945 "Equalizer AG" 944 "ZONTISA Marine SL" 943 "FISCHER AG Präzisionspindeln" 942 "Vogelsang GmbH & Co. KG" 941 "Navya" 940 "Dometal Oy" 939 "Warn Industries, Inc." 938 "LEVEL Systems" 937 "Precision Circuits Inc" 936 "Hi-tech Millennium" 935 "Meels GmbH & Co. KG" 934 "Farmobile, Inc." 933 "Delta Mobile Systems, Inc." 932 "Discover Battery" 931 "Enertec Marine Ltd" 930 "Ecotronix Corp." 929 "Jl Marine Systems, Inc." 928 "EAO Automotive GmbH & Co. KG" 927 "Saicon" 926 "Buhler Industries Inc." 925 "GW Lisk Company" 924 "PAS Peschak Autonome Systeme GmbH" 923 "ELTEK S.p.A." 922 "Terberg Benschop B.V." 921 "ROPA Fahrzeug- und Maschinenbau GmbH" 920 "MTD Consumer Group Inc." 919 "Furrion LLC" 918 "AMW Machine Control, Inc" 917 "Sentinel d.o.o." 916 "Turck Inc." 915 "Dosificacion y sistemas electronicos S.L. (DSE)" 914 "ZETOR TRACTORS a.s." 913 "Toyota Motor Corporation" 912 "Steyr Motors GmbH" 911 "Nautic-On" 910 "Hermann Paus Maschinenfabrik GmbH" 909 "Marines Co., Ltd." 908 "Chonbuk National University Department of Electronics" 907 "strautmann" 906 "MOBA AG" 905 "ASA Electronics" 904 "Equipment Safety Systems Pty. Ltd. (EQSS)" 903 "InMotion" 902 "Bucher Hydraulics" 901 "Zivan Srl" 847 "Oceanvolt" 846 "L3 Magnet-Motor" 845 "GMB Güstrower Maschinenbau GmbH" 844 "FELL AS" 843 "Hendrickson Truck Commercial Vehicle Systems" 842 "DigiDevice Srl" 841 "Agra-GPS" 840 "E.S.T.E. Srl" 839 "Indexator Rotator Systems AB" 838 "Teamsurv Ltd" 837 "Famic Technologies Inc." 836 "Signature4" 835 "PetTrack Ltd." 834 "Pioneer Microsystems, Inc." 833 "Electrum Automation AB" 832 "Heizomat Gerätebau-Energiesysteme GmbH" 831 "DOK-ING Ltd." 830 "Ultra Motion LLC" 829 "Drov Technologies, Inc." 828 "AgriBrink Inc." 827 "INmatix Technology Group Ltd" 826 "Lewmar Marine Inc" 825 "BPW Hungária" 824 "Undheim Systems AS" 823 "ACEINNA, Inc (formerly MEMSIC, Inc)" 822 "Bren-Tronics, Inc." 821 "Thorsen Teknik A/S" 820 "DIaLOGIKa Gesellschaft fuer angewandte Informatik mbH" 819 "Preco Electronics" 818 "HGNSS" 817 "TE Connectivity Sensor Solutions" 816 "UniStrong" 815 "FLIR Systems, Inc." 814 "Kronotech Srl (formerly Soltec Soluzioni Tecnologiche Srl)" 813 "Thales Suisse SA" 812 "Torch Technologies" 811 "Blue Water Desalination" 810 "Dutch Power Company" 809 "HMS Industrial Networks AB" 808 "RIMEX Supply Ltd." 807 "Schneider-Electric" 806 "Charge Automotive Ltd" 805 "Gundersen & Løken AS" 804 "ASA Electronics" 803 "Gill Sensors & Controls Limited" 802 "SPBI (Bj Technologie)" 801 "LOR Manufacturing Company Inc." 800 "Delta-Q Technologies" 799 "Stillwater Designs and Audio, Inc. - KICKER" 798 "Lumishore Ltd" 797 "Tides Marine" 796 "Canadian Automotive Industries Ltd" 795 "Broyda Enterprises Pty Ltd" 794 "Shihlin Electric & Engineering Corporation" 793 "James Fisher Prolec" 792 "Kostal Mexicana" 791 "AUTEC" 790 "VACALL" 789 "GRADALL" 788 "MoTeC Pty Ltd" 787 "Abertax Technologies Limited" 786 "Johnson Matthey Battery Systems" 785 "Fischer Panda GmbH" 784 "CM Automotive Systems, Inc." 783 "Loup Electronics Inc." 782 "AVR bv (formerly AVR bvba)" 781 "Poly-Planar LLC" 780 "AVID Technology Ltd" 779 "RLC Electronic Systems" 778 "Seakeeper Inc." 777 "Ocean Signal Ltd" 776 "HMI Systems LLC" 775 "ZIEHL-ABEGG Automotive GmbH" 774 "Taisho Corporation" 773 "Clarion Corporation of America" 772 "Blink Marine" 771 "Shaw Development, LLC" 770 "MONOSEM" 769 "Trombetta" 768 "Flores Automation, LLC" 767 "Alliance Wireless Technologies Inc." 766 "Epec Oy" 765 "GIGAVAC" 764 "Bednar FMT s.r.o." 763 "AT-Systems BVBA" 762 "ROJ s.r.l." 761 "MITA OLEODINAMICA S.p.A." 760 "Bernecker + Rainer Industrie Elektronik GmbH" 759 "Hydro-Gear" 758 "Banner Engineering Corp." 757 "IMPCO Technologies" 756 "Maschio Gaspardo S.P.A." 755 "Firefly Integrations" 754 "Parker Hannifin Corp., Automation Group" 753 "AIROD Technologies" 752 "Deep Sea Electronics Plc" 751 "Pacific Track" 750 "Joskin SA" 749 "Chart Inc." 748 "ISOTTA" 747 "Agratronix" 746 "SureFire Ag Systems, Inc." 745 "Cidra Corporate Services Inc." 644 "KUS USA" 643 "Bogballe A/S" 642 "Moog / Aspen Motion Technologies" 641 "Diverse Yacht Services" 640 "Power Solutions International" 639 "Startec s.r.l." 638 "KVH Industries, Inc." 637 "Bavaria Yachtbau GmbH" 636 "Divelbiss Corporation" 635 "Argo Tractors S.p.A." 634 "Rocky Research" 633 "TORC Robotics" 632 "Pepperl+Fuchs GmbH" 631 "Reltima" 630 "SmartDrive Systems Inc." 629 "Agri Info Design, Ltd." 628 "Falck Schmidt Defence Systems" 627 "Radio Ocean" 626 "AVL DiTEST GmbH" 625 "Global MRV Inc." 624 "Blackbox Machine Control Pty Ltd" 623 "Xirgo Technologies" 622 "Floyd Bell Inc" 621 "Hagie Manufacturing Company" 620 "Sevcon Ltd." 619 "Right Weigh Load Scales" 618 "Evrard SA" 617 "Zero Emission Vehicles" 616 "SMART-TEC s.r.o." 615 "Networkfleet, Verizon Telematics" 614 "ARLT Technologies GmbH" 613 "HKS Co., Ltd." 612 "Samwon IT" 611 "Esterline" 610 "Trail Tech" 609 "Walvoil S.p.A." 608 "Gale Banks Engineering" 607 "Knappco/Civacon" 606 "Intellian Technologies" 605 "Aventics GmbH" 604 "Indexator Rototilt Systems AB" 603 "Kereval" 602 "Nomad Digital Ltd." 601 "Navitas Systems" 600 "Aquatic AV" 599 "Spudnik Equipment Co, LLC" 598 "ABB Turbo Systems Ltd" 597 "Hydac Filter Systems GmbH" 596 "Brunelco Electronic Innovators B.V." 595 "CustomWare" 594 "Kongsberg Automotive" 593 "Sensata Technologies" 592 "tecsis GmbH" 591 "United States Coast Guard" 382 "National Agriculture and Food Research Organization" 381 "B & G" 380 "Suntech International Ltd." 379 "Yamabiko Corporation" 378 "Glendinning Marine Products" 377 "ifm electronic gmbh" 376 "Quake Global" 375 "Williams Controls Inc." 374 "Northern Lights, Inc." 373 "Electronic Design Inc." 372 "Delphi" 371 "Heinzmann GmbH & Co. KG" 370 "Rolls-Royce Marine AS" 369 "Power Torque Engineering Ltd" 368 "HANSENHOF_electronic" 367 "Fliegl Agrartechnik" 366 "Viewnyx Corp." 365 "Digi-Star, LLC" 364 "OEM Controls Inc." 363 "BEI Duncan" 362 "Poettinger Landtechnik GmbH (formerly Alois Poettinger Maschinenfabrik GmbH)" 361 "InMach" 360 "HJS Emission Technology GmbH & Co KG   (formerly HJS Fahrzeugtechnik GmbH & Co KG)" 359 "Ludwig Bergmann GmbH" 358 "Victron Energy B.V." 357 "Hardi International A/S" 356 "Fischer Panda Generators, Inc" 355 "Mastervolt International B.V." 354 "Junkkari OY" 353 "Hegemon Electronics, Inc." 352 "SAME DEUTZ-FAHR GROUP S.p.A." 351 "Thrane & Thrane" 350 "Noris Marine Systems GmbH & Co KG" 349 "Suonentieto" 348 "Amazonen Werke H. Dreyer" 347 "Honeywell" 346 "Control Solutions" 345 "Korean Maritime University" 344 "Parvus Corporation" 343 "Baumer Group" 342 "THOMAS MAGNETE GmbH" 341 "Boning GmbH & Co" 340 "Continental AG" 339 "Competence Center ISOBUS e.V." 338 "GRAF-SYTECO" 337 "Carraro S.p.A." 336 "APE s.r.o." 335 "Evo Electric Ltd" 334 "Takata-Petri AG" 333 "Hadley Products Corporation" 744 "Woosung Engineering Co., Ltd." 743 "Daemyung Elevator Co., Ltd." 742 "EROAD" 741 "Carling Technologies" 740 "e-Traction" 739 "LXNAV d.o.o." 738 "Blue Ink Technologies" 737 "Balluff GmbH" 736 "Terex Aerial Work Platforms - Genie" 735 "AEM Performance Electronics" 734 "REAPsystems" 733 "Intendia S.L." 732 "Gefran S.p.A." 731 "Modine Manufacturing Company" 730 "BERTHOUD AGRICOLE" 729 "Liebherr" 728 "Streumaster (formerly Streumaster / Panien)" 727 "Dhoot Transmission Pvt Ltd." 726 "MIDORI PRECISIONS" 725 "Hitachi Construction Machinery Co., Ltd." 724 "Electronic Applications, Inc." 723 "Jabil Inc." 722 "Contelec AG" 721 "Hypro" 720 "WITZ Corporation" 719 "Cojali S. L." 718 "Micronet Inc" 717 "Yacht Devices Ltd" 716 "Eaton Control & Power Conversion Division (CPCD)" 715 "Autonnic Research Ltd" 714 "Kobashi Kogyo Co., Ltd." 713 "US Hybrid Corporation" 712 "LOR Manufacturing Company Inc." 711 "DAS Co., LTD" 710 "Greentronics Ltd." 709 "Marquardt GmbH" 708 "Lars Thrane A/S" 707 "Rochester Gauges Inc" 706 "Shanghai Diesel Engine Corporation Limited" 705 "SVAB Hydraulik AB" 704 "JL Audio, Inc." 703 "Hydro Tab Marine Engineering" 702 "Weichai Power Co., Ltd." 701 "BigRoad Inc." 700 "K-Tec Earthmovers Inc." 699 "Harman International Industries" 698 "Scorpion Technologies Ltd." 697 "Ålö AB" 696 "DRS Network & Imaging Systems, LLC (DRS Technologies)" 695 "Weldon Technologies" 694 "GasTOPS Ltd." 693 "Agility Fuel Solutions (formerly Agility Fuel Systems)" 692 "Tanhay Corporation" 691 "Digitroll Agricultural Electronics" 690 "LINAK A/S" 689 "Aarcomm Systems Inc" 688 "Rockford Corp" 687 "Flight Systems, Inc." 686 "Taigene Electric Machinery Corp." 685 "ANEDO (formerly ANEDO Ltd.)" 684 "KEB" 683 "Fosen Elektro" 682 "Eckelmann AG" 681 "BEDIA Motorentechnik GmbH & Co. KG" 680 "AMVAC Chemical Corporation" 679 "Cimco Marine AB" 678 "KeepTruckin, Inc." 677 "DSA Daten- und Systemtechnik GmbH" 676 "Danfoss IXA A/S" 675 "Kawasaki Motors Corp., USA" 674 "Yara International ASA" 673 "Caruelle Nicolas" 672 "OPTIMA Concept" 671 "Innovative Controls Inc." 670 "STEMCO LP" 669 "Quantum Fuel Systems Technologies Worldwide, Inc" 668 "MacDon Industries Ltd." 667 "Bartec" 666 "Schaeffler Technologies AG & Co., KG" 665 "Gebr. Bode GmbH & Co. KG" 664 "Level Developments Ltd" 663 "Delta Systems, Inc" 662 "Kissling Elektrotechnik GmbH" 661 "SPAL Automotive S.r.l." 660 "Auto-Gaz Centrum" 659 "Data Panel Corp." 658 "Shenzhen Jiuzhou Himunication Technology Co., Ltd" 657 "Terzo Power Systems" 656 "PRO SOLUS do Brasil" 655 "Genge & Thoma AG" 654 "Kohler Power Systems, Detroit Engine Development Center (DEDC)" 653 "AEV, spol. s r. o." 652 "MicroControl GmbH & Co. KG" 651 "Takakita Co, Ltd." 650 "Seiko Epson Corp." 649 "Control-Q B.V." 648 "OJSC Ekran" 647 "Siloking" 646 "Veenhuis Machines B.V." 645 "esd electronic system design gmbh" 590 "ARGO-HYTOS GMBH" 589 "MICO, Inc." 588 "Vignal Systems" 587 "JCA Electronics" 586 "Suzuki Motor Corp" 585 "Industrial Electronic Controls" 584 "CarMedialab GmbH" 583 "Yachtcontrol" 582 "Innovative Software Engineering" 581 "Väderstad - Verken AB" 580 "San Jose Technology, Inc." 579 "KVH Industries, Inc." 578 "advanSea" 577 "Denchi Power Ltd  (formerly ABSL Power Solutions Limited)" 576 "Vectia" 575 "Lytx" 574 "Vishay Precision Group" 573 "Orolia Ltd" 572 "Fasse Valves" 571 "Marinecraft Co., Ltd." 570 "frenzel + berg electronic GmbH & Co. KG" 569 "LORD MicroStrain Sensing Systems" 568 "Makersan Ltd. Co." 567 "Lithiumstart LLC" 566 "Geode Technology, Inc." 565 "Micro-Trak Systems, Inc." 564 "Auto Power Electronic" 563 "LOHR Sistemas Eletronicos LTDA" 562 "Bombardier Transportation GmbH" 561 "b-plus GmbH" 560 "Iowa State University, Agricultural and Biosystems Engineering" 559 "Four Peaks Navigation" 558 "Davis Instruments Corp." 557 "Rockson Automation GmbH" 556 "Doosan Infracore Norway" 555 "Sasaki Corporation" 554 "iris-GmbH infrared & intelligent sensors" 553 "KIB Electronics" 552 "Matsuyama Plow Mfg Co, Ltd" 551 "Wexler CSD Ltd." 550 "SUN-A Corporation" 549 "ROAD Deutschland GmbH" 548 "TM4 Inc." 547 "Thomson Linear LLC" 546 "Maruyama Mfg Co, Inc." 545 "GS Hydraulics" 544 "Au Group Electronics" 543 "BAUER Maschinen GmbH" 542 "Dinamica Generale s.p.a." 541 "Total Fire Systems, Inc." 540 "Dinex A/S" 539 "Mobileview" 538 "Crop Ventures, Inc." 537 "Schrader Electronics Ltd." 536 "SSI Technologies" 535 "MOTORPAL, a.s." 534 "Webasto Thermo & Comfort SE" 533 "Doran Manufacturing, LLC" 532 "Onwa Marine Electronics Co Ltd." 531 "Genge & Thoma AG" 530 "NMEA" 529 "National Instruments Korea" 528 "Hoganas AB, Electric Drive Systems" 527 "GKN Walterscheid GmbH" 526 "LOFA Industries, Inc" 525 "Rust Sales INC" 524 "Vomax Instrumentation Pty. Ltd." 523 "Reggio Emilia Innovazione" 522 "Nebraska Tractor Test Laboratory" 521 "Clever Devices Ltd." 520 "Trapeze" 519 "Peeters Landbouwmachines b.v." 518 "Transas USA Inc." 517 "Noland Engineering" 516 "AVAT Automation GmbH" 515 "GINAF Trucks Nederland B.V." 514 "DISTek Integration, Inc." 513 "Precision Technology (Formerly FarmscanAg)" 512 "Inpower LLC" 511 "Sulky" 510 "Marinesoft Co. Ltd" 509 "MOTORTECH GmbH" 508 "Transtech Innovations" 507 "ISOBUS Test Center" 506 "IHI STAR Machinery Corporation" 505 "Yetter Farm Equipment" 504 "Vesper Marine" 503 "Naviop S.R.L." 502 "Attwood Corporation" 501 "Agrotronix S.A." 500 "Oxbo International Corporation" 499 "LCJ Capteurs" 498 "Innovative Design Solutions, Inc." 497 "SENTRON Sistemas Embarcados" 496 "W. Gessmann GmbH" 495 "HOLMER Maschinenbau GmbH" 494 "Synerject" 493 "Watcheye" 492 "Inergy Automotive Systems" 491 "Penny and Giles Ltd" 490 "QuikQ" 489 "Appareo Systems, LLC" 488 "The Charles Machine Works, Inc." 487 "DSE Test Solutions A/S" 486 "Westport Innovations Inc." 485 "MATT automotive" 484 "Headsight Inc." 483 "Valeo" 482 "Tricon Electronics" 481 "Chetco Digital Instruments" 480 "EnerDel, Inc." 479 "Vapor Bus International" 478 "OceanSat B.V." 477 "OilQuick AB" 476 "Hummingbird Marine Electronics" 475 "GME" 474 "Persen Technologies Inc." 473 "Boss Industries, Inc." 472 "Tenneco Inc." 471 "Sea Cross Marine AB" 470 "SI-TEX Marine Electronics" 469 "RA Consulting GmbH" 468 "Tyco Fire Protection Products" 467 "Lely Industries N.V." 466 "Veethree Electronics and Marine LLC" 465 "Ashcroft Inc" 464 "Leach International Corporation" 463 "PROBOTIQ" 462 "IHI Shibaura Machinery Corporation" 461 "HAWE Hydraulik SE" 460 "San Giorgio S.E.I.N." 459 "Alltek Marine Electronics Corp" 458 "Control Solutions, Inc." 457 "RUSELPROM-ElectricDrive Ltd" 456 "General Kinetics" 455 "ADZ NAGANO GmbH" 454 "NGK Spark Plug Co. Ltd" 453 "Cooper Bussmann" 452 "WIKA Alexander Wiegand SE & Co. KG" 451 "Parker Hannifin Corp" 450 "Dycor Technologies Ltd." 449 "Polaris Industries Inc" 448 "Stanadyne Corporation, Electronics Systems" 447 "Great Plains Mfg." 446 "CertTech, L.L.C." 445 "KAT MECHATRONIC, Electronic Product Division" 444 "ITT Power Solutions" 443 "SignalQuest, Inc." 442 "Horsch Maschinen GmbH" 441 "PTG Reifendruckregelsysteme GmbH" 440 "Cummins Power Generation" 439 "Hyundai Heavy Industries" 438 "Comar Systems Ltd" 437 "Digital Yacht Limited" 436 "Kinze Manufacturing" 435 "Zunhammer GmbH" 434 "Stored Energy Systems" 433 "Rowe Electronics" 432 "S&A Systems, Inc." 431 "Tohatsu Corporation" 430 "Auteq Telematica S.A." 429 "Rota Engineering Ltd." 425 "Methode Electronics Inc, MDI" 424 "Odyne LLC" 423 "BSM Wireless, Inc." 422 "True Heading AB" 421 "Vertex Standard Co, Ltd" 420 "Vermeer Corporation, ACS Group" 419 "Fusion Electronics Ltd" 418 "Intellistick Inc" 417 "KZValve" 416 "Kubota Corporation" 415 "Valid Manufacturing Ltd." 414 "Cattron Group International" 413 "Datapross Nijbroek bv" 412 "WebTech Wireless Inc." 411 "Hy-Drive Technologies Ltd." 410 "COBO S.p.A. Divisione 3B6" 409 "Transfluid S.r.L." 408 "Corvus Energy Ltd." 407 "Comtech Mobile Datacom" 406 "Vecima Networks Inc." 405 "Wema System AS" 404 "Com Nav Marine Ltd" 403 "Trackwell ADS, Inc." 402 "Simma Software, Inc." 401 "Torqeedo GmbH" 400 "Livorsi Marine" 399 "ISEKI & Co., Ltd." 398 "Hilite International" 397 "Sanyo-kiki Co Ltd." 396 "Beyond Measure" 395 "GENTEC S.R.L." 394 "Capi 2 Nederland B.V." 393 "Harvest Tec, Inc" 392 "Tianyuan Technology Co Ltd." 391 "Electronic Design for Industry, Inc" 390 "Partech Inc." 389 "Benchmark Electronics, Minnesota Division" 388 "Innomatix, LLC" 387 "Orscheln Products, LLC" 386 "JLG Automation BVBA" 385 "Johnson Outdoor Marine Electronics" 384 "Camano Light" 383 "MCL Industries" 332 "HWH Corporation" 331 "Horton, Inc." 330 "Kidde Aerospace and Defense" 329 "Deif A/S" 328 "Qwerty Electronik AB" 327 "Sonceboz SA" 326 "Akron Brass Company" 325 "ASM Automation Sensorik Messtechnik GmbH" 324 "Snap-on Diagnostics" 323 "Mobileye Vision Technologies Ltd." 322 "MICHENKA s.r.o." 321 "Ultra Electronics, Electrics" 320 "Miedema Landbouwwerktuigenfabriek B.V." 319 "Cadec Global" 318 "SAT Plan" 317 "Navtronics Bvba" 316 "ITT Flow Control" 315 "Icom Incorporated" 314 "CSM GmbH" 313 "Ilmor Engineering, Inc." 312 "Lectronix, Inc." 311 "Patrick Power Products" 310 "TECNORD srl" 309 "Krauss-Maffei Wegmann GmbH & Co. KG" 308 "Cyntrx" 307 "MAS Technologies" 306 "Sleipner Motor AB" 305 "NovAtel Inc" 304 "EmpirBus AB" 303 "CTS Corporation" 302 "Nissin Kogyo Co., LTD" 301 "Parker Hannifin (UK) Ltd FDE group" 300 "Systron Donner Automotive" 299 "Rauch" 298 "Holley Performance" 297 "Zonar Systems Inc" 296 "micro dynamics GmbH" 295 "BEP Marine" 294 "Grayhill Inc." 293 "Spyder Controls Corp." 292 "IKUSI - Angel Iglesias S.A." 291 "Groeneveld Transport Efficiency BV" 290 "Kuebler GmbH" 289 "Watlow" 288 "Mitsubishi FUSO Truck & Bus Corp." 287 "NTech Industries, Inc" 286 "Coelmo srl" 285 "Sea Recovery Corp" 284 "Mobile Tech Chile" 283 "CWF Hamilton & Co Ltd" 282 "Medallion Instrumentation Systems" 281 "Precision Governors LLC" 280 "Leica Geosystems Pty Ltd" 279 "Geometris LP" 278 "Takata Electronics" 277 "LHP Telematics" 276 "Aqua-Hot Heating Systems" 275 "Navico Egersund AS" 274 "LTW Technology Co., LTD" 273 "Active Research Limited" 272 "Gross Mechanical Laboratories, Inc" 271 "Cole Hersee" 270 "Tennant" 269 "Saft America Inc.,  Space & Defense Division" 268 "Accurate Technologies" 267 "Red Lion Controls, Inc" 266 "International Thermal Research Ltd" 265 "MTS Sensor Technologie GmbH" 264 "Autolync" 263 "IMMI" 262 "HydraForce, Inc" 261 "Red Dot Corporation" 260 "Reichhardt GmbH Steuerungstechnik" 259 "Jetter AG" 258 "ARAG" 257 "Honda Motor Co., Ltd" 256 "Tyco Electronics AMP" 255 "MEAS France" 254 "GE Sensing" 253 "Mobile Control Systems" 252 "Sensor-Technik Wiedemann GmbH" 251 "German Agricultural Society, Test Center (DLG)" 250 "Kuhn Group" 249 "Schaltbau GmbH" 248 "Cooper Standard Automotive Active Systems Group" 247 "ePULSE" 246 "Class 1, Inc" 245 "Capstan Ag Systems, Inc." 244 "Techno-Matic" 243 "eRide, Inc." 242 "Kokusandenki Co. Ltd" 241 "Schneider Automation SAS" 240 "Vanair Mfg" 239 "May & Scofield Ltd" 238 "ZF Friedrichshafen AG" 237 "Agtron Enterprises Inc" 236 "NORAC Systems International Inc" 235 "SailorMade Marine Telemetry - Tetra Technology Ltd." 234 "Mondial electronic GmbH" 233 "Yacht Monitoring Solutions Inc." 232 "TSD Integrated Controls" 231 "Topcon Positioning Systems, Inc." 230 "Saucon Technologies" 229 "Garmin International Inc." 228 "Unused (formerly ZF Marine Electronics)" 227 "Lykketronic A/S" 226 "Monaco Coach Corporation" 225 "SKF" 224 "EMMI Network, S.L." 223 "Vaueo Retarder Co., Ltd." 222 "Generac Power Systems, Inc." 221 "SiE" 220 "Beede Electrical Instrument Company, Inc" 219 "Cat OEM Solutions" 218 "Gits Manufacturing Company" 217 "RM Michaelides Software & Elektronik GmbH" 216 "Paneltronics Inc." 215 "Aetna Engineering/Fireboy-Xintex" 214 "MC elettronica Srl" 213 "CNH Belgium N.V." 212 "Sure Power Industries, Inc" 211 "DNA Group" 210 "Iteris, Inc." 209 "Bell Equip. Co. SA (PTY) LTD" 208 "Drew Technologies, Inc" 207 "Otto Engineering" 206 "port GmbH" 205 "SmarTire Systems Inc" 204 "The Morey Corporation" 203 "MILtronik GmbH" 202 "Curtis Instruments, Inc" 201 "Disenos y Tecnologia S.A." 200 "MGM Brakes" 199 "ACTIA Group (formerly Actia Corp)" 198 "Mystic Valley Communications" 197 "Mechron Power Systems" 196 "LEMKEN GmbH & Co KG" 195 "General Engine Products" 194 "TriMark Corporation" 193 "Jeppesen Marine" 192 "Floscan" 191 "XRS Corporation (formerly XATA Corporation)" 190 "Hella KGaA Hueck & Co" 189 "QUALCOMM" 188 "EMP Corp" 187 "Air-Weigh" 186 "Altronic, Inc" 185 "Beede Electrical Instrument Company" 184 "EIA Electronics" 183 "KDS Controls, Inc" 182 "Vehicle Systems Engineering B.V." 181 "Coretronics, Inc." 180 "Smart Power Systems" 179 "TeeJet Technologies Springfield (formerly Midwest Technologies Illinois, LLC)" 178 "Continental Automotive GmbH (formerly Siemens VDO Automotive AG)" 177 "Diagnostic Systems Associates" 176 "Moritz Aerospace" 175 "Veris Technologies, Inc." 174 "AB Volvo Penta" 173 "Ryeso, Inc." 172 "Yanmar Co., Ltd. (formerly Yanmar Marine USA)" 171 "Topcon Electronics GmbH & Co. KG (formerly Wachendorff Elektronik GmbH & Co. KG)" 170 "Computronics Corporation Ltd." 169 "Marlin Technologies Inc." 168 "Xantrex" 167 "JLG Industries Inc" 166 "John Deere Electronic Solutions (formerly Phoenix International)" 165 "CPAC Systems AB" 164 "MTU Friedrichshafen GmbH (formerly DaimlerChrysler Off-Highway)" 163 "BRP Inc." 162 "Axiomatic Technologies" 161 "Offshore Systems (UK) Ltd" 160 "Nido" 159 "NTech Industries Inc" 158 "Firestone Industrial Products Company" 157 "ISSPRO Inc." 156 "ITT Industries - Cannon" 155 "Vetronix Corporation" 154 "Westerbeke Corporation" 153 "Woodward, Industrial Controls Division" 152 "elobau GmbH & Co. KG" 151 "Raven Industries, Inc." 150 "Fleetguard" 149 "Holset" 148 "Blue Water Data, Inc." 147 "Nautibus electronic GmbH" 146 "Maxima Technologies" 145 "MurCal Controls" 144 "Mercury Marine" 143 "W. Gmeiner GmbH & Co." 142 "TRW Automotive (Commercial Steering Systems)" 141 "Thales Navigation Ltd." 140 "Lowrance Electronics, Inc." 139 "Caterpillar Trimble Control Technologies (CTCT), LLC" 138 "Georg Fritzmeier GmbH & Co. KG" 137 "Maretron" 136 "Komatsu Ltd" 135 "Airmar Technology Corporation" 134 "Iris Technology Ltd" 133 "Bucher Schoerling GmbH" 132 "Mulag-Fahrzeugwerk" 131 "ITT Industries" 130 "Nido - Universal Machines B.V." 129 "OMNEX Control Systems Inc." 128 "Gerhard Duecker GmbH & Co. KG" 127 "Holland USA" 126 "Driver Tech" 125 "Nevada Automotive Test Center" 124 "Hydac Electronic" 123 "Basler Electric" 122 "FG Wilson (Engineering) Limited" 121 "HED (Hydro Electronic Devices, Inc.)" 120 "RDS Technology Ltd" 119 "IntegriNautics  " 118 "Intron GmbH" 117 "HUSCO International" 116 "BEELINE Technologies" 115 "NACCO Materials Handling Group, Inc." 114 "EControls, Inc." 113 "Stress-Tek, Inc." 112 "MECALAC" 111 "Bernard Krone Holding SE & Co. KG (formerly Maschinenfabrik Bernard Krone GmbH)" 110 "EPIQ Sensor-Nite" 109 "TeeJet Technologies Denmark (formerly LH Technologies ApS)" 108 "WTK-Elecktronik GmbH" 107 "Grimme Landmaschinen GmbH & Co. KG" 106 "BAE Systems Controls, Inc." 105 "Kiepe Elektrik GmbH & Co. KG" 104 "CLAAS KGaA mbH (formerly CLAAS Selbstfahrende Erntemaschinen GmbH)" 103 "CLAAS E-Systems GmbH (formerly CLAAS E-Systems KGaA mbH & Co. KG)" 102 "AGCO (formerly AGCO GmbH & Co.)" 101 "Sensoria" 100 "VDO Technik AG" 99 "International Transmissions Ltd (ITL)" 98 "Mueller-Elektronik GmbH & Co" 97 "Ag Leader Technology, Inc." 96 "Mech@tronic IT GmbH" 95 "Pacific Insight Electronics Corp." 94 "CNH Industrial N.V. (formerly CNH Global N.V.)" 93 "Perkins Engines Company Ltd." 92 "Ag-Chem Equipment Co., Inc." 91 "BSG Bodensee Steuergeraete GmbH" 90 "Knorr-Bremse SfN GmbH" 89 "Kverneland Group, Electronics Division" 88 "Hemisphere GPS Inc (formerly Satloc Precision GPS)" 87 "J.C. Bamford Excavators Ltd (JCB)" 86 "C. E. Niehoff & Company" 85 "Kohler Co" 84 "New Holland UK Limited" 83 "Bendix VORAD Technologies (formerly Eaton VORAD Technologies)" 82 "Bobcat/Ingersoll-Rand (formerly Melroe/Ingersoll-Rand)" 81 "Fire Research Corp." 80 "Twin Disc, Inc." 79 "Daimler Benz AG - Engine Division (PBM)" 78 "Frank W. Murphy Manufacturing, Inc" 77 "Deere Power Systems Group" 76 "unused (formerly Deere & Co, Construction Division)" 75 "Deere & Co, Agricultural Division" 74 "Eaton Axle-Brake Division" 73 "LeTourneau, Inc." 72 "Sisu Corporation" 71 "Vansco Electronics Ltd." 70 "Flex-coil Limited" 69 "Trimble Navigation" 68 "Scania" 67 "John Deere Coffeyville Works (formerly Funk Manufacturing Company)" 66 "John Deere Construction Equipment Division" 65 "MAN Nutzfahrzeuge AG" 64 "Unused (formerly SpectraPrecision Laserplane, then SpectraPhysics)" 63 "ZF Industries Inc." 62 "Wabco" 61 "Volvo Truck Corp." 60 "Volvo Trucks North America Inc." 59 "VES Inc." 58 "SPX Corporation, OTC Div" 57 "Danfoss  (formerly Sauer Sundstrand Co, then Sauer-Danfoss Co)" 56 "SAIC" 55 "Ryder System Inc." 54 "Meritor Wabco" 53 "Continental Automotive Systems US, Inc. (formerly Rockwell Land Transportation)" 52 "Meritor Automotive, Inc. (formerly Rockwell Automotive)" 51 "Robert Bosch GmbH" 50 "Robert Bosch Corp" 49 "RE America Inc." 48 "Pollak Alphabet" 47 "Phillips Semiconductor" 46 "Noregon Systems, Inc  (formerly Parasoft Computing Solutions)" 45 "PACCAR" 44 "Nippondenso Co. Ltd." 43 "International Truck and Engine Corporation - Vehicle Electronics (formerly Navistar Intl Trans Corp.)" 42 "International Truck and Engine Corporation - Engine Electronics  (formerly Navistar Intl Trans Co., Engine Electronics)" 41 "Motorola Inc." 40 "Motorola AIEG Inc." 39 "Microfirm Inc." 38 "Micro Processor Systems Inc." 37 "Mack Trucks Inc." 36 "Lucas Ind." 35 "Kenworth Truck Co." 34 "Kelsey Hayes Co." 33 "John Deere" 32 "Jacobs Vehicle Systems" 31 "J Pollak Corp" 30 "Isuzu Motors Ltd" 29 "Hino Motors Ltd." 28 "Grote Ind. Inc." 27 "GMC" 26 "General Motors Corp, Service Technology Grp" 25 "Daimler Trucks North America LLC (formerly Freightliner LLC)" 24 "Ford Motor Co., Vehicle Controls" 23 "Ford Motor Co., Heavy Truck" 22 "Ford Motor Co., Electronic Concepts & Systems" 21 "Echlin Inc., Midland Brake Inc." 20 "Eaton Ltd" 19 "Eaton Corp. Trucking Info Services" 18 "Eaton Corp, Transmission Div." 17 "Eaton Corp, Corp Res & Dev" 16 "Eaton Corp" 15 "DICKEY-john Corporation" 14 "Detroit Diesel Corporation" 13 "Delco Electronics" 12 "Deere & Company, Precision Farming" 11 "Dearborn Group Inc." 10 "Cummins Inc (formerly Cummins Engine Co)" 9 "Chrysler Corp." 8 "Caterpillar Inc." 7 "Case Corp." 6 "Berifors Electronics AB" 5 "AMP Inc." 4 "Ametek-Dixson" 3 "Ametek, US Gauge Division" 2 "Allison Transmission, Inc." 1 "Bendix Commercial Vehicle Systems LLC (formerly Allied Signal Inc.)" 0 "Reserved" ;
VAL_ 2565799426 VehicleSystem 0 "Non-specific System" 127 "Not Available" ;
VAL_ 2565799426 VehicleSystem5 127 "Not Available" 0 "Ind. Process Control Stationary" ;
VAL_ 2565799426 VehicleSystem4 125 "Entertainment" 120 "Display" 85 "External Environment" 75 "Sensor Communication Interface" 35 "Electrical Generation" 100 "Deck, Cargo and Fishing Equipment" 90 "Internal Environment" 80 "Instrumentation/General Systems (deprecate)" 70 "Communications" 60 "Navigation" 50 "Propulsion" 40 "Steering and Control Surfaces" 30 "Electrical Distribution" 25 "Inter/Intranetwork Device" 20 "Safety Systems" 10 "System Tools" 127 "Not Available" 0 "Non-specific System" ;
VAL_ 2565799426 VehicleSystem3 8 "Grader" 7 "Four Wheel Drive Loader" 6 "Forklift" 5 "Excavator" 4 "Crawler" 3 "Backhoe" 2 "Articulated Dump Truck" 1 "Skid Steer Loader" 127 "Not Available" 0 "Non-specific System" ;
VAL_ 2565799426 VehicleSystem2 25 "Slurry Applicators" 24 "Utility Vehicles" 23 "Mulchers" 22 "Timber Processing Machines" 21 "Timber loaders" 20 "Forwarders" 19 "Timber Harvesters" 17 "Sensor Systems" 16 "Skidder" 15 "Earth Work" 14 "Special Crops" 13 "Powered Auxiliary Device" 12 "Farm Yard Operations" 11 "Transport/Trailer" 10 "Irrigation" 9 "Forage" 8 "Root Harvesters" 7 "Harvesters" 6 "Sprayers" 5 "Fertilizers" 4 "Planters/Seeders" 3 "Secondary Tillage" 2 "Tillage" 1 "Tractor" 127 "Not Available" 0 "Non-specific System" ;
VAL_ 2565799426 VehicleSystem1 2 "Trailer" 1 "Tractor" 127 "Not Available" 0 "Non-specific System" ;
VAL_ 2148466430 InvertedPF 129 "orig: 126 / 0x7E" 255 "orig: 0 / 0x0" 254 "orig: 1 / 0x1" 253 "orig: 2 / 0x2" 252 "orig: 3 / 0x3" 251 "orig: 4 / 0x4" 250 "orig: 5 / 0x5" 249 "orig: 6 / 0x6" 248 "orig: 7 / 0x7" 247 "orig: 8 / 0x8" 246 "orig: 9 / 0x9" 245 "orig: 10 / 0xA" 244 "orig: 11 / 0xB" 243 "orig: 12 / 0xC" 242 "orig: 13 / 0xD" 241 "orig: 14 / 0xE" 240 "orig: 15 / 0xF" 239 "orig: 16 / 0x10" 238 "orig: 17 / 0x11" 237 "orig: 17 / 0x12" 236 "orig: 19 / 0x13" 235 "orig: 20 / 0x14" 234 "orig: 21 / 0x15" 233 "orig: 22 / 0x16" 232 "orig: 23 / 0x17" 231 "orig: 24 / 0x18" 230 "orig: 25 / 0x19" 229 "orig: 26 / 0x1A" 228 "orig: 27 / 0x1B" 227 "orig: 28 / 0x1C" 226 "orig: 29 / 0x1D" 225 "orig: 30 / 0x1E" 224 "orig: 31 / 0x1F" 223 "orig: 32 / 0x20" 222 "orig: 33 / 0x21" 221 "orig: 34 / 0x22" 220 "orig: 35 / 0x23" 219 "orig: 36 / 0x24" 218 "orig: 37 / 0x25" 217 "orig: 38 / 0x26" 216 "orig: 39 / 0x27" 215 "orig: 40 / 0x28" 214 "orig: 41 / 0x29" 213 "orig: 42 / 0x2A" 212 "orig: 43 / 0x2B" 211 "orig: 44 / 0x2C" 210 "orig: 45 / 0x2D" 209 "orig: 46 / 0x2E" 208 "orig: 47 / 0x2F" 207 "orig: 48 / 0x30" 206 "orig: 49 / 0x31" 205 "orig: 50 / 0x32" 204 "orig: 51 / 0x33" 203 "orig: 52 / 0x34" 202 "orig: 53 / 0x35" 201 "orig: 54 / 0x36" 200 "orig: 55 / 0x37" 199 "orig: 56 / 0x38" 198 "orig: 57 / 0x39" 197 "orig: 58 / 0x3A" 196 "orig: 59 / 0x3B" 195 "orig: 60 / 0x3C" 194 "orig: 61 / 0x3D" 193 "orig: 62 / 0x3E" 192 "orig: 63 / 0x3F" 191 "orig: 64 / 0x40" 190 "orig: 65 / 0x41" 189 "orig: 66 / 0x42" 188 "orig: 67 / 0x43" 187 "orig: 68 / 0x44" 186 "orig: 69 / 0x45" 185 "orig: 70 / 0x46" 184 "orig: 71 / 0x47" 183 "orig: 72 / 0x48" 182 "orig: 73 / 0x49" 181 "orig: 74 / 0x4A" 180 "orig: 75 / 0x4B" 179 "orig: 76 / 0x4C" 178 "orig: 77 / 0x4D" 177 "orig: 78 / 0x4E" 176 "orig: 79 / 0x4F" 175 "orig: 80 / 0x50" 174 "orig: 81 / 0x51" 173 "orig: 82 / 0x52" 172 "orig: 83 / 0x53" 171 "orig: 84 / 0x54" 170 "orig: 85 / 0x55" 169 "orig: 86 / 0x56" 168 "orig: 87 / 0x57" 167 "orig: 88 / 0x58" 166 "orig: 89 / 0x59" 165 "orig: 90 / 0x5A" 164 "orig: 91 / 0x5B" 163 "orig: 92 / 0x5C" 162 "orig: 93 / 0x5D" 161 "orig: 94 / 0x5E" 160 "orig: 95 / 0x5F" 159 "orig: 96 / 0x60" 158 "orig: 97 / 0x61" 157 "orig: 98 / 0x62" 156 "orig: 99 / 0x63" 155 "orig: 100 / 0x64" 154 "orig: 101 / 0x65" 153 "orig: 102 / 0x66" 152 "orig: 103 / 0x67" 151 "orig: 104 / 0x68" 150 "orig: 105 / 0x69" 149 "orig: 106 / 0x6A" 148 "orig: 107 / 0x6B" 147 "orig: 108 / 0x6C" 146 "orig: 109 / 0x6D" 145 "orig: 110 / 0x6E" 144 "orig: 111 / 0x6F" 143 "orig: 112 / 0x70" 142 "orig: 113 / 0x71" 141 "orig: 114 / 0x72" 140 "orig: 115 / 0x73" 139 "orig: 116 / 0x74" 138 "orig: 117 / 0x75" 137 "orig: 118 / 0x76" 136 "orig: 119 / 0x77" 135 "orig: 120 / 0x78" 134 "orig: 121 / 0x79" 133 "orig: 122 / 0x7A" 132 "orig: 123 / 0x7B" 131 "orig: 124 / 0x7C" 130 "orig: 125 / 0x7D" 128 "orig: 127 / 0x7F" 127 "orig: 128 / 0x80" 126 "orig: 129 / 0x81" 125 "orig: 130 / 0x82" 124 "orig: 131 / 0x83" 123 "orig: 132 / 0x84" 122 "orig: 133 / 0x85" 121 "orig: 134 / 0x86" 120 "orig: 135 / 0x87" 119 "orig: 136 / 0x88" 118 "orig: 137 / 0x89" 117 "orig: 138 / 0x8A" 116 "orig: 139 / 0x8B" 115 "orig: 140 / 0x8C" 114 "orig: 141 / 0x8D" 113 "orig: 142 / 0x8E" 112 "orig: 143 / 0x8F" 111 "orig: 144 / 0x90" 110 "orig: 145 / 0x91" 109 "orig: 146 / 0x92" 108 "orig: 147 / 0x93" 107 "orig: 148 / 0x94" 106 "orig: 149 / 0x95" 105 "orig: 150 / 0x96" 104 "orig: 151 / 0x97" 103 "orig: 152 / 0x98" 102 "orig: 153 / 0x99" 101 "orig: 154 / 0x9A" 100 "orig: 155 / 0x9B" 99 "orig: 156 / 0x9C" 98 "orig: 157 / 0x9D" 97 "orig: 158 / 0x9E" 96 "orig: 159 / 0x9F" 95 "orig: 160 / 0xA0" 94 "orig: 161 / 0xA1" 93 "orig: 162 / 0xA2" 92 "orig: 163 / 0xA3" 91 "orig: 164 / 0xA4" 90 "orig: 165 / 0xA5" 89 "orig: 166 / 0xA6" 88 "orig: 167 / 0xA7" 87 "orig: 168 / 0xA8" 86 "orig: 169 / 0xA9" 85 "orig: 170 / 0xAA" 84 "orig: 171 / 0xAB" 83 "orig: 172 / 0xAC" 82 "orig: 173 / 0xAD" 81 "orig: 174 / 0xAE" 80 "orig: 175 / 0xAF" 79 "orig: 176 / 0xB0" 78 "orig: 177 / 0xB1" 77 "orig: 178 / 0xB2" 76 "orig: 179 / 0xB3" 75 "orig: 180 / 0xB4" 74 "orig: 181 / 0xB5" 73 "orig: 182 / 0xB6" 72 "orig: 183 / 0xB7" 71 "orig: 184 / 0xB8" 70 "orig: 185 / 0xB9" 69 "orig: 186 / 0xBA" 68 "orig: 187 / 0xBB" 67 "orig: 188 / 0xBC" 66 "orig: 189 / 0xBD" 65 "orig: 190 / 0xBE" 64 "orig: 191 / 0xBF" 63 "orig: 192 / 0xC0" 62 "orig: 193 / 0xC1" 61 "orig: 194 / 0xC2" 60 "orig: 195 / 0xC3" 59 "orig: 196 / 0xC4" 58 "orig: 197 / 0xC5" 57 "orig: 198 / 0xC6" 56 "orig: 199 / 0xC7" 55 "orig: 200 / 0xC8" 54 "orig: 201 / 0xC9" 53 "orig: 202 / 0xCA" 52 "orig: 203 / 0xCB" 51 "orig: 204 / 0xCC" 50 "orig: 205 / 0xCD" 49 "orig: 206 / 0xCE" 48 "orig: 207 / 0xCF" 47 "orig: 208 / 0xD0" 46 "orig: 209 / 0xD1" 45 "orig: 210 / 0xD2" 44 "orig: 211 / 0xD3" 43 "orig: 212 / 0xD4" 42 "orig: 213 / 0xD5" 41 "orig: 214 / 0xD6" 40 "orig: 215 / 0xD7" 39 "orig: 216 / 0xD8" 38 "orig: 217 / 0xD9" 37 "orig: 218 / 0xDA" 36 "orig: 219 / 0xDB" 35 "orig: 220 / 0xDC" 34 "orig: 221 / 0xDD" 33 "orig: 222 / 0xDE" 32 "orig: 223 / 0xDF" 31 "orig: 224 / 0xE0" 30 "orig: 225 / 0xE1" 29 "orig: 226 / 0xE2" 28 "orig: 227 / 0xE3" 27 "orig: 228 / 0xE4" 26 "orig: 229 / 0xE5" 25 "orig: 230 / 0xE6" 24 "orig: 231 / 0xE7" 23 "orig: 232 / 0xE8" 22 "orig: 233 / 0xE9" 21 "orig: 234 / 0xEA" 20 "orig: 235 / 0xEB" 19 "orig: 236 / 0xEC" 18 "orig: 237 / 0xED" 17 "orig: 238 / 0xEE" 16 "orig: 239 / 0xEF" 15 "orig: 240 / 0xF0" 14 "orig: 241 / 0xF1" 13 "orig: 242 / 0xF2" 12 "orig: 243 / 0xF3" 11 "orig: 244 / 0xF4" 10 "orig: 245 / 0xF5" 9 "orig: 246 / 0xF6" 8 "orig: 247 / 0xF7" 7 "orig: 248 / 0xF8" 6 "orig: 249 / 0xF9" 5 "orig: 250 / 0xFA" 4 "orig: 251 / 0xFB" 3 "orig: 252 / 0xFC" 2 "orig: 253 / 0xFD" 1 "orig: 254 / 0xFE" 0 "orig: 255 / 0xFF" ;
VAL_ 2148466430 InvertedPS 129 "orig: 126 / 0x7E" 255 "orig: 0 / 0x0" 254 "orig: 1 / 0x1" 253 "orig: 2 / 0x2" 252 "orig: 3 / 0x3" 251 "orig: 4 / 0x4" 250 "orig: 5 / 0x5" 249 "orig: 6 / 0x6" 248 "orig: 7 / 0x7" 247 "orig: 8 / 0x8" 246 "orig: 9 / 0x9" 245 "orig: 10 / 0xA" 244 "orig: 11 / 0xB" 243 "orig: 12 / 0xC" 242 "orig: 13 / 0xD" 241 "orig: 14 / 0xE" 240 "orig: 15 / 0xF" 239 "orig: 16 / 0x10" 238 "orig: 17 / 0x11" 237 "orig: 17 / 0x12" 236 "orig: 19 / 0x13" 235 "orig: 20 / 0x14" 234 "orig: 21 / 0x15" 233 "orig: 22 / 0x16" 232 "orig: 23 / 0x17" 231 "orig: 24 / 0x18" 230 "orig: 25 / 0x19" 229 "orig: 26 / 0x1A" 228 "orig: 27 / 0x1B" 227 "orig: 28 / 0x1C" 226 "orig: 29 / 0x1D" 225 "orig: 30 / 0x1E" 224 "orig: 31 / 0x1F" 223 "orig: 32 / 0x20" 222 "orig: 33 / 0x21" 221 "orig: 34 / 0x22" 220 "orig: 35 / 0x23" 219 "orig: 36 / 0x24" 218 "orig: 37 / 0x25" 217 "orig: 38 / 0x26" 216 "orig: 39 / 0x27" 215 "orig: 40 / 0x28" 214 "orig: 41 / 0x29" 213 "orig: 42 / 0x2A" 212 "orig: 43 / 0x2B" 211 "orig: 44 / 0x2C" 210 "orig: 45 / 0x2D" 209 "orig: 46 / 0x2E" 208 "orig: 47 / 0x2F" 207 "orig: 48 / 0x30" 206 "orig: 49 / 0x31" 205 "orig: 50 / 0x32" 204 "orig: 51 / 0x33" 203 "orig: 52 / 0x34" 202 "orig: 53 / 0x35" 201 "orig: 54 / 0x36" 200 "orig: 55 / 0x37" 199 "orig: 56 / 0x38" 198 "orig: 57 / 0x39" 197 "orig: 58 / 0x3A" 196 "orig: 59 / 0x3B" 195 "orig: 60 / 0x3C" 194 "orig: 61 / 0x3D" 193 "orig: 62 / 0x3E" 192 "orig: 63 / 0x3F" 191 "orig: 64 / 0x40" 190 "orig: 65 / 0x41" 189 "orig: 66 / 0x42" 188 "orig: 67 / 0x43" 187 "orig: 68 / 0x44" 186 "orig: 69 / 0x45" 185 "orig: 70 / 0x46" 184 "orig: 71 / 0x47" 183 "orig: 72 / 0x48" 182 "orig: 73 / 0x49" 181 "orig: 74 / 0x4A" 180 "orig: 75 / 0x4B" 179 "orig: 76 / 0x4C" 178 "orig: 77 / 0x4D" 177 "orig: 78 / 0x4E" 176 "orig: 79 / 0x4F" 175 "orig: 80 / 0x50" 174 "orig: 81 / 0x51" 173 "orig: 82 / 0x52" 172 "orig: 83 / 0x53" 171 "orig: 84 / 0x54" 170 "orig: 85 / 0x55" 169 "orig: 86 / 0x56" 168 "orig: 87 / 0x57" 167 "orig: 88 / 0x58" 166 "orig: 89 / 0x59" 165 "orig: 90 / 0x5A" 164 "orig: 91 / 0x5B" 163 "orig: 92 / 0x5C" 162 "orig: 93 / 0x5D" 161 "orig: 94 / 0x5E" 160 "orig: 95 / 0x5F" 159 "orig: 96 / 0x60" 158 "orig: 97 / 0x61" 157 "orig: 98 / 0x62" 156 "orig: 99 / 0x63" 155 "orig: 100 / 0x64" 154 "orig: 101 / 0x65" 153 "orig: 102 / 0x66" 152 "orig: 103 / 0x67" 151 "orig: 104 / 0x68" 150 "orig: 105 / 0x69" 149 "orig: 106 / 0x6A" 148 "orig: 107 / 0x6B" 147 "orig: 108 / 0x6C" 146 "orig: 109 / 0x6D" 145 "orig: 110 / 0x6E" 144 "orig: 111 / 0x6F" 143 "orig: 112 / 0x70" 142 "orig: 113 / 0x71" 141 "orig: 114 / 0x72" 140 "orig: 115 / 0x73" 139 "orig: 116 / 0x74" 138 "orig: 117 / 0x75" 137 "orig: 118 / 0x76" 136 "orig: 119 / 0x77" 135 "orig: 120 / 0x78" 134 "orig: 121 / 0x79" 133 "orig: 122 / 0x7A" 132 "orig: 123 / 0x7B" 131 "orig: 124 / 0x7C" 130 "orig: 125 / 0x7D" 128 "orig: 127 / 0x7F" 127 "orig: 128 / 0x80" 126 "orig: 129 / 0x81" 125 "orig: 130 / 0x82" 124 "orig: 131 / 0x83" 123 "orig: 132 / 0x84" 122 "orig: 133 / 0x85" 121 "orig: 134 / 0x86" 120 "orig: 135 / 0x87" 119 "orig: 136 / 0x88" 118 "orig: 137 / 0x89" 117 "orig: 138 / 0x8A" 116 "orig: 139 / 0x8B" 115 "orig: 140 / 0x8C" 114 "orig: 141 / 0x8D" 113 "orig: 142 / 0x8E" 112 "orig: 143 / 0x8F" 111 "orig: 144 / 0x90" 110 "orig: 145 / 0x91" 109 "orig: 146 / 0x92" 108 "orig: 147 / 0x93" 107 "orig: 148 / 0x94" 106 "orig: 149 / 0x95" 105 "orig: 150 / 0x96" 104 "orig: 151 / 0x97" 103 "orig: 152 / 0x98" 102 "orig: 153 / 0x99" 101 "orig: 154 / 0x9A" 100 "orig: 155 / 0x9B" 99 "orig: 156 / 0x9C" 98 "orig: 157 / 0x9D" 97 "orig: 158 / 0x9E" 96 "orig: 159 / 0x9F" 95 "orig: 160 / 0xA0" 94 "orig: 161 / 0xA1" 93 "orig: 162 / 0xA2" 92 "orig: 163 / 0xA3" 91 "orig: 164 / 0xA4" 90 "orig: 165 / 0xA5" 89 "orig: 166 / 0xA6" 88 "orig: 167 / 0xA7" 87 "orig: 168 / 0xA8" 86 "orig: 169 / 0xA9" 85 "orig: 170 / 0xAA" 84 "orig: 171 / 0xAB" 83 "orig: 172 / 0xAC" 82 "orig: 173 / 0xAD" 81 "orig: 174 / 0xAE" 80 "orig: 175 / 0xAF" 79 "orig: 176 / 0xB0" 78 "orig: 177 / 0xB1" 77 "orig: 178 / 0xB2" 76 "orig: 179 / 0xB3" 75 "orig: 180 / 0xB4" 74 "orig: 181 / 0xB5" 73 "orig: 182 / 0xB6" 72 "orig: 183 / 0xB7" 71 "orig: 184 / 0xB8" 70 "orig: 185 / 0xB9" 69 "orig: 186 / 0xBA" 68 "orig: 187 / 0xBB" 67 "orig: 188 / 0xBC" 66 "orig: 189 / 0xBD" 65 "orig: 190 / 0xBE" 64 "orig: 191 / 0xBF" 63 "orig: 192 / 0xC0" 62 "orig: 193 / 0xC1" 61 "orig: 194 / 0xC2" 60 "orig: 195 / 0xC3" 59 "orig: 196 / 0xC4" 58 "orig: 197 / 0xC5" 57 "orig: 198 / 0xC6" 56 "orig: 199 / 0xC7" 55 "orig: 200 / 0xC8" 54 "orig: 201 / 0xC9" 53 "orig: 202 / 0xCA" 52 "orig: 203 / 0xCB" 51 "orig: 204 / 0xCC" 50 "orig: 205 / 0xCD" 49 "orig: 206 / 0xCE" 48 "orig: 207 / 0xCF" 47 "orig: 208 / 0xD0" 46 "orig: 209 / 0xD1" 45 "orig: 210 / 0xD2" 44 "orig: 211 / 0xD3" 43 "orig: 212 / 0xD4" 42 "orig: 213 / 0xD5" 41 "orig: 214 / 0xD6" 40 "orig: 215 / 0xD7" 39 "orig: 216 / 0xD8" 38 "orig: 217 / 0xD9" 37 "orig: 218 / 0xDA" 36 "orig: 219 / 0xDB" 35 "orig: 220 / 0xDC" 34 "orig: 221 / 0xDD" 33 "orig: 222 / 0xDE" 32 "orig: 223 / 0xDF" 31 "orig: 224 / 0xE0" 30 "orig: 225 / 0xE1" 29 "orig: 226 / 0xE2" 28 "orig: 227 / 0xE3" 27 "orig: 228 / 0xE4" 26 "orig: 229 / 0xE5" 25 "orig: 230 / 0xE6" 24 "orig: 231 / 0xE7" 23 "orig: 232 / 0xE8" 22 "orig: 233 / 0xE9" 21 "orig: 234 / 0xEA" 20 "orig: 235 / 0xEB" 19 "orig: 236 / 0xEC" 18 "orig: 237 / 0xED" 17 "orig: 238 / 0xEE" 16 "orig: 239 / 0xEF" 15 "orig: 240 / 0xF0" 14 "orig: 241 / 0xF1" 13 "orig: 242 / 0xF2" 12 "orig: 243 / 0xF3" 11 "orig: 244 / 0xF4" 10 "orig: 245 / 0xF5" 9 "orig: 246 / 0xF6" 8 "orig: 247 / 0xF7" 7 "orig: 248 / 0xF8" 6 "orig: 249 / 0xF9" 5 "orig: 250 / 0xFA" 4 "orig: 251 / 0xFB" 3 "orig: 252 / 0xFC" 2 "orig: 253 / 0xFD" 1 "orig: 254 / 0xFE" 0 "orig: 255 / 0xFF" ;
VAL_ 2148466430 InvertedSA 129 "orig: 126 / 0x7E" 255 "orig: 0 / 0x0" 254 "orig: 1 / 0x1" 253 "orig: 2 / 0x2" 252 "orig: 3 / 0x3" 251 "orig: 4 / 0x4" 250 "orig: 5 / 0x5" 249 "orig: 6 / 0x6" 248 "orig: 7 / 0x7" 247 "orig: 8 / 0x8" 246 "orig: 9 / 0x9" 245 "orig: 10 / 0xA" 244 "orig: 11 / 0xB" 243 "orig: 12 / 0xC" 242 "orig: 13 / 0xD" 241 "orig: 14 / 0xE" 240 "orig: 15 / 0xF" 239 "orig: 16 / 0x10" 238 "orig: 17 / 0x11" 237 "orig: 17 / 0x12" 236 "orig: 19 / 0x13" 235 "orig: 20 / 0x14" 234 "orig: 21 / 0x15" 233 "orig: 22 / 0x16" 232 "orig: 23 / 0x17" 231 "orig: 24 / 0x18" 230 "orig: 25 / 0x19" 229 "orig: 26 / 0x1A" 228 "orig: 27 / 0x1B" 227 "orig: 28 / 0x1C" 226 "orig: 29 / 0x1D" 225 "orig: 30 / 0x1E" 224 "orig: 31 / 0x1F" 223 "orig: 32 / 0x20" 222 "orig: 33 / 0x21" 221 "orig: 34 / 0x22" 220 "orig: 35 / 0x23" 219 "orig: 36 / 0x24" 218 "orig: 37 / 0x25" 217 "orig: 38 / 0x26" 216 "orig: 39 / 0x27" 215 "orig: 40 / 0x28" 214 "orig: 41 / 0x29" 213 "orig: 42 / 0x2A" 212 "orig: 43 / 0x2B" 211 "orig: 44 / 0x2C" 210 "orig: 45 / 0x2D" 209 "orig: 46 / 0x2E" 208 "orig: 47 / 0x2F" 207 "orig: 48 / 0x30" 206 "orig: 49 / 0x31" 205 "orig: 50 / 0x32" 204 "orig: 51 / 0x33" 203 "orig: 52 / 0x34" 202 "orig: 53 / 0x35" 201 "orig: 54 / 0x36" 200 "orig: 55 / 0x37" 199 "orig: 56 / 0x38" 198 "orig: 57 / 0x39" 197 "orig: 58 / 0x3A" 196 "orig: 59 / 0x3B" 195 "orig: 60 / 0x3C" 194 "orig: 61 / 0x3D" 193 "orig: 62 / 0x3E" 192 "orig: 63 / 0x3F" 191 "orig: 64 / 0x40" 190 "orig: 65 / 0x41" 189 "orig: 66 / 0x42" 188 "orig: 67 / 0x43" 187 "orig: 68 / 0x44" 186 "orig: 69 / 0x45" 185 "orig: 70 / 0x46" 184 "orig: 71 / 0x47" 183 "orig: 72 / 0x48" 182 "orig: 73 / 0x49" 181 "orig: 74 / 0x4A" 180 "orig: 75 / 0x4B" 179 "orig: 76 / 0x4C" 178 "orig: 77 / 0x4D" 177 "orig: 78 / 0x4E" 176 "orig: 79 / 0x4F" 175 "orig: 80 / 0x50" 174 "orig: 81 / 0x51" 173 "orig: 82 / 0x52" 172 "orig: 83 / 0x53" 171 "orig: 84 / 0x54" 170 "orig: 85 / 0x55" 169 "orig: 86 / 0x56" 168 "orig: 87 / 0x57" 167 "orig: 88 / 0x58" 166 "orig: 89 / 0x59" 165 "orig: 90 / 0x5A" 164 "orig: 91 / 0x5B" 163 "orig: 92 / 0x5C" 162 "orig: 93 / 0x5D" 161 "orig: 94 / 0x5E" 160 "orig: 95 / 0x5F" 159 "orig: 96 / 0x60" 158 "orig: 97 / 0x61" 157 "orig: 98 / 0x62" 156 "orig: 99 / 0x63" 155 "orig: 100 / 0x64" 154 "orig: 101 / 0x65" 153 "orig: 102 / 0x66" 152 "orig: 103 / 0x67" 151 "orig: 104 / 0x68" 150 "orig: 105 / 0x69" 149 "orig: 106 / 0x6A" 148 "orig: 107 / 0x6B" 147 "orig: 108 / 0x6C" 146 "orig: 109 / 0x6D" 145 "orig: 110 / 0x6E" 144 "orig: 111 / 0x6F" 143 "orig: 112 / 0x70" 142 "orig: 113 / 0x71" 141 "orig: 114 / 0x72" 140 "orig: 115 / 0x73" 139 "orig: 116 / 0x74" 138 "orig: 117 / 0x75" 137 "orig: 118 / 0x76" 136 "orig: 119 / 0x77" 135 "orig: 120 / 0x78" 134 "orig: 121 / 0x79" 133 "orig: 122 / 0x7A" 132 "orig: 123 / 0x7B" 131 "orig: 124 / 0x7C" 130 "orig: 125 / 0x7D" 128 "orig: 127 / 0x7F" 127 "orig: 128 / 0x80" 126 "orig: 129 / 0x81" 125 "orig: 130 / 0x82" 124 "orig: 131 / 0x83" 123 "orig: 132 / 0x84" 122 "orig: 133 / 0x85" 121 "orig: 134 / 0x86" 120 "orig: 135 / 0x87" 119 "orig: 136 / 0x88" 118 "orig: 137 / 0x89" 117 "orig: 138 / 0x8A" 116 "orig: 139 / 0x8B" 115 "orig: 140 / 0x8C" 114 "orig: 141 / 0x8D" 113 "orig: 142 / 0x8E" 112 "orig: 143 / 0x8F" 111 "orig: 144 / 0x90" 110 "orig: 145 / 0x91" 109 "orig: 146 / 0x92" 108 "orig: 147 / 0x93" 107 "orig: 148 / 0x94" 106 "orig: 149 / 0x95" 105 "orig: 150 / 0x96" 104 "orig: 151 / 0x97" 103 "orig: 152 / 0x98" 102 "orig: 153 / 0x99" 101 "orig: 154 / 0x9A" 100 "orig: 155 / 0x9B" 99 "orig: 156 / 0x9C" 98 "orig: 157 / 0x9D" 97 "orig: 158 / 0x9E" 96 "orig: 159 / 0x9F" 95 "orig: 160 / 0xA0" 94 "orig: 161 / 0xA1" 93 "orig: 162 / 0xA2" 92 "orig: 163 / 0xA3" 91 "orig: 164 / 0xA4" 90 "orig: 165 / 0xA5" 89 "orig: 166 / 0xA6" 88 "orig: 167 / 0xA7" 87 "orig: 168 / 0xA8" 86 "orig: 169 / 0xA9" 85 "orig: 170 / 0xAA" 84 "orig: 171 / 0xAB" 83 "orig: 172 / 0xAC" 82 "orig: 173 / 0xAD" 81 "orig: 174 / 0xAE" 80 "orig: 175 / 0xAF" 79 "orig: 176 / 0xB0" 78 "orig: 177 / 0xB1" 77 "orig: 178 / 0xB2" 76 "orig: 179 / 0xB3" 75 "orig: 180 / 0xB4" 74 "orig: 181 / 0xB5" 73 "orig: 182 / 0xB6" 72 "orig: 183 / 0xB7" 71 "orig: 184 / 0xB8" 70 "orig: 185 / 0xB9" 69 "orig: 186 / 0xBA" 68 "orig: 187 / 0xBB" 67 "orig: 188 / 0xBC" 66 "orig: 189 / 0xBD" 65 "orig: 190 / 0xBE" 64 "orig: 191 / 0xBF" 63 "orig: 192 / 0xC0" 62 "orig: 193 / 0xC1" 61 "orig: 194 / 0xC2" 60 "orig: 195 / 0xC3" 59 "orig: 196 / 0xC4" 58 "orig: 197 / 0xC5" 57 "orig: 198 / 0xC6" 56 "orig: 199 / 0xC7" 55 "orig: 200 / 0xC8" 54 "orig: 201 / 0xC9" 53 "orig: 202 / 0xCA" 52 "orig: 203 / 0xCB" 51 "orig: 204 / 0xCC" 50 "orig: 205 / 0xCD" 49 "orig: 206 / 0xCE" 48 "orig: 207 / 0xCF" 47 "orig: 208 / 0xD0" 46 "orig: 209 / 0xD1" 45 "orig: 210 / 0xD2" 44 "orig: 211 / 0xD3" 43 "orig: 212 / 0xD4" 42 "orig: 213 / 0xD5" 41 "orig: 214 / 0xD6" 40 "orig: 215 / 0xD7" 39 "orig: 216 / 0xD8" 38 "orig: 217 / 0xD9" 37 "orig: 218 / 0xDA" 36 "orig: 219 / 0xDB" 35 "orig: 220 / 0xDC" 34 "orig: 221 / 0xDD" 33 "orig: 222 / 0xDE" 32 "orig: 223 / 0xDF" 31 "orig: 224 / 0xE0" 30 "orig: 225 / 0xE1" 29 "orig: 226 / 0xE2" 28 "orig: 227 / 0xE3" 27 "orig: 228 / 0xE4" 26 "orig: 229 / 0xE5" 25 "orig: 230 / 0xE6" 24 "orig: 231 / 0xE7" 23 "orig: 232 / 0xE8" 22 "orig: 233 / 0xE9" 21 "orig: 234 / 0xEA" 20 "orig: 235 / 0xEB" 19 "orig: 236 / 0xEC" 18 "orig: 237 / 0xED" 17 "orig: 238 / 0xEE" 16 "orig: 239 / 0xEF" 15 "orig: 240 / 0xF0" 14 "orig: 241 / 0xF1" 13 "orig: 242 / 0xF2" 12 "orig: 243 / 0xF3" 11 "orig: 244 / 0xF4" 10 "orig: 245 / 0xF5" 9 "orig: 246 / 0xF6" 8 "orig: 247 / 0xF7" 7 "orig: 248 / 0xF8" 6 "orig: 249 / 0xF9" 5 "orig: 250 / 0xFA" 4 "orig: 251 / 0xFB" 3 "orig: 252 / 0xFC" 2 "orig: 253 / 0xFD" 1 "orig: 254 / 0xFE" 0 "orig: 255 / 0xFF" ;
VAL_ 2148466430 InvertedEDP 1 "orig: 0x0" 0 "orig: 0x1" ;
VAL_ 2148466430 InvertedDP 1 "orig: 0x0" 0 "orig: 0x1" ;
VAL_ 2565799678 IndustryGroup 6 "Reserved for SAE" 7 "Reserved for SAE" 5 "IndustrialProcessCtrlStationary" 4 "Marine" 3 "Construction" 2 "Agricultural and Forestry" 1 "On-Highway" 0 "Global" ;
VAL_ 2565799678 Function 127 "Reserved" 126 "Reserved" 125 "Reserved" 124 "Reserved" 123 "Reserved" 122 "Reserved" 121 "Reserved" 120 "Reserved" 119 "Reserved" 118 "Reserved" 117 "Reserved" 116 "Reserved" 115 "Reserved" 114 "Reserved" 113 "Reserved" 112 "Reserved" 111 "Reserved" 110 "Reserved" 109 "Reserved" 108 "Reserved" 107 "Reserved" 106 "Reserved" 105 "Reserved" 104 "Reserved" 103 "Reserved" 102 "Reserved" 101 "Reserved" 42 "Water Pump Control" 41 "Lighting - Operator Controls" 40 "Seat Control" 39 "Ignition Control Module" 38 "Tire Pressure Control" 37 "Cab Controller" 36 "Pneumatic - System Controller" 35 "Suspension - System Controller" 34 "Hydraulic Pump Controller" 33 "System Monitor" 32 "Headway Controller" 31 "Propulsion Battery Charger" 30 "Management Computer" 29 "Virtual Terminal (in cab)" 28 "Off Vehicle Gateway" 27 "Power TakeOff (Secondary or Front)" 26 "Body Controller" 25 "Network Interconnect ECU" 24 "Vehicle Security" 23 "Vehicle Navigation" 22 "Aerodynamic Control" 21 "Cab Climate Control" 20 "Trip Recorder" 19 "Instrument Cluster" 18 "Suspension - Drive Axle" 17 "Suspension - Steer Axle" 16 "Steering Controller" 15 "Fuel System" 14 "Cruise Control" 13 "Retarder - Driveline" 12 "Retarder - Engine" 11 "Brakes - Drive Axle" 10 "Brakes - Steer Axle" 9 "Brakes - System Controller" 8 "Axle - Drive" 7 "Axle - Steering" 6 "Power TakeOff - (Main or Rear)" 5 "Shift Control/Console" 4 "Battery Pack Monitor" 3 "Transmission" 2 "Electric Propulsion Control" 1 "Auxiliary Power Unit (APU)" 0 "Engine" 100 "Reserved" 99 "Reserved" 98 "Reserved" 97 "Reserved" 96 "Reserved" 95 "Reserved" 94 "Reserved" 93 "Reserved" 92 "Reserved" 91 "Reserved" 90 "Reserved" 89 "Reserved" 88 "Reserved" 87 "Reserved" 86 "Reserved" 85 "Reserved" 84 "Reserved" 83 "Reserved" 82 "Reserved" 81 "Reserved" 80 "Reserved" 79 "Reserved" 78 "Fire Suppression System" 77 "Fuel Properties Sensor" 76 "Temperature Sensor" 75 "Supplemental Fan" 74 "Lubrication System" 73 "Rollover Detection Control" 72 "Coolant Valve Controller" 71 "Transfer Case Control" 70 "Auxiliary Regeneration Device" 69 "Engine Emission Aftertreatement System" 68 "Aftertreatment system gas measurement" 67 "Electrical System Controller" 66 "I/O Controller" 65 "Gas Flow Measurement" 64 "Endurance Braking" 63 "Engine Valve Controller" 62 "On-Board Diagnostic Unit" 61 "File Server/Printer" 60 "Cab Display" 59 "Starter" 58 "Fan Drive Control" 57 "Steering Column Unit" 56 "Communications Unit, Radio" 55 "Communications Unit, Satellite" 54 "Communications Unit, Cellular" 53 "Alternator/Charging System" 52 "Chassis Controller" 51 "Forward-Looking Collision Warning System" 50 "Auxiliary Heater" 49 "Clutch/Converter Control" 48 "Ramp Control" 47 "Information System Controller" 46 "Oil Sensor Unit" 45 "Vehicle Dynamic Stability Control" 44 "Exhaust Emission Control" 43 "Transmission Display" ;
VAL_ 2565799678 ManufacturerCode 900 "OSB AG" 899 "Lippert Components, Inc" 898 "Josef Kotte Landtechnik GmbH & Co. KG" 897 "Dot Technology Corp." 896 "NextFour Solutions Ltd" 895 "Peloton Technology" 894 "Rhodan Marine Systems of Florida LLC" 893 "KlinkTechnics Ltd." 892 "Mectronx Corp" 891 "CarrierWeb" 890 "L3 Technologies, Inc." 889 "SANY America Inc" 888 "Carma Systems Inc" 887 "Hyperdrive Innovation Limited" 886 "Hitachi Zosen Corporation" 885 "SICK Stegmann GmbH" 884 "Sure Grip Controls Inc." 883 "Swift Navigation, Inc." 882 "BHTronik GmbH & Co. KG" 881 "Sovema" 880 "Revision Military" 879 "PG Trionic, Inc." 878 "FOTON" 877 "SICK ATech GmbH" 876 "SUCO Robert Scheuffele GmbH & Co. KG" 875 "Salvarani S.r.l." 874 "MTA S.p.A." 873 "Garnet Instruments Ltd." 872 "Kählig Antriebstechnik GmbH" 871 "Superior Tech Inc" 870 "Textron Fleet Management" 869 "Intercomp" 868 "Data Panel Corp" 867 "Skeleton Technologies" 866 "Netradyne, Inc." 865 "MyEasyFarm" 864 "Streamline Transportation Technologies Inc." 863 "SMAG" 862 "Prospec Electronics" 861 "Adel System S.r.l." 860 "Michelin" 859 "Valor" 858 "Littelfuse" 857 "Zoomlion Heavy Industry NA, Inc" 856 "FarmFacts GmbH" 855 "Toshiba Infrastructure Systems & Solutions Corporation" 854 "GEMAC Chemnitz GmbH" 853 "Teledyne RESON B.V." 852 "Velvac Inc" 851 "Novotechnik Messwertaufnehmer OHG" 850 "Geoprospectors GmbH" 849 "MTS Maschinentechnik Schrode AG" 848 "ningupex" 1863 "Thomas G. Faria Co." 1862 "Sanshin" 1861 "Vector North America (formerly Vector Cantech)" 1860 "MMP" 1859 "Kvasar AB" 1858 "Litton" 1857 "Simrad" 1856 "Trimble" 1855 "Furuno USA" 1854 "Northstar Technologies" 1853 "Japan Radio Co" 1852 "Navionics" 1851 "RayMarine" 1850 "Seastar Solutions (formerly Teleflex)" 1569 "621 Technologies Inc." 1077 "Ymer Technology" 1076 "DOGA S.A." 1075 "Uniden America Corporation" 1074 "Kindhelm / Navigs Oy" 1073 "Manitou Equipment America LLC" 1072 "La Marche Manufacturing Company" 1071 "MACH SYSTEMS s.r.o." 1070 "Quick-teck Electronics Ltd" 1069 "Lithionics Battery LLC" 1068 "Zapi S.p.A." 1067 "Tecomec S.r.l." 1066 "Spot Zero Water" 1065 "CALYPSO Instruments" 1064 "Omnitech Robotics Inc." 1063 "SolSteer" 1062 "Marol Co Ltd" 1061 "Volvo Construction Equipment" 1060 "Scale-Tec" 1059 "Boatrax" 1058 "Bondioli & Pavesi SpA" 1057 "EquipmentShare" 1056 "Lithium Pros" 1055 "EXA Computing GmbH" 1054 "Schmotzer Hacktechnik GmbH & Co. KG" 1053 "Vetus Maxwell, Inc." 1052 "Pfreundt" 1051 "ProNav AS" 1050 "Spacenus GmbH" 1049 "S&S Cycle" 1048 "Agrivation UG" 1047 "Sonic Corporation" 1046 "Praxidyn" 1045 "CMR Group" 1044 "Xee" 1043 "Hyva" 1042 "engcon group" 1041 "EZ Lynk" 1040 "BPE Electronics Srl" 1039 "Liugong Dressta Machinery" 1038 "EMIT Technologies, Inc." 1037 "Dragonfly Energy Corp." 1036 "Bender GmbH & Co. KG" 1035 "Agres" 1034 "Siren Marine" 1033 "ECCO Safety Group" 1032 "SIMOL S.p.A." 1031 "Flintec UK Ltd." 1030 "Tume-Agri Oy" 1029 "The Marine Guardian LLC" 1028 "Autel Intelligent Technology Corp., Ltd" 1027 "Goldacres PTY LTD" 1026 "ZTR Control Systems, LLC" 1025 "eze System, Inc." 1024 "Inventus Power" 1023 "PEAK-System Technik GmbH" 1022 "ITC Inc" 1021 "Entratech Systems LLC" 1020 "Onyx Marine Automation s.r.l." 1019 "Codek Foundries" 1018 "Flex TTS" 1017 "Caldaro AB" 1016 "Röhren- und Pumpenwerk BAUER GmbH" 1015 "SECURITAG SAS" 1014 "Briri Maschinenbau GmbH" 1013 "Allochis E-Tec" 1012 "Rhodan Marine Systems of Florida LLC" 1011 "Soundmax Electronics Ltd" 1010 "Agricultural Industry Electronics Foundation e.V." 1009 "TouchTronics, Inc." 1008 "Lintest Systems LLC" 1007 "Maschinenfabrik Meyer-Lohne GmbH" 1006 "Proterra" 1005 "TSE Brakes, Inc." 1004 "Ultraflex SpA" 1003 "technotrans SE" 1002 "Kussmaul Electronics Co." 1001 "Cleral Inc." 1000 "Landmaschinen Wienhoff GmbH" 999 "TerraTroniq B.V." 998 "Transcell Technology Inc" 997 "Xenta Systems Srl" 996 "Eniquest Pty Ltd" 995 "Circuitlink Pty Ltd." 994 "Morris Industries Ltd." 993 "Alelion Energy Systems AB" 992 "MarineIOT LLC" 991 "Deutronic Elektronik GmbH" 990 "SAMSUNG SDI Co., Ltd." 989 "Flux-Geräte GmbH" 988 "Voith Turbo" 987 "Baltic Car Equipment" 986 "AAMP Global" 985 "NLR, LLC" 984 "E-T-A Elektrotechnische Apparate GmbH" 983 "Dezwaef NV" 982 "Briggs & Stratton Corporation" 981 "Kobelt Manufacturing Co. Ltd" 980 "Gussi Italia S.R.L." 979 "McHale" 978 "Canfield Connector" 977 "Emerson Electric Co." 976 "Derive Systems, Inc." 975 "Siemens AG" 974 "Pico Technology Limited" 973 "Zasso GmbH" 972 "Axion AG" 971 "B+B Smartworx" 970 "Jaboni Power Products, LLC" 969 "Blue Sea Systems" 968 "Cox Powertrain Limited" 967 "Moteck Electric Corp." 966 "VisibleFarm" 965 "Ro-Sys Software" 964 "AgroVIR Kft" 963 "Thomason Jones Company, LLC" 962 "Timbolier Industries, Inc." 961 "POK SAS" 960 "Vemcon GmbH" 959 "Cascade Corporation" 958 "NHK MEC Corporation" 957 "Sierra Wireless Inc" 956 "Piher Sensors & Controls S.A." 955 "Hottinger Baldwin (Suzhou) Electronic Measurement Technology Co., Ltd." 954 "Setec Pty Ltd" 953 "Curtiss-Wright" 952 "Tan Delta Systems Ltd" 951 "Exor International S.p.A." 950 "RE:Lab s.r.l." 949 "Škoda Electric a.s." 948 "Donix" 947 "Gerd Bär GmbH" 946 "Hydac Tecnologia Ltda" 945 "Equalizer AG" 944 "ZONTISA Marine SL" 943 "FISCHER AG Präzisionspindeln" 942 "Vogelsang GmbH & Co. KG" 941 "Navya" 940 "Dometal Oy" 939 "Warn Industries, Inc." 938 "LEVEL Systems" 937 "Precision Circuits Inc" 936 "Hi-tech Millennium" 935 "Meels GmbH & Co. KG" 934 "Farmobile, Inc." 933 "Delta Mobile Systems, Inc." 932 "Discover Battery" 931 "Enertec Marine Ltd" 930 "Ecotronix Corp." 929 "Jl Marine Systems, Inc." 928 "EAO Automotive GmbH & Co. KG" 927 "Saicon" 926 "Buhler Industries Inc." 925 "GW Lisk Company" 924 "PAS Peschak Autonome Systeme GmbH" 923 "ELTEK S.p.A." 922 "Terberg Benschop B.V." 921 "ROPA Fahrzeug- und Maschinenbau GmbH" 920 "MTD Consumer Group Inc." 919 "Furrion LLC" 918 "AMW Machine Control, Inc" 917 "Sentinel d.o.o." 916 "Turck Inc." 915 "Dosificacion y sistemas electronicos S.L. (DSE)" 914 "ZETOR TRACTORS a.s." 913 "Toyota Motor Corporation" 912 "Steyr Motors GmbH" 911 "Nautic-On" 910 "Hermann Paus Maschinenfabrik GmbH" 909 "Marines Co., Ltd." 908 "Chonbuk National University Department of Electronics" 907 "strautmann" 906 "MOBA AG" 905 "ASA Electronics" 904 "Equipment Safety Systems Pty. Ltd. (EQSS)" 903 "InMotion" 902 "Bucher Hydraulics" 901 "Zivan Srl" 847 "Oceanvolt" 846 "L3 Magnet-Motor" 845 "GMB Güstrower Maschinenbau GmbH" 844 "FELL AS" 843 "Hendrickson Truck Commercial Vehicle Systems" 842 "DigiDevice Srl" 841 "Agra-GPS" 840 "E.S.T.E. Srl" 839 "Indexator Rotator Systems AB" 838 "Teamsurv Ltd" 837 "Famic Technologies Inc." 836 "Signature4" 835 "PetTrack Ltd." 834 "Pioneer Microsystems, Inc." 833 "Electrum Automation AB" 832 "Heizomat Gerätebau-Energiesysteme GmbH" 831 "DOK-ING Ltd." 830 "Ultra Motion LLC" 829 "Drov Technologies, Inc." 828 "AgriBrink Inc." 827 "INmatix Technology Group Ltd" 826 "Lewmar Marine Inc" 825 "BPW Hungária" 824 "Undheim Systems AS" 823 "ACEINNA, Inc (formerly MEMSIC, Inc)" 822 "Bren-Tronics, Inc." 821 "Thorsen Teknik A/S" 820 "DIaLOGIKa Gesellschaft fuer angewandte Informatik mbH" 819 "Preco Electronics" 818 "HGNSS" 817 "TE Connectivity Sensor Solutions" 816 "UniStrong" 815 "FLIR Systems, Inc." 814 "Kronotech Srl (formerly Soltec Soluzioni Tecnologiche Srl)" 813 "Thales Suisse SA" 812 "Torch Technologies" 811 "Blue Water Desalination" 810 "Dutch Power Company" 809 "HMS Industrial Networks AB" 808 "RIMEX Supply Ltd." 807 "Schneider-Electric" 806 "Charge Automotive Ltd" 805 "Gundersen & Løken AS" 804 "ASA Electronics" 803 "Gill Sensors & Controls Limited" 802 "SPBI (Bj Technologie)" 801 "LOR Manufacturing Company Inc." 800 "Delta-Q Technologies" 799 "Stillwater Designs and Audio, Inc. - KICKER" 798 "Lumishore Ltd" 797 "Tides Marine" 796 "Canadian Automotive Industries Ltd" 795 "Broyda Enterprises Pty Ltd" 794 "Shihlin Electric & Engineering Corporation" 793 "James Fisher Prolec" 792 "Kostal Mexicana" 791 "AUTEC" 790 "VACALL" 789 "GRADALL" 788 "MoTeC Pty Ltd" 787 "Abertax Technologies Limited" 786 "Johnson Matthey Battery Systems" 785 "Fischer Panda GmbH" 784 "CM Automotive Systems, Inc." 783 "Loup Electronics Inc." 782 "AVR bv (formerly AVR bvba)" 781 "Poly-Planar LLC" 780 "AVID Technology Ltd" 779 "RLC Electronic Systems" 778 "Seakeeper Inc." 777 "Ocean Signal Ltd" 776 "HMI Systems LLC" 775 "ZIEHL-ABEGG Automotive GmbH" 774 "Taisho Corporation" 773 "Clarion Corporation of America" 772 "Blink Marine" 771 "Shaw Development, LLC" 770 "MONOSEM" 769 "Trombetta" 768 "Flores Automation, LLC" 767 "Alliance Wireless Technologies Inc." 766 "Epec Oy" 765 "GIGAVAC" 764 "Bednar FMT s.r.o." 763 "AT-Systems BVBA" 762 "ROJ s.r.l." 761 "MITA OLEODINAMICA S.p.A." 760 "Bernecker + Rainer Industrie Elektronik GmbH" 759 "Hydro-Gear" 758 "Banner Engineering Corp." 757 "IMPCO Technologies" 756 "Maschio Gaspardo S.P.A." 755 "Firefly Integrations" 754 "Parker Hannifin Corp., Automation Group" 753 "AIROD Technologies" 752 "Deep Sea Electronics Plc" 751 "Pacific Track" 750 "Joskin SA" 749 "Chart Inc." 748 "ISOTTA" 747 "Agratronix" 746 "SureFire Ag Systems, Inc." 745 "Cidra Corporate Services Inc." 644 "KUS USA" 643 "Bogballe A/S" 642 "Moog / Aspen Motion Technologies" 641 "Diverse Yacht Services" 640 "Power Solutions International" 639 "Startec s.r.l." 638 "KVH Industries, Inc." 637 "Bavaria Yachtbau GmbH" 636 "Divelbiss Corporation" 635 "Argo Tractors S.p.A." 634 "Rocky Research" 633 "TORC Robotics" 632 "Pepperl+Fuchs GmbH" 631 "Reltima" 630 "SmartDrive Systems Inc." 629 "Agri Info Design, Ltd." 628 "Falck Schmidt Defence Systems" 627 "Radio Ocean" 626 "AVL DiTEST GmbH" 625 "Global MRV Inc." 624 "Blackbox Machine Control Pty Ltd" 623 "Xirgo Technologies" 622 "Floyd Bell Inc" 621 "Hagie Manufacturing Company" 620 "Sevcon Ltd." 619 "Right Weigh Load Scales" 618 "Evrard SA" 617 "Zero Emission Vehicles" 616 "SMART-TEC s.r.o." 615 "Networkfleet, Verizon Telematics" 614 "ARLT Technologies GmbH" 613 "HKS Co., Ltd." 612 "Samwon IT" 611 "Esterline" 610 "Trail Tech" 609 "Walvoil S.p.A." 608 "Gale Banks Engineering" 607 "Knappco/Civacon" 606 "Intellian Technologies" 605 "Aventics GmbH" 604 "Indexator Rototilt Systems AB" 603 "Kereval" 602 "Nomad Digital Ltd." 601 "Navitas Systems" 600 "Aquatic AV" 599 "Spudnik Equipment Co, LLC" 598 "ABB Turbo Systems Ltd" 597 "Hydac Filter Systems GmbH" 596 "Brunelco Electronic Innovators B.V." 595 "CustomWare" 594 "Kongsberg Automotive" 593 "Sensata Technologies" 592 "tecsis GmbH" 591 "United States Coast Guard" 382 "National Agriculture and Food Research Organization" 381 "B & G" 380 "Suntech International Ltd." 379 "Yamabiko Corporation" 378 "Glendinning Marine Products" 377 "ifm electronic gmbh" 376 "Quake Global" 375 "Williams Controls Inc." 374 "Northern Lights, Inc." 373 "Electronic Design Inc." 372 "Delphi" 371 "Heinzmann GmbH & Co. KG" 370 "Rolls-Royce Marine AS" 369 "Power Torque Engineering Ltd" 368 "HANSENHOF_electronic" 367 "Fliegl Agrartechnik" 366 "Viewnyx Corp." 365 "Digi-Star, LLC" 364 "OEM Controls Inc." 363 "BEI Duncan" 362 "Poettinger Landtechnik GmbH (formerly Alois Poettinger Maschinenfabrik GmbH)" 361 "InMach" 360 "HJS Emission Technology GmbH & Co KG   (formerly HJS Fahrzeugtechnik GmbH & Co KG)" 359 "Ludwig Bergmann GmbH" 358 "Victron Energy B.V." 357 "Hardi International A/S" 356 "Fischer Panda Generators, Inc" 355 "Mastervolt International B.V." 354 "Junkkari OY" 353 "Hegemon Electronics, Inc." 352 "SAME DEUTZ-FAHR GROUP S.p.A." 351 "Thrane & Thrane" 350 "Noris Marine Systems GmbH & Co KG" 349 "Suonentieto" 348 "Amazonen Werke H. Dreyer" 347 "Honeywell" 346 "Control Solutions" 345 "Korean Maritime University" 344 "Parvus Corporation" 343 "Baumer Group" 342 "THOMAS MAGNETE GmbH" 341 "Boning GmbH & Co" 340 "Continental AG" 339 "Competence Center ISOBUS e.V." 338 "GRAF-SYTECO" 337 "Carraro S.p.A." 336 "APE s.r.o." 335 "Evo Electric Ltd" 334 "Takata-Petri AG" 333 "Hadley Products Corporation" 744 "Woosung Engineering Co., Ltd." 743 "Daemyung Elevator Co., Ltd." 742 "EROAD" 741 "Carling Technologies" 740 "e-Traction" 739 "LXNAV d.o.o." 738 "Blue Ink Technologies" 737 "Balluff GmbH" 736 "Terex Aerial Work Platforms - Genie" 735 "AEM Performance Electronics" 734 "REAPsystems" 733 "Intendia S.L." 732 "Gefran S.p.A." 731 "Modine Manufacturing Company" 730 "BERTHOUD AGRICOLE" 729 "Liebherr" 728 "Streumaster (formerly Streumaster / Panien)" 727 "Dhoot Transmission Pvt Ltd." 726 "MIDORI PRECISIONS" 725 "Hitachi Construction Machinery Co., Ltd." 724 "Electronic Applications, Inc." 723 "Jabil Inc." 722 "Contelec AG" 721 "Hypro" 720 "WITZ Corporation" 719 "Cojali S. L." 718 "Micronet Inc" 717 "Yacht Devices Ltd" 716 "Eaton Control & Power Conversion Division (CPCD)" 715 "Autonnic Research Ltd" 714 "Kobashi Kogyo Co., Ltd." 713 "US Hybrid Corporation" 712 "LOR Manufacturing Company Inc." 711 "DAS Co., LTD" 710 "Greentronics Ltd." 709 "Marquardt GmbH" 708 "Lars Thrane A/S" 707 "Rochester Gauges Inc" 706 "Shanghai Diesel Engine Corporation Limited" 705 "SVAB Hydraulik AB" 704 "JL Audio, Inc." 703 "Hydro Tab Marine Engineering" 702 "Weichai Power Co., Ltd." 701 "BigRoad Inc." 700 "K-Tec Earthmovers Inc." 699 "Harman International Industries" 698 "Scorpion Technologies Ltd." 697 "Ålö AB" 696 "DRS Network & Imaging Systems, LLC (DRS Technologies)" 695 "Weldon Technologies" 694 "GasTOPS Ltd." 693 "Agility Fuel Solutions (formerly Agility Fuel Systems)" 692 "Tanhay Corporation" 691 "Digitroll Agricultural Electronics" 690 "LINAK A/S" 689 "Aarcomm Systems Inc" 688 "Rockford Corp" 687 "Flight Systems, Inc." 686 "Taigene Electric Machinery Corp." 685 "ANEDO (formerly ANEDO Ltd.)" 684 "KEB" 683 "Fosen Elektro" 682 "Eckelmann AG" 681 "BEDIA Motorentechnik GmbH & Co. KG" 680 "AMVAC Chemical Corporation" 679 "Cimco Marine AB" 678 "KeepTruckin, Inc." 677 "DSA Daten- und Systemtechnik GmbH" 676 "Danfoss IXA A/S" 675 "Kawasaki Motors Corp., USA" 674 "Yara International ASA" 673 "Caruelle Nicolas" 672 "OPTIMA Concept" 671 "Innovative Controls Inc." 670 "STEMCO LP" 669 "Quantum Fuel Systems Technologies Worldwide, Inc" 668 "MacDon Industries Ltd." 667 "Bartec" 666 "Schaeffler Technologies AG & Co., KG" 665 "Gebr. Bode GmbH & Co. KG" 664 "Level Developments Ltd" 663 "Delta Systems, Inc" 662 "Kissling Elektrotechnik GmbH" 661 "SPAL Automotive S.r.l." 660 "Auto-Gaz Centrum" 659 "Data Panel Corp." 658 "Shenzhen Jiuzhou Himunication Technology Co., Ltd" 657 "Terzo Power Systems" 656 "PRO SOLUS do Brasil" 655 "Genge & Thoma AG" 654 "Kohler Power Systems, Detroit Engine Development Center (DEDC)" 653 "AEV, spol. s r. o." 652 "MicroControl GmbH & Co. KG" 651 "Takakita Co, Ltd." 650 "Seiko Epson Corp." 649 "Control-Q B.V." 648 "OJSC Ekran" 647 "Siloking" 646 "Veenhuis Machines B.V." 645 "esd electronic system design gmbh" 590 "ARGO-HYTOS GMBH" 589 "MICO, Inc." 588 "Vignal Systems" 587 "JCA Electronics" 586 "Suzuki Motor Corp" 585 "Industrial Electronic Controls" 584 "CarMedialab GmbH" 583 "Yachtcontrol" 582 "Innovative Software Engineering" 581 "Väderstad - Verken AB" 580 "San Jose Technology, Inc." 579 "KVH Industries, Inc." 578 "advanSea" 577 "Denchi Power Ltd  (formerly ABSL Power Solutions Limited)" 576 "Vectia" 575 "Lytx" 574 "Vishay Precision Group" 573 "Orolia Ltd" 572 "Fasse Valves" 571 "Marinecraft Co., Ltd." 570 "frenzel + berg electronic GmbH & Co. KG" 569 "LORD MicroStrain Sensing Systems" 568 "Makersan Ltd. Co." 567 "Lithiumstart LLC" 566 "Geode Technology, Inc." 565 "Micro-Trak Systems, Inc." 564 "Auto Power Electronic" 563 "LOHR Sistemas Eletronicos LTDA" 562 "Bombardier Transportation GmbH" 561 "b-plus GmbH" 560 "Iowa State University, Agricultural and Biosystems Engineering" 559 "Four Peaks Navigation" 558 "Davis Instruments Corp." 557 "Rockson Automation GmbH" 556 "Doosan Infracore Norway" 555 "Sasaki Corporation" 554 "iris-GmbH infrared & intelligent sensors" 553 "KIB Electronics" 552 "Matsuyama Plow Mfg Co, Ltd" 551 "Wexler CSD Ltd." 550 "SUN-A Corporation" 549 "ROAD Deutschland GmbH" 548 "TM4 Inc." 547 "Thomson Linear LLC" 546 "Maruyama Mfg Co, Inc." 545 "GS Hydraulics" 544 "Au Group Electronics" 543 "BAUER Maschinen GmbH" 542 "Dinamica Generale s.p.a." 541 "Total Fire Systems, Inc." 540 "Dinex A/S" 539 "Mobileview" 538 "Crop Ventures, Inc." 537 "Schrader Electronics Ltd." 536 "SSI Technologies" 535 "MOTORPAL, a.s." 534 "Webasto Thermo & Comfort SE" 533 "Doran Manufacturing, LLC" 532 "Onwa Marine Electronics Co Ltd." 531 "Genge & Thoma AG" 530 "NMEA" 529 "National Instruments Korea" 528 "Hoganas AB, Electric Drive Systems" 527 "GKN Walterscheid GmbH" 526 "LOFA Industries, Inc" 525 "Rust Sales INC" 524 "Vomax Instrumentation Pty. Ltd." 523 "Reggio Emilia Innovazione" 522 "Nebraska Tractor Test Laboratory" 521 "Clever Devices Ltd." 520 "Trapeze" 519 "Peeters Landbouwmachines b.v." 518 "Transas USA Inc." 517 "Noland Engineering" 516 "AVAT Automation GmbH" 515 "GINAF Trucks Nederland B.V." 514 "DISTek Integration, Inc." 513 "Precision Technology (Formerly FarmscanAg)" 512 "Inpower LLC" 511 "Sulky" 510 "Marinesoft Co. Ltd" 509 "MOTORTECH GmbH" 508 "Transtech Innovations" 507 "ISOBUS Test Center" 506 "IHI STAR Machinery Corporation" 505 "Yetter Farm Equipment" 504 "Vesper Marine" 503 "Naviop S.R.L." 502 "Attwood Corporation" 501 "Agrotronix S.A." 500 "Oxbo International Corporation" 499 "LCJ Capteurs" 498 "Innovative Design Solutions, Inc." 497 "SENTRON Sistemas Embarcados" 496 "W. Gessmann GmbH" 495 "HOLMER Maschinenbau GmbH" 494 "Synerject" 493 "Watcheye" 492 "Inergy Automotive Systems" 491 "Penny and Giles Ltd" 490 "QuikQ" 489 "Appareo Systems, LLC" 488 "The Charles Machine Works, Inc." 487 "DSE Test Solutions A/S" 486 "Westport Innovations Inc." 485 "MATT automotive" 484 "Headsight Inc." 483 "Valeo" 482 "Tricon Electronics" 481 "Chetco Digital Instruments" 480 "EnerDel, Inc." 479 "Vapor Bus International" 478 "OceanSat B.V." 477 "OilQuick AB" 476 "Hummingbird Marine Electronics" 475 "GME" 474 "Persen Technologies Inc." 473 "Boss Industries, Inc." 472 "Tenneco Inc." 471 "Sea Cross Marine AB" 470 "SI-TEX Marine Electronics" 469 "RA Consulting GmbH" 468 "Tyco Fire Protection Products" 467 "Lely Industries N.V." 466 "Veethree Electronics and Marine LLC" 465 "Ashcroft Inc" 464 "Leach International Corporation" 463 "PROBOTIQ" 462 "IHI Shibaura Machinery Corporation" 461 "HAWE Hydraulik SE" 460 "San Giorgio S.E.I.N." 459 "Alltek Marine Electronics Corp" 458 "Control Solutions, Inc." 457 "RUSELPROM-ElectricDrive Ltd" 456 "General Kinetics" 455 "ADZ NAGANO GmbH" 454 "NGK Spark Plug Co. Ltd" 453 "Cooper Bussmann" 452 "WIKA Alexander Wiegand SE & Co. KG" 451 "Parker Hannifin Corp" 450 "Dycor Technologies Ltd." 449 "Polaris Industries Inc" 448 "Stanadyne Corporation, Electronics Systems" 447 "Great Plains Mfg." 446 "CertTech, L.L.C." 445 "KAT MECHATRONIC, Electronic Product Division" 444 "ITT Power Solutions" 443 "SignalQuest, Inc." 442 "Horsch Maschinen GmbH" 441 "PTG Reifendruckregelsysteme GmbH" 440 "Cummins Power Generation" 439 "Hyundai Heavy Industries" 438 "Comar Systems Ltd" 437 "Digital Yacht Limited" 436 "Kinze Manufacturing" 435 "Zunhammer GmbH" 434 "Stored Energy Systems" 433 "Rowe Electronics" 432 "S&A Systems, Inc." 431 "Tohatsu Corporation" 430 "Auteq Telematica S.A." 429 "Rota Engineering Ltd." 425 "Methode Electronics Inc, MDI" 424 "Odyne LLC" 423 "BSM Wireless, Inc." 422 "True Heading AB" 421 "Vertex Standard Co, Ltd" 420 "Vermeer Corporation, ACS Group" 419 "Fusion Electronics Ltd" 418 "Intellistick Inc" 417 "KZValve" 416 "Kubota Corporation" 415 "Valid Manufacturing Ltd." 414 "Cattron Group International" 413 "Datapross Nijbroek bv" 412 "WebTech Wireless Inc." 411 "Hy-Drive Technologies Ltd." 410 "COBO S.p.A. Divisione 3B6" 409 "Transfluid S.r.L." 408 "Corvus Energy Ltd." 407 "Comtech Mobile Datacom" 406 "Vecima Networks Inc." 405 "Wema System AS" 404 "Com Nav Marine Ltd" 403 "Trackwell ADS, Inc." 402 "Simma Software, Inc." 401 "Torqeedo GmbH" 400 "Livorsi Marine" 399 "ISEKI & Co., Ltd." 398 "Hilite International" 397 "Sanyo-kiki Co Ltd." 396 "Beyond Measure" 395 "GENTEC S.R.L." 394 "Capi 2 Nederland B.V." 393 "Harvest Tec, Inc" 392 "Tianyuan Technology Co Ltd." 391 "Electronic Design for Industry, Inc" 390 "Partech Inc." 389 "Benchmark Electronics, Minnesota Division" 388 "Innomatix, LLC" 387 "Orscheln Products, LLC" 386 "JLG Automation BVBA" 385 "Johnson Outdoor Marine Electronics" 384 "Camano Light" 383 "MCL Industries" 332 "HWH Corporation" 331 "Horton, Inc." 330 "Kidde Aerospace and Defense" 329 "Deif A/S" 328 "Qwerty Electronik AB" 327 "Sonceboz SA" 326 "Akron Brass Company" 325 "ASM Automation Sensorik Messtechnik GmbH" 324 "Snap-on Diagnostics" 323 "Mobileye Vision Technologies Ltd." 322 "MICHENKA s.r.o." 321 "Ultra Electronics, Electrics" 320 "Miedema Landbouwwerktuigenfabriek B.V." 319 "Cadec Global" 318 "SAT Plan" 317 "Navtronics Bvba" 316 "ITT Flow Control" 315 "Icom Incorporated" 314 "CSM GmbH" 313 "Ilmor Engineering, Inc." 312 "Lectronix, Inc." 311 "Patrick Power Products" 310 "TECNORD srl" 309 "Krauss-Maffei Wegmann GmbH & Co. KG" 308 "Cyntrx" 307 "MAS Technologies" 306 "Sleipner Motor AB" 305 "NovAtel Inc" 304 "EmpirBus AB" 303 "CTS Corporation" 302 "Nissin Kogyo Co., LTD" 301 "Parker Hannifin (UK) Ltd FDE group" 300 "Systron Donner Automotive" 299 "Rauch" 298 "Holley Performance" 297 "Zonar Systems Inc" 296 "micro dynamics GmbH" 295 "BEP Marine" 294 "Grayhill Inc." 293 "Spyder Controls Corp." 292 "IKUSI - Angel Iglesias S.A." 291 "Groeneveld Transport Efficiency BV" 290 "Kuebler GmbH" 289 "Watlow" 288 "Mitsubishi FUSO Truck & Bus Corp." 287 "NTech Industries, Inc" 286 "Coelmo srl" 285 "Sea Recovery Corp" 284 "Mobile Tech Chile" 283 "CWF Hamilton & Co Ltd" 282 "Medallion Instrumentation Systems" 281 "Precision Governors LLC" 280 "Leica Geosystems Pty Ltd" 279 "Geometris LP" 278 "Takata Electronics" 277 "LHP Telematics" 276 "Aqua-Hot Heating Systems" 275 "Navico Egersund AS" 274 "LTW Technology Co., LTD" 273 "Active Research Limited" 272 "Gross Mechanical Laboratories, Inc" 271 "Cole Hersee" 270 "Tennant" 269 "Saft America Inc.,  Space & Defense Division" 268 "Accurate Technologies" 267 "Red Lion Controls, Inc" 266 "International Thermal Research Ltd" 265 "MTS Sensor Technologie GmbH" 264 "Autolync" 263 "IMMI" 262 "HydraForce, Inc" 261 "Red Dot Corporation" 260 "Reichhardt GmbH Steuerungstechnik" 259 "Jetter AG" 258 "ARAG" 257 "Honda Motor Co., Ltd" 256 "Tyco Electronics AMP" 255 "MEAS France" 254 "GE Sensing" 253 "Mobile Control Systems" 252 "Sensor-Technik Wiedemann GmbH" 251 "German Agricultural Society, Test Center (DLG)" 250 "Kuhn Group" 249 "Schaltbau GmbH" 248 "Cooper Standard Automotive Active Systems Group" 247 "ePULSE" 246 "Class 1, Inc" 245 "Capstan Ag Systems, Inc." 244 "Techno-Matic" 243 "eRide, Inc." 242 "Kokusandenki Co. Ltd" 241 "Schneider Automation SAS" 240 "Vanair Mfg" 239 "May & Scofield Ltd" 238 "ZF Friedrichshafen AG" 237 "Agtron Enterprises Inc" 236 "NORAC Systems International Inc" 235 "SailorMade Marine Telemetry - Tetra Technology Ltd." 234 "Mondial electronic GmbH" 233 "Yacht Monitoring Solutions Inc." 232 "TSD Integrated Controls" 231 "Topcon Positioning Systems, Inc." 230 "Saucon Technologies" 229 "Garmin International Inc." 228 "Unused (formerly ZF Marine Electronics)" 227 "Lykketronic A/S" 226 "Monaco Coach Corporation" 225 "SKF" 224 "EMMI Network, S.L." 223 "Vaueo Retarder Co., Ltd." 222 "Generac Power Systems, Inc." 221 "SiE" 220 "Beede Electrical Instrument Company, Inc" 219 "Cat OEM Solutions" 218 "Gits Manufacturing Company" 217 "RM Michaelides Software & Elektronik GmbH" 216 "Paneltronics Inc." 215 "Aetna Engineering/Fireboy-Xintex" 214 "MC elettronica Srl" 213 "CNH Belgium N.V." 212 "Sure Power Industries, Inc" 211 "DNA Group" 210 "Iteris, Inc." 209 "Bell Equip. Co. SA (PTY) LTD" 208 "Drew Technologies, Inc" 207 "Otto Engineering" 206 "port GmbH" 205 "SmarTire Systems Inc" 204 "The Morey Corporation" 203 "MILtronik GmbH" 202 "Curtis Instruments, Inc" 201 "Disenos y Tecnologia S.A." 200 "MGM Brakes" 199 "ACTIA Group (formerly Actia Corp)" 198 "Mystic Valley Communications" 197 "Mechron Power Systems" 196 "LEMKEN GmbH & Co KG" 195 "General Engine Products" 194 "TriMark Corporation" 193 "Jeppesen Marine" 192 "Floscan" 191 "XRS Corporation (formerly XATA Corporation)" 190 "Hella KGaA Hueck & Co" 189 "QUALCOMM" 188 "EMP Corp" 187 "Air-Weigh" 186 "Altronic, Inc" 185 "Beede Electrical Instrument Company" 184 "EIA Electronics" 183 "KDS Controls, Inc" 182 "Vehicle Systems Engineering B.V." 181 "Coretronics, Inc." 180 "Smart Power Systems" 179 "TeeJet Technologies Springfield (formerly Midwest Technologies Illinois, LLC)" 178 "Continental Automotive GmbH (formerly Siemens VDO Automotive AG)" 177 "Diagnostic Systems Associates" 176 "Moritz Aerospace" 175 "Veris Technologies, Inc." 174 "AB Volvo Penta" 173 "Ryeso, Inc." 172 "Yanmar Co., Ltd. (formerly Yanmar Marine USA)" 171 "Topcon Electronics GmbH & Co. KG (formerly Wachendorff Elektronik GmbH & Co. KG)" 170 "Computronics Corporation Ltd." 169 "Marlin Technologies Inc." 168 "Xantrex" 167 "JLG Industries Inc" 166 "John Deere Electronic Solutions (formerly Phoenix International)" 165 "CPAC Systems AB" 164 "MTU Friedrichshafen GmbH (formerly DaimlerChrysler Off-Highway)" 163 "BRP Inc." 162 "Axiomatic Technologies" 161 "Offshore Systems (UK) Ltd" 160 "Nido" 159 "NTech Industries Inc" 158 "Firestone Industrial Products Company" 157 "ISSPRO Inc." 156 "ITT Industries - Cannon" 155 "Vetronix Corporation" 154 "Westerbeke Corporation" 153 "Woodward, Industrial Controls Division" 152 "elobau GmbH & Co. KG" 151 "Raven Industries, Inc." 150 "Fleetguard" 149 "Holset" 148 "Blue Water Data, Inc." 147 "Nautibus electronic GmbH" 146 "Maxima Technologies" 145 "MurCal Controls" 144 "Mercury Marine" 143 "W. Gmeiner GmbH & Co." 142 "TRW Automotive (Commercial Steering Systems)" 141 "Thales Navigation Ltd." 140 "Lowrance Electronics, Inc." 139 "Caterpillar Trimble Control Technologies (CTCT), LLC" 138 "Georg Fritzmeier GmbH & Co. KG" 137 "Maretron" 136 "Komatsu Ltd" 135 "Airmar Technology Corporation" 134 "Iris Technology Ltd" 133 "Bucher Schoerling GmbH" 132 "Mulag-Fahrzeugwerk" 131 "ITT Industries" 130 "Nido - Universal Machines B.V." 129 "OMNEX Control Systems Inc." 128 "Gerhard Duecker GmbH & Co. KG" 127 "Holland USA" 126 "Driver Tech" 125 "Nevada Automotive Test Center" 124 "Hydac Electronic" 123 "Basler Electric" 122 "FG Wilson (Engineering) Limited" 121 "HED (Hydro Electronic Devices, Inc.)" 120 "RDS Technology Ltd" 119 "IntegriNautics  " 118 "Intron GmbH" 117 "HUSCO International" 116 "BEELINE Technologies" 115 "NACCO Materials Handling Group, Inc." 114 "EControls, Inc." 113 "Stress-Tek, Inc." 112 "MECALAC" 111 "Bernard Krone Holding SE & Co. KG (formerly Maschinenfabrik Bernard Krone GmbH)" 110 "EPIQ Sensor-Nite" 109 "TeeJet Technologies Denmark (formerly LH Technologies ApS)" 108 "WTK-Elecktronik GmbH" 107 "Grimme Landmaschinen GmbH & Co. KG" 106 "BAE Systems Controls, Inc." 105 "Kiepe Elektrik GmbH & Co. KG" 104 "CLAAS KGaA mbH (formerly CLAAS Selbstfahrende Erntemaschinen GmbH)" 103 "CLAAS E-Systems GmbH (formerly CLAAS E-Systems KGaA mbH & Co. KG)" 102 "AGCO (formerly AGCO GmbH & Co.)" 101 "Sensoria" 100 "VDO Technik AG" 99 "International Transmissions Ltd (ITL)" 98 "Mueller-Elektronik GmbH & Co" 97 "Ag Leader Technology, Inc." 96 "Mech@tronic IT GmbH" 95 "Pacific Insight Electronics Corp." 94 "CNH Industrial N.V. (formerly CNH Global N.V.)" 93 "Perkins Engines Company Ltd." 92 "Ag-Chem Equipment Co., Inc." 91 "BSG Bodensee Steuergeraete GmbH" 90 "Knorr-Bremse SfN GmbH" 89 "Kverneland Group, Electronics Division" 88 "Hemisphere GPS Inc (formerly Satloc Precision GPS)" 87 "J.C. Bamford Excavators Ltd (JCB)" 86 "C. E. Niehoff & Company" 85 "Kohler Co" 84 "New Holland UK Limited" 83 "Bendix VORAD Technologies (formerly Eaton VORAD Technologies)" 82 "Bobcat/Ingersoll-Rand (formerly Melroe/Ingersoll-Rand)" 81 "Fire Research Corp." 80 "Twin Disc, Inc." 79 "Daimler Benz AG - Engine Division (PBM)" 78 "Frank W. Murphy Manufacturing, Inc" 77 "Deere Power Systems Group" 76 "unused (formerly Deere & Co, Construction Division)" 75 "Deere & Co, Agricultural Division" 74 "Eaton Axle-Brake Division" 73 "LeTourneau, Inc." 72 "Sisu Corporation" 71 "Vansco Electronics Ltd." 70 "Flex-coil Limited" 69 "Trimble Navigation" 68 "Scania" 67 "John Deere Coffeyville Works (formerly Funk Manufacturing Company)" 66 "John Deere Construction Equipment Division" 65 "MAN Nutzfahrzeuge AG" 64 "Unused (formerly SpectraPrecision Laserplane, then SpectraPhysics)" 63 "ZF Industries Inc." 62 "Wabco" 61 "Volvo Truck Corp." 60 "Volvo Trucks North America Inc." 59 "VES Inc." 58 "SPX Corporation, OTC Div" 57 "Danfoss  (formerly Sauer Sundstrand Co, then Sauer-Danfoss Co)" 56 "SAIC" 55 "Ryder System Inc." 54 "Meritor Wabco" 53 "Continental Automotive Systems US, Inc. (formerly Rockwell Land Transportation)" 52 "Meritor Automotive, Inc. (formerly Rockwell Automotive)" 51 "Robert Bosch GmbH" 50 "Robert Bosch Corp" 49 "RE America Inc." 48 "Pollak Alphabet" 47 "Phillips Semiconductor" 46 "Noregon Systems, Inc  (formerly Parasoft Computing Solutions)" 45 "PACCAR" 44 "Nippondenso Co. Ltd." 43 "International Truck and Engine Corporation - Vehicle Electronics (formerly Navistar Intl Trans Corp.)" 42 "International Truck and Engine Corporation - Engine Electronics  (formerly Navistar Intl Trans Co., Engine Electronics)" 41 "Motorola Inc." 40 "Motorola AIEG Inc." 39 "Microfirm Inc." 38 "Micro Processor Systems Inc." 37 "Mack Trucks Inc." 36 "Lucas Ind." 35 "Kenworth Truck Co." 34 "Kelsey Hayes Co." 33 "John Deere" 32 "Jacobs Vehicle Systems" 31 "J Pollak Corp" 30 "Isuzu Motors Ltd" 29 "Hino Motors Ltd." 28 "Grote Ind. Inc." 27 "GMC" 26 "General Motors Corp, Service Technology Grp" 25 "Daimler Trucks North America LLC (formerly Freightliner LLC)" 24 "Ford Motor Co., Vehicle Controls" 23 "Ford Motor Co., Heavy Truck" 22 "Ford Motor Co., Electronic Concepts & Systems" 21 "Echlin Inc., Midland Brake Inc." 20 "Eaton Ltd" 19 "Eaton Corp. Trucking Info Services" 18 "Eaton Corp, Transmission Div." 17 "Eaton Corp, Corp Res & Dev" 16 "Eaton Corp" 15 "DICKEY-john Corporation" 14 "Detroit Diesel Corporation" 13 "Delco Electronics" 12 "Deere & Company, Precision Farming" 11 "Dearborn Group Inc." 10 "Cummins Inc (formerly Cummins Engine Co)" 9 "Chrysler Corp." 8 "Caterpillar Inc." 7 "Case Corp." 6 "Berifors Electronics AB" 5 "AMP Inc." 4 "Ametek-Dixson" 3 "Ametek, US Gauge Division" 2 "Allison Transmission, Inc." 1 "Bendix Commercial Vehicle Systems LLC (formerly Allied Signal Inc.)" 0 "Reserved" ;
VAL_ 2565799678 VehicleSystem 0 "Non-specific System" 127 "Not Available" ;
VAL_ 2565799678 VehicleSystem5 127 "Not Available" 0 "Ind. Process Control Stationary" ;
VAL_ 2565799678 VehicleSystem4 125 "Entertainment" 120 "Display" 85 "External Environment" 75 "Sensor Communication Interface" 35 "Electrical Generation" 100 "Deck, Cargo and Fishing Equipment" 90 "Internal Environment" 80 "Instrumentation/General Systems (deprecate)" 70 "Communications" 60 "Navigation" 50 "Propulsion" 40 "Steering and Control Surfaces" 30 "Electrical Distribution" 25 "Inter/Intranetwork Device" 20 "Safety Systems" 10 "System Tools" 127 "Not Available" 0 "Non-specific System" ;
VAL_ 2565799678 VehicleSystem3 8 "Grader" 7 "Four Wheel Drive Loader" 6 "Forklift" 5 "Excavator" 4 "Crawler" 3 "Backhoe" 2 "Articulated Dump Truck" 1 "Skid Steer Loader" 127 "Not Available" 0 "Non-specific System" ;
VAL_ 2565799678 VehicleSystem2 25 "Slurry Applicators" 24 "Utility Vehicles" 23 "Mulchers" 22 "Timber Processing Machines" 21 "Timber loaders" 20 "Forwarders" 19 "Timber Harvesters" 17 "Sensor Systems" 16 "Skidder" 15 "Earth Work" 14 "Special Crops" 13 "Powered Auxiliary Device" 12 "Farm Yard Operations" 11 "Transport/Trailer" 10 "Irrigation" 9 "Forage" 8 "Root Harvesters" 7 "Harvesters" 6 "Sprayers" 5 "Fertilizers" 4 "Planters/Seeders" 3 "Secondary Tillage" 2 "Tillage" 1 "Tractor" 127 "Not Available" 0 "Non-specific System" ;
VAL_ 2565799678 VehicleSystem1 2 "Trailer" 1 "Tractor" 127 "Not Available" 0 "Non-specific System" ;
